VERSION ""

NS_ :

BS_:

BU_: CHUD_LS VKM_LS RCRM_LS MSM_RR_LS MSM_LR_LS CGM_LS BSM_LS VPM_LS ISRVM_LS DCAC_LS TouchPad_LS RSC_LS LVMPC_LS EOCM2B_K1_LS EOCM2A_K1_LS LCM_LS TIM_B_LS V2V_LS TCP_LS CSM_LS EOCM2B_K2_LS EOCM2A_K2_LS TIM_A_LS LVMNav_LS HFP_LS EDI_LS ARB_LS RSE_LS Dummy_LS VIS2_LS ICS_LS FCM_LS EOCM_F_LS VICM_LS AGC_LS MSM_P_LS OTIM_LS HVSM_R_LS HVSM_F_LS DVB_T_LS SBZA_R_LS PSD_R_LS PSD_L_LS UHP_Low UPA_LS STC_LS SBZA_L_LS PTM_LS ONSTAR_LS APA_LS TestTool_LS PHS_LS PDIM_LS CHM_LS RSA_LS AMP_LS HUD_LS MSM_LS HBSM_LS SCL_LS ECC_LS RadioHead_LS PEPS_LS IPC_LS AOS_LS SDM_LS TIM_LS BCM_LS

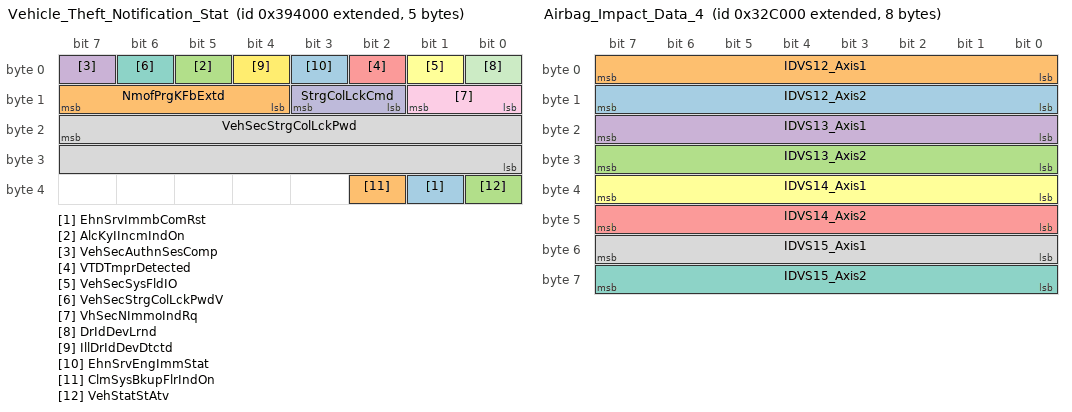
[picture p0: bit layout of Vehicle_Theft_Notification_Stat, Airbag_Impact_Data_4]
BO_ 2151235584 Vehicle_Theft_Notification_Stat: 5 BCM_LS
 SG_ EhnSrvImmbComRst : 33|1@0+ (1,0) [0|1] ""  TCP_LS,CGM_LS,ONSTAR_LS
 SG_ NmofPrgKFbExtd : 15|4@0+ (1,0) [0|15] ""  CGM_LS,PEPS_LS,IPC_LS
 SG_ AlcKyIIncmIndOn : 5|1@0+ (1,0) [0|1] ""  CGM_LS,IPC_LS
 SG_ VehSecAuthnSesComp : 7|1@0+ (1,0) [0|1] ""  TCP_LS,CGM_LS,ONSTAR_LS
 SG_ VTDTmprDetected : 2|1@0+ (1,0) [0|1] ""  TCP_LS,CGM_LS,ONSTAR_LS
 SG_ VehSecSysFldIO : 1|1@0+ (1,0) [0|1] ""  CGM_LS,IPC_LS
 SG_ VehSecStrgColLckPwdV : 6|1@0+ (1,0) [0|1] ""  CGM_LS,SCL_LS
 SG_ VehSecStrgColLckPwd : 23|16@0+ (1,0) [0|65535] ""  CGM_LS,SCL_LS
 SG_ VhSecNImmoIndRq : 9|2@0+ (1,0) [0|3] ""  CGM_LS,IPC_LS
 SG_ StrgColLckCmd : 11|2@0+ (1,0) [0|3] ""  CGM_LS,SCL_LS
 SG_ DrIdDevLrnd : 0|1@0+ (1,0) [0|1] ""  TCP_LS,CGM_LS,ONSTAR_LS
 SG_ IllDrIdDevDtctd : 4|1@0+ (1,0) [0|1] ""  TCP_LS,CGM_LS,ONSTAR_LS
 SG_ EhnSrvEngImmStat : 3|1@0+ (1,0) [0|1] ""  TCP_LS,CGM_LS,ONSTAR_LS
 SG_ ClmSysBkupFlrIndOn : 34|1@0+ (1,0) [0|1] ""  CGM_LS,IPC_LS
 SG_ VehStatStAtv : 32|1@0+ (1,0) [0|1] ""  CGM_LS,PEPS_LS

BO_ 2150809600 Airbag_Impact_Data_4: 8 SDM_LS
 SG_ IDVS12_Axis2 : 15|8@0- (1,0) [-128|127] "counts"  TCP_LS,CGM_LS,ONSTAR_LS
 SG_ IDVS12_Axis1 : 7|8@0- (1,0) [-128|127] "counts"  TCP_LS,CGM_LS,ONSTAR_LS
 SG_ IDVS13_Axis2 : 31|8@0- (1,0) [-128|127] "counts"  TCP_LS,CGM_LS,ONSTAR_LS
 SG_ IDVS13_Axis1 : 23|8@0- (1,0) [-128|127] "counts"  TCP_LS,CGM_LS,ONSTAR_LS
 SG_ IDVS14_Axis2 : 47|8@0- (1,0) [-128|127] "counts"  TCP_LS,CGM_LS,ONSTAR_LS
 SG_ IDVS14_Axis1 : 39|8@0- (1,0) [-128|127] "counts"  TCP_LS,CGM_LS,ONSTAR_LS
 SG_ IDVS15_Axis2 : 63|8@0- (1,0) [-128|127] "counts"  TCP_LS,CGM_LS,ONSTAR_LS
 SG_ IDVS15_Axis1 : 55|8@0- (1,0) [-128|127] "counts"  TCP_LS,CGM_LS,ONSTAR_LS

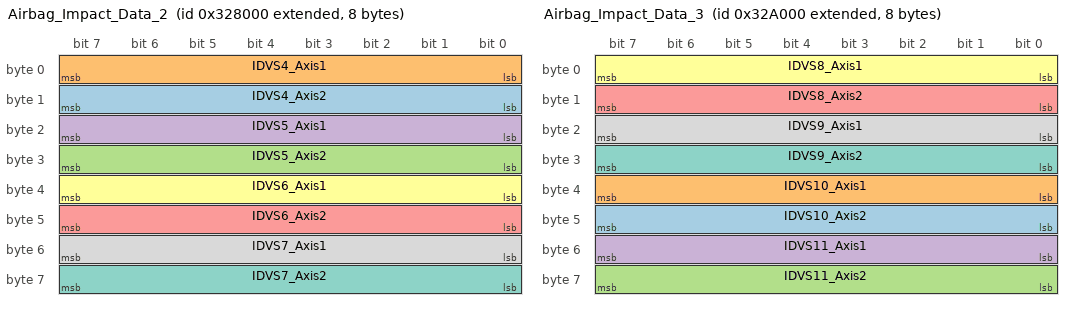
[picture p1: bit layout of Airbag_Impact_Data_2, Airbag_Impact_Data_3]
BO_ 2150793216 Airbag_Impact_Data_2: 8 SDM_LS
 SG_ IDVS4_Axis2 : 15|8@0- (1,0) [-128|127] "counts"  TCP_LS,CGM_LS,ONSTAR_LS
 SG_ IDVS4_Axis1 : 7|8@0- (1,0) [-128|127] "counts"  TCP_LS,CGM_LS,ONSTAR_LS
 SG_ IDVS5_Axis2 : 31|8@0- (1,0) [-128|127] "counts"  TCP_LS,CGM_LS,ONSTAR_LS
 SG_ IDVS5_Axis1 : 23|8@0- (1,0) [-128|127] "counts"  TCP_LS,CGM_LS,ONSTAR_LS
 SG_ IDVS6_Axis2 : 47|8@0- (1,0) [-128|127] "counts"  TCP_LS,CGM_LS,ONSTAR_LS
 SG_ IDVS6_Axis1 : 39|8@0- (1,0) [-128|127] "counts"  TCP_LS,CGM_LS,ONSTAR_LS
 SG_ IDVS7_Axis2 : 63|8@0- (1,0) [-128|127] "counts"  TCP_LS,CGM_LS,ONSTAR_LS
 SG_ IDVS7_Axis1 : 55|8@0- (1,0) [-128|127] "counts"  TCP_LS,CGM_LS,ONSTAR_LS

BO_ 2150801408 Airbag_Impact_Data_3: 8 SDM_LS
 SG_ IDVS10_Axis2 : 47|8@0- (1,0) [-128|127] "counts"  TCP_LS,CGM_LS,ONSTAR_LS
 SG_ IDVS10_Axis1 : 39|8@0- (1,0) [-128|127] "counts"  TCP_LS,CGM_LS,ONSTAR_LS
 SG_ IDVS11_Axis2 : 63|8@0- (1,0) [-128|127] "counts"  TCP_LS,CGM_LS,ONSTAR_LS
 SG_ IDVS11_Axis1 : 55|8@0- (1,0) [-128|127] "counts"  TCP_LS,CGM_LS,ONSTAR_LS
 SG_ IDVS8_Axis2 : 15|8@0- (1,0) [-128|127] "counts"  TCP_LS,CGM_LS,ONSTAR_LS
 SG_ IDVS8_Axis1 : 7|8@0- (1,0) [-128|127] "counts"  TCP_LS,CGM_LS,ONSTAR_LS
 SG_ IDVS9_Axis2 : 31|8@0- (1,0) [-128|127] "counts"  TCP_LS,CGM_LS,ONSTAR_LS
 SG_ IDVS9_Axis1 : 23|8@0- (1,0) [-128|127] "counts"  TCP_LS,CGM_LS,ONSTAR_LS

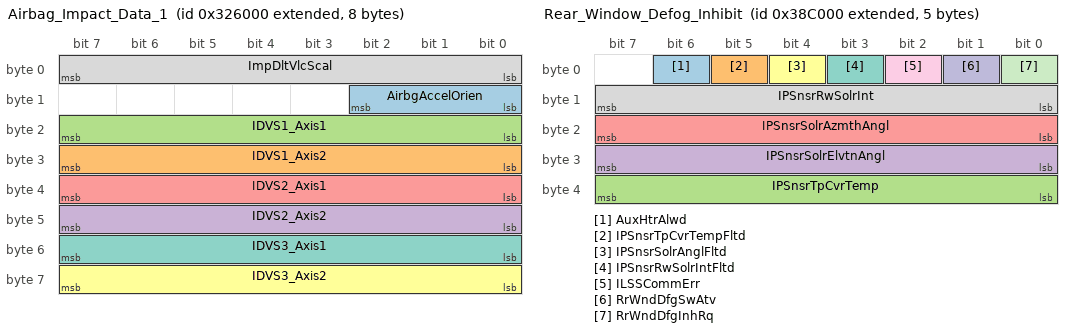
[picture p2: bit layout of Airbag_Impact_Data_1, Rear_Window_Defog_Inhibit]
BO_ 2150785024 Airbag_Impact_Data_1: 8 SDM_LS
 SG_ AirbgAccelOrien : 10|3@0+ (45,0) [0|315] "deg"  TCP_LS,CGM_LS,ONSTAR_LS
 SG_ IDVS1_Axis2 : 31|8@0- (1,0) [-128|127] "counts"  TCP_LS,CGM_LS,ONSTAR_LS
 SG_ IDVS1_Axis1 : 23|8@0- (1,0) [-128|127] "counts"  TCP_LS,CGM_LS,ONSTAR_LS
 SG_ IDVS2_Axis2 : 47|8@0- (1,0) [-128|127] "counts"  TCP_LS,CGM_LS,ONSTAR_LS
 SG_ IDVS2_Axis1 : 39|8@0- (1,0) [-128|127] "counts"  TCP_LS,CGM_LS,ONSTAR_LS
 SG_ IDVS3_Axis2 : 63|8@0- (1,0) [-128|127] "counts"  TCP_LS,CGM_LS,ONSTAR_LS
 SG_ IDVS3_Axis1 : 55|8@0- (1,0) [-128|127] "counts"  TCP_LS,CGM_LS,ONSTAR_LS
 SG_ ImpDltVlcScal : 7|8@0+ (0.00245,0.706) [0.706|1.33075] "kph/cnt"  TCP_LS,CGM_LS,ONSTAR_LS

BO_ 2151202816 Rear_Window_Defog_Inhibit: 5 BCM_LS
 SG_ AuxHtrAlwd : 6|1@0+ (1,0) [0|1] ""  CGM_LS,ECC_LS
 SG_ IPSnsrTpCvrTempFltd : 5|1@0+ (1,0) [0|1] ""  CGM_LS,ECC_LS
 SG_ IPSnsrTpCvrTemp : 39|8@0+ (0.5,-40) [-40|87.5] "deg C"  CGM_LS,ECC_LS
 SG_ IPSnsrSolrElvtnAngl : 31|8@0+ (1,0) [0|255] "deg"  CGM_LS,ECC_LS
 SG_ IPSnsrSolrAzmthAngl : 23|8@0+ (2,-180) [-180|330] "deg"  CGM_LS,ECC_LS
 SG_ IPSnsrSolrAnglFltd : 4|1@0+ (1,0) [0|1] ""  CGM_LS,ECC_LS
 SG_ IPSnsrRwSolrIntFltd : 3|1@0+ (1,0) [0|1] ""  CGM_LS,ECC_LS
 SG_ IPSnsrRwSolrInt : 15|8@0+ (3,0) [0|765] "W/m2"  CGM_LS,ECC_LS
 SG_ ILSSCommErr : 2|1@0+ (1,0) [0|1] ""  CGM_LS,ECC_LS
 SG_ RrWndDfgSwAtv : 1|1@0+ (1,0) [0|1] ""  CGM_LS,IPC_LS,ECC_LS
 SG_ RrWndDfgInhRq : 0|1@0+ (1,0) [0|1] ""  CGM_LS,ECC_LS

BO_ 2150825984 Airbag_Indications: 6 SDM_LS
 SG_ PdstIntdProtSysDplyd : 46|1@0+ (1,0) [0|1] ""  CGM_LS,IPC_LS
 SG_ PdstIntdProtSysDsbld : 45|1@0+ (1,0) [0|1] ""  CGM_LS,IPC_LS
 SG_ SrvIntdPdstProtSysIO : 44|1@0+ (1,0) [0|1] ""  CGM_LS,IPC_LS
 SG_ FstnThrdRwRtPsStbtInR : 41|2@0+ (1,0) [0|3] ""  CSM_LS,ONSTAR_LS,CGM_LS,IPC_LS
 SG_ FstnThrdRwLtPsStbtInR : 43|2@0+ (1,0) [0|3] ""  CSM_LS,ONSTAR_LS,CGM_LS,IPC_LS
 SG_ FstnThrdRwCtPsStbtInR : 39|2@0+ (1,0) [0|3] ""  CSM_LS,ONSTAR_LS,V2V_LS,CGM_LS,IPC_LS
 SG_ FPSIC_IndPer : 11|4@0+ (1,0) [0|15] ""  CSM_LS,TCP_LS,V2V_LS,CGM_LS,ONSTAR_LS,IPC_LS
 SG_ FPSIC_IO : 15|1@0+ (1,0) [0|1] ""  CSM_LS,TCP_LS,V2V_LS,CGM_LS,ONSTAR_LS,IPC_LS
 SG_ FPSIC_IndDtCyc : 14|3@0+ (12.5,12.5) [12.5|100] "%"  CSM_LS,TCP_LS,V2V_LS,CGM_LS,ONSTAR_LS,IPC_LS
 SG_ FDSIC_IndPer : 3|4@0+ (1,0) [0|15] ""  CSM_LS,TCP_LS,V2V_LS,CGM_LS,ONSTAR_LS,IPC_LS
 SG_ FDSIC_IO : 7|1@0+ (1,0) [0|1] ""  CSM_LS,TCP_LS,V2V_LS,CGM_LS,ONSTAR_LS,IPC_LS
 SG_ FDSIC_IndDC : 6|3@0+ (12.5,12.5) [12.5|100] "%"  CSM_LS,TCP_LS,V2V_LS,CGM_LS,ONSTAR_LS,IPC_LS
 SG_ AirbgFldIO : 35|1@0+ (1,0) [0|1] ""  TCP_LS,V2V_LS,CGM_LS,ONSTAR_LS,IPC_LS
 SG_ SndRwStbltRdIndMd : 37|2@0+ (1,0) [0|3] ""  CSM_LS,ONSTAR_LS,V2V_LS,CGM_LS,IPC_LS
 SG_ AirbgICIndPer : 19|4@0+ (1,0) [0|15] ""  CSM_LS,TCP_LS,CGM_LS,ONSTAR_LS,IPC_LS
 SG_ AirbgICDutCyc : 22|3@0+ (12.5,12.5) [12.5|100] "%"  CSM_LS,TCP_LS,CGM_LS,ONSTAR_LS,IPC_LS
 SG_ AirbgICIO : 23|1@0+ (1,0) [0|1] ""  CSM_LS,TCP_LS,CGM_LS,ONSTAR_LS,IPC_LS
 SG_ FstnSndRwRtPsStbtInR : 29|2@0+ (1,0) [0|3] ""  CSM_LS,ONSTAR_LS,V2V_LS,CGM_LS,IPC_LS
 SG_ FstnSndRwLtPsStbtInR : 25|2@0+ (1,0) [0|3] ""  CSM_LS,ONSTAR_LS,V2V_LS,CGM_LS,IPC_LS
 SG_ FstnSndRwCtPsStbtInR : 27|2@0+ (1,0) [0|3] ""  CSM_LS,ONSTAR_LS,CGM_LS,IPC_LS
 SG_ FsnDrStbAuxIR : 31|2@0+ (1,0) [0|3] ""  CGM_LS,IPC_LS
 SG_ FsnPsStbAuxIR : 34|3@0+ (1,0) [0|7] ""  CGM_LS,IPC_LS

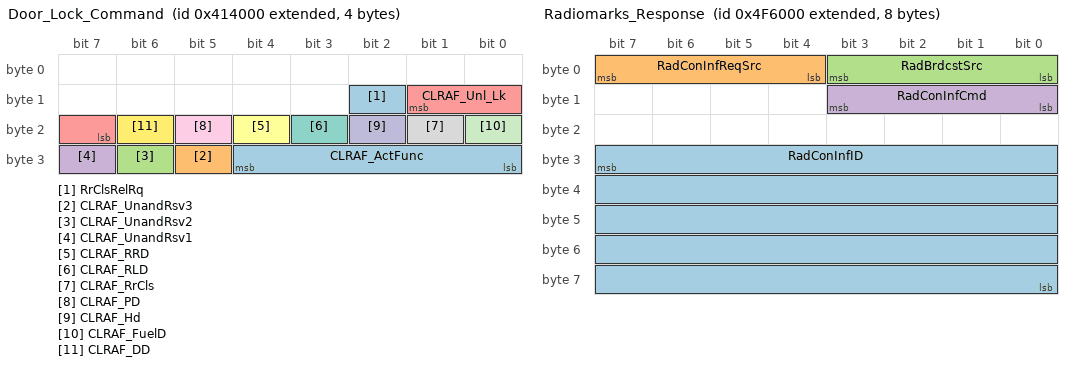
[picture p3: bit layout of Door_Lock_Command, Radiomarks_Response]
BO_ 2151759872 Door_Lock_Command: 4 BCM_LS
 SG_ RrClsRelRq : 10|1@0+ (1,0) [0|1] ""  CGM_LS,PEPS_LS,LCM_LS,PTM_LS
 SG_ CLRAF_UnandRsv3 : 29|1@0+ (1,0) [0|1] ""  VICM_LS,CGM_LS,ARB_LS,PSD_R_LS,PSD_L_LS,LCM_LS,PTM_LS,MSM_P_LS,MSM_LS
 SG_ CLRAF_UnandRsv2 : 30|1@0+ (1,0) [0|1] ""  VICM_LS,CGM_LS,ARB_LS,PSD_R_LS,PSD_L_LS,LCM_LS,PTM_LS,MSM_P_LS,MSM_LS
 SG_ CLRAF_UnandRsv1 : 31|1@0+ (1,0) [0|1] ""  VICM_LS,CGM_LS,ARB_LS,PSD_R_LS,PSD_L_LS,LCM_LS,PTM_LS,MSM_P_LS,MSM_LS
 SG_ CLRAF_Unl_Lk : 9|3@0+ (1,0) [0|7] ""  VICM_LS,CGM_LS,ARB_LS,PSD_R_LS,PSD_L_LS,LCM_LS,PTM_LS,MSM_P_LS,MSM_LS
 SG_ CLRAF_RRD : 20|1@0+ (1,0) [0|1] ""  VICM_LS,CGM_LS,ARB_LS,PSD_R_LS,PSD_L_LS,LCM_LS,PTM_LS,MSM_P_LS,MSM_LS
 SG_ CLRAF_RLD : 19|1@0+ (1,0) [0|1] ""  VICM_LS,CGM_LS,ARB_LS,PSD_R_LS,PSD_L_LS,LCM_LS,PTM_LS,MSM_P_LS,MSM_LS
 SG_ CLRAF_RrCls : 17|1@0+ (1,0) [0|1] ""  VICM_LS,CGM_LS,ARB_LS,PSD_R_LS,PSD_L_LS,LCM_LS,PTM_LS,MSM_P_LS,MSM_LS
 SG_ CLRAF_PD : 21|1@0+ (1,0) [0|1] ""  VICM_LS,CGM_LS,ARB_LS,PSD_R_LS,PSD_L_LS,LCM_LS,PTM_LS,MSM_P_LS,MSM_LS
 SG_ CLRAF_Hd : 18|1@0+ (1,0) [0|1] ""  VICM_LS,CGM_LS,ARB_LS,PSD_R_LS,PSD_L_LS,LCM_LS,PTM_LS,MSM_P_LS,MSM_LS
 SG_ CLRAF_FuelD : 16|1@0+ (1,0) [0|1] ""  VICM_LS,CGM_LS,ARB_LS,PSD_R_LS,PSD_L_LS,LCM_LS,PTM_LS,MSM_P_LS,MSM_LS
 SG_ CLRAF_DD : 22|1@0+ (1,0) [0|1] ""  VICM_LS,CGM_LS,ARB_LS,PSD_R_LS,PSD_L_LS,LCM_LS,PTM_LS,MSM_P_LS,MSM_LS
 SG_ CLRAF_ActFunc : 28|5@0+ (1,0) [0|31] ""  VICM_LS,CGM_LS,ARB_LS,PSD_R_LS,PSD_L_LS,LCM_LS,PTM_LS,MSM_P_LS,MSM_LS

BO_ 2149974016 Content_Theft_Sensor_Status: 3 BCM_LS
 SG_ IntrSnsDisbld : 1|1@0+ (1,0) [0|1] ""  CGM_LS,IPC_LS
 SG_ AlrmStat : 18|3@0+ (1,0) [0|7] ""  VPM_LS,TCP_LS,CGM_LS,PSD_R_LS,PSD_L_LS,BSM_LS,VICM_LS,ONSTAR_LS,LCM_LS,PTM_LS
 SG_ AlrmTrggrdBattRcnctd : 11|1@0+ (1,0) [0|1] ""  TCP_LS,CGM_LS,ONSTAR_LS
 SG_ AlrmTrgDrvDr : 3|1@0+ (1,0) [0|1] ""  TCP_LS,CGM_LS,ONSTAR_LS
 SG_ AlrmTrgGlsBrkSns : 12|1@0+ (1,0) [0|1] ""  TCP_LS,CGM_LS,ONSTAR_LS
 SG_ AlrmTrgHd : 21|1@0+ (1,0) [0|1] ""  TCP_LS,CGM_LS,ONSTAR_LS
 SG_ AlrmTrgdIO : 15|1@0+ (1,0) [0|1] ""  CGM_LS,IPC_LS
 SG_ AlrmTrgIntMvmntSns : 10|1@0+ (1,0) [0|1] ""  TCP_LS,CGM_LS,ONSTAR_LS
 SG_ AlrmTrgNonOffPM : 13|1@0+ (1,0) [0|1] ""  CGM_LS
 SG_ AlrmTrgPsngDr : 4|1@0+ (1,0) [0|1] ""  TCP_LS,CGM_LS,ONSTAR_LS
 SG_ AlrmTrgRrLftDr : 6|1@0+ (1,0) [0|1] ""  TCP_LS,CGM_LS,ONSTAR_LS
 SG_ AlrmTrgRrRtDr : 5|1@0+ (1,0) [0|1] ""  TCP_LS,CGM_LS,ONSTAR_LS
 SG_ AlrmTrgTltSns : 9|1@0+ (1,0) [0|1] ""  TCP_LS,CGM_LS,ONSTAR_LS
 SG_ AlrmTrgTrnk : 8|1@0+ (1,0) [0|1] ""  TCP_LS,CGM_LS,ONSTAR_LS
 SG_ SrvAlrmSysIO : 0|1@0+ (1,0) [0|1] ""  TCP_LS,CGM_LS,ONSTAR_LS,IPC_LS
 SG_ AlrmTrigMidClsr : 14|1@0+ (1,0) [0|1] ""  TCP_LS,CGM_LS,ONSTAR_LS
 SG_ AlrmTrigTonn : 7|1@0+ (1,0) [0|1] ""  CGM_LS

BO_ 2151907328 Steering_Wheel_Control_Switches: 1 BCM_LS
 SG_ StrgWhlUnit1SwStat : 3|4@0+ (1,0) [0|15] ""  CGM_LS,LVMPC_LS,EDI_LS,RadioHead_LS
 SG_ StrgWhlUnit2SwStat : 7|4@0+ (1,0) [0|15] ""  CGM_LS,LVMPC_LS,EDI_LS,RadioHead_LS

BO_ 1579 VNMF_LS_62B_FCM: 8 EOCM_F_LS
 SG_ VectraSpcNWMgtD : 7|64@0+ (1,0) [0|1.84467440737096E+019] ""  TCP_LS,LVMNav_LS,UHP_Low,ONSTAR_LS,TIM_B_LS,RSE_LS,RSA_LS,HVSM_F_LS,MSM_LS,BCM_LS,AOS_LS,AMP_LS,BSM_LS,VICM_LS,HFP_LS,PDIM_LS,SBZA_R_LS,ICS_LS,MSM_LR_LS,LCM_LS,HVSM_R_LS,DCAC_LS,AGC_LS,VKM_LS,RSC_LS,PSD_R_LS,CHUD_LS,MSM_RR_LS,LVMPC_LS,PSD_L_LS,TouchPad_LS,DVB_T_LS,MSM_P_LS,OTIM_LS,EOCM2B_K2_LS,PHS_LS,V2V_LS,ARB_LS,SDM_LS,SCL_LS,SBZA_L_LS,CSM_LS,CHM_LS,RadioHead_LS,STC_LS,PTM_LS,PEPS_LS,CGM_LS,TIM_LS,TIM_A_LS,VIS2_LS,TestTool_LS,IPC_LS,VPM_LS,HUD_LS,RCRM_LS,ISRVM_LS,HBSM_LS,ECC_LS,UPA_LS,APA_LS

BO_ 1599 VNMF_LS_63F_HBSM: 8 CGM_LS
 SG_ VectraSpcNWMgtD : 7|64@0+ (1,0) [0|1.84467440737096E+019] ""  TCP_LS,LVMNav_LS,UHP_Low,ONSTAR_LS,TIM_B_LS,RSE_LS,RSA_LS,HVSM_F_LS,MSM_LS,BCM_LS,AOS_LS,AMP_LS,BSM_LS,VICM_LS,HFP_LS,PDIM_LS,SBZA_R_LS,MSM_LR_LS,LCM_LS,HVSM_R_LS,EOCM2A_K2_LS,FCM_LS,EOCM_F_LS,EOCM2B_K2_LS,PHS_LS,ICS_LS,VKM_LS,RSC_LS,PSD_R_LS,CHUD_LS,MSM_RR_LS,LVMPC_LS,PSD_L_LS,DCAC_LS,AGC_LS,TouchPad_LS,DVB_T_LS,SDM_LS,SCL_LS,SBZA_L_LS,CSM_LS,CHM_LS,RadioHead_LS,STC_LS,PTM_LS,PEPS_LS,CGM_LS,TIM_LS,TIM_A_LS,VIS2_LS,TestTool_LS,IPC_LS,VPM_LS,HUD_LS,ECC_LS,V2V_LS,ARB_LS,UPA_LS,APA_LS,MSM_P_LS,OTIM_LS

BO_ 1583 VNMF_LS_62F_PTM_STC: 8 PTM_LS
 SG_ VectraSpcNWMgtD : 7|64@0+ (1,0) [0|1.84467440737096E+019] ""  TCP_LS,LVMNav_LS,UHP_Low,ONSTAR_LS,TIM_B_LS,RSE_LS,RSA_LS,HVSM_F_LS,MSM_LS,BCM_LS,AOS_LS,AMP_LS,BSM_LS,VICM_LS,HFP_LS,PDIM_LS,SBZA_R_LS,MSM_LR_LS,LCM_LS,HVSM_R_LS,EOCM2A_K2_LS,FCM_LS,EOCM_F_LS,ICS_LS,VKM_LS,RSC_LS,PSD_R_LS,DCAC_LS,AGC_LS,CHUD_LS,MSM_RR_LS,LVMPC_LS,PSD_L_LS,TouchPad_LS,DVB_T_LS,EOCM2B_K2_LS,PHS_LS,V2V_LS,ARB_LS,SDM_LS,SCL_LS,SBZA_L_LS,CSM_LS,CHM_LS,RadioHead_LS,PEPS_LS,MSM_P_LS,OTIM_LS,CGM_LS,TIM_LS,TIM_A_LS,VIS2_LS,TestTool_LS,IPC_LS,VPM_LS,HUD_LS,RCRM_LS,ISRVM_LS,HBSM_LS,ECC_LS,UPA_LS,APA_LS

BO_ 1585 VNMF_LS_631_ECC_HVAC: 8 ECC_LS
 SG_ VectraSpcNWMgtD : 7|64@0+ (1,0) [0|1.84467440737096E+019] ""  TCP_LS,LVMNav_LS,UHP_Low,ONSTAR_LS,TIM_B_LS,RSE_LS,RSA_LS,HVSM_F_LS,MSM_LS,BCM_LS,AOS_LS,AMP_LS,BSM_LS,VICM_LS,HFP_LS,PDIM_LS,SBZA_R_LS,MSM_LR_LS,LCM_LS,HVSM_R_LS,EOCM2A_K2_LS,FCM_LS,EOCM_F_LS,ICS_LS,VKM_LS,RSC_LS,PSD_R_LS,DCAC_LS,AGC_LS,CHUD_LS,MSM_RR_LS,LVMPC_LS,PSD_L_LS,TouchPad_LS,DVB_T_LS,EOCM2B_K2_LS,PHS_LS,V2V_LS,ARB_LS,SDM_LS,SCL_LS,SBZA_L_LS,CSM_LS,CHM_LS,RadioHead_LS,STC_LS,PTM_LS,PEPS_LS,MSM_P_LS,OTIM_LS,CGM_LS,TIM_LS,TIM_A_LS,VIS2_LS,TestTool_LS,IPC_LS,VPM_LS,HUD_LS,RCRM_LS,ISRVM_LS,HBSM_LS,UPA_LS,APA_LS

BO_ 1586 VNMF_LS_632_DVB_T: 8 DVB_T_LS
 SG_ VectraSpcNWMgtD : 7|64@0+ (1,0) [0|1.84467440737096E+019] ""  TCP_LS,LVMNav_LS,UHP_Low,ONSTAR_LS,TIM_B_LS,RSE_LS,RSA_LS,HVSM_F_LS,MSM_LS,BCM_LS,AOS_LS,AMP_LS,BSM_LS,VICM_LS,HFP_LS,PDIM_LS,SBZA_R_LS,MSM_LR_LS,LCM_LS,HVSM_R_LS,EOCM2A_K2_LS,FCM_LS,EOCM_F_LS,ICS_LS,VKM_LS,RSC_LS,PSD_R_LS,DCAC_LS,AGC_LS,CHUD_LS,MSM_RR_LS,LVMPC_LS,PSD_L_LS,EOCM2B_K2_LS,PHS_LS,V2V_LS,ARB_LS,SDM_LS,SCL_LS,SBZA_L_LS,CSM_LS,CHM_LS,RadioHead_LS,STC_LS,PTM_LS,PEPS_LS,MSM_P_LS,OTIM_LS,CGM_LS,TIM_LS,TIM_A_LS,VIS2_LS,TestTool_LS,IPC_LS,VPM_LS,HUD_LS,RCRM_LS,ISRVM_LS,HBSM_LS,ECC_LS,UPA_LS,APA_LS

BO_ 1591 VNMF_LS_637_SBZA_R: 8 SBZA_R_LS
 SG_ VectraSpcNWMgtD : 7|64@0+ (1,0) [0|1.84467440737096E+019] ""  TCP_LS,LVMNav_LS,UHP_Low,ONSTAR_LS,TIM_B_LS,RSE_LS,RSA_LS,HVSM_F_LS,MSM_LS,BCM_LS,AOS_LS,AMP_LS,BSM_LS,VICM_LS,HFP_LS,PDIM_LS,TestTool_LS,MSM_LR_LS,LCM_LS,HVSM_R_LS,EOCM2A_K2_LS,FCM_LS,EOCM_F_LS,ICS_LS,CGM_LS,TIM_LS,SBZA_L_LS,CSM_LS,CHM_LS,RadioHead_LS,STC_LS,PTM_LS,VKM_LS,RSC_LS,PSD_R_LS,DCAC_LS,AGC_LS,TIM_A_LS,VIS2_LS,SDM_LS,SCL_LS,CHUD_LS,MSM_RR_LS,LVMPC_LS,PSD_L_LS,PEPS_LS,IPC_LS,VPM_LS,HUD_LS,RCRM_LS,ISRVM_LS,HBSM_LS,ECC_LS,TouchPad_LS,DVB_T_LS,UPA_LS,APA_LS,EOCM2B_K2_LS,PHS_LS,V2V_LS,ARB_LS,MSM_P_LS,OTIM_LS

BO_ 1572 VNMF_LS_624_RadioHead_CHM: 8 RadioHead_LS
 SG_ VectraSpcNWMgtD : 7|64@0+ (1,0) [0|1.84467440737096E+019] ""  TCP_LS,LVMNav_LS,UHP_Low,ONSTAR_LS,TIM_B_LS,RSE_LS,RSA_LS,HVSM_F_LS,MSM_LS,BCM_LS,AOS_LS,AMP_LS,V2V_LS,ARB_LS,BSM_LS,VICM_LS,HFP_LS,PDIM_LS,SBZA_R_LS,ICS_LS,EOCM2A_K2_LS,FCM_LS,EOCM_F_LS,MSM_LR_LS,LCM_LS,HVSM_R_LS,VKM_LS,RSC_LS,PSD_R_LS,DCAC_LS,AGC_LS,CHUD_LS,MSM_RR_LS,LVMPC_LS,PSD_L_LS,TouchPad_LS,DVB_T_LS,EOCM2B_K2_LS,PHS_LS,SDM_LS,SCL_LS,SBZA_L_LS,STC_LS,PTM_LS,PEPS_LS,MSM_P_LS,OTIM_LS,CGM_LS,TIM_LS,TIM_A_LS,VIS2_LS,TestTool_LS,IPC_LS,VPM_LS,HUD_LS,RCRM_LS,ISRVM_LS,HBSM_LS,ECC_LS,UPA_LS,APA_LS

BO_ 1578 VNMF_LS_62A_PSD_L: 8 PSD_L_LS
 SG_ VectraSpcNWMgtD : 7|64@0+ (1,0) [0|1.84467440737096E+019] ""  TCP_LS,LVMNav_LS,UHP_Low,ONSTAR_LS,TIM_B_LS,RSE_LS,RSA_LS,HVSM_F_LS,MSM_LS,BCM_LS,AOS_LS,AMP_LS,BSM_LS,VICM_LS,HFP_LS,PDIM_LS,SBZA_R_LS,ICS_LS,EOCM2A_K2_LS,FCM_LS,EOCM_F_LS,MSM_LR_LS,LCM_LS,HVSM_R_LS,VKM_LS,RSC_LS,PSD_R_LS,DCAC_LS,AGC_LS,TouchPad_LS,DVB_T_LS,EOCM2B_K2_LS,PHS_LS,V2V_LS,ARB_LS,SDM_LS,SCL_LS,SBZA_L_LS,CSM_LS,CHM_LS,RadioHead_LS,STC_LS,PTM_LS,PEPS_LS,MSM_P_LS,OTIM_LS,CGM_LS,TIM_LS,TIM_A_LS,VIS2_LS,TestTool_LS,IPC_LS,VPM_LS,HUD_LS,RCRM_LS,ISRVM_LS,HBSM_LS,ECC_LS,UPA_LS,APA_LS

BO_ 1597 VNMF_LS_63D_DSM_HVSM_F: 8 MSM_LS
 SG_ VectraSpcNWMgtD : 7|64@0+ (1,0) [0|1.84467440737096E+019] ""  TCP_LS,LVMNav_LS,UHP_Low,ONSTAR_LS,TIM_B_LS,RSE_LS,RSA_LS,BCM_LS,AOS_LS,AMP_LS,BSM_LS,VICM_LS,HFP_LS,PDIM_LS,SBZA_R_LS,MSM_LR_LS,LCM_LS,HVSM_R_LS,EOCM2A_K2_LS,FCM_LS,EOCM_F_LS,EOCM2B_K2_LS,PHS_LS,ICS_LS,VKM_LS,RSC_LS,PSD_R_LS,CHUD_LS,MSM_RR_LS,LVMPC_LS,PSD_L_LS,DCAC_LS,AGC_LS,TouchPad_LS,DVB_T_LS,V2V_LS,ARB_LS,SDM_LS,SCL_LS,SBZA_L_LS,CSM_LS,CHM_LS,RadioHead_LS,STC_LS,PTM_LS,PEPS_LS,CGM_LS,TIM_LS,TIM_A_LS,VIS2_LS,MSM_P_LS,OTIM_LS,TestTool_LS,IPC_LS,VPM_LS,HUD_LS,RCRM_LS,ISRVM_LS,HBSM_LS,ECC_LS,UPA_LS,APA_LS

BO_ 1598 VNMF_LS_63E_AHS: 8 PHS_LS
 SG_ VectraSpcNWMgtD : 7|64@0+ (1,0) [0|1.84467440737096E+019] ""  TCP_LS,LVMNav_LS,UHP_Low,ONSTAR_LS,TIM_B_LS,RSE_LS,RSA_LS,HVSM_F_LS,MSM_LS,BCM_LS,AOS_LS,AMP_LS,BSM_LS,VICM_LS,HFP_LS,PDIM_LS,SBZA_R_LS,ICS_LS,EOCM2A_K2_LS,FCM_LS,EOCM_F_LS,MSM_LR_LS,LCM_LS,HVSM_R_LS,VKM_LS,RSC_LS,PSD_R_LS,CHUD_LS,MSM_RR_LS,LVMPC_LS,PSD_L_LS,DCAC_LS,AGC_LS,TouchPad_LS,DVB_T_LS,SDM_LS,SCL_LS,SBZA_L_LS,CSM_LS,CHM_LS,RadioHead_LS,STC_LS,PTM_LS,PEPS_LS,MSM_P_LS,OTIM_LS,CGM_LS,TIM_LS,TIM_A_LS,VIS2_LS,TestTool_LS,IPC_LS,VPM_LS,HUD_LS,RCRM_LS,ISRVM_LS,HBSM_LS,ECC_LS,V2V_LS,ARB_LS,UPA_LS,APA_LS

BO_ 1576 VNMF_LS_628_PDIM: 8 PDIM_LS
 SG_ VectraSpcNWMgtD : 7|64@0+ (1,0) [0|1.84467440737096E+019] ""  TCP_LS,LVMNav_LS,UHP_Low,ONSTAR_LS,TIM_B_LS,RSE_LS,RSA_LS,HVSM_F_LS,MSM_LS,BCM_LS,AOS_LS,AMP_LS,BSM_LS,VICM_LS,SBZA_R_LS,ICS_LS,EOCM2A_K2_LS,FCM_LS,EOCM_F_LS,MSM_LR_LS,LCM_LS,HVSM_R_LS,V2V_LS,ARB_LS,VKM_LS,RSC_LS,PSD_R_LS,CHUD_LS,MSM_RR_LS,LVMPC_LS,PSD_L_LS,DCAC_LS,AGC_LS,TouchPad_LS,DVB_T_LS,EOCM2B_K2_LS,PHS_LS,SDM_LS,SCL_LS,SBZA_L_LS,CSM_LS,CHM_LS,RadioHead_LS,STC_LS,PTM_LS,PEPS_LS,MSM_P_LS,OTIM_LS,CGM_LS,TIM_LS,TIM_A_LS,VIS2_LS,TestTool_LS,IPC_LS,VPM_LS,HUD_LS,RCRM_LS,ISRVM_LS,HBSM_LS,ECC_LS,UPA_LS,APA_LS

BO_ 1582 VNMF_LS_62E_PSD_R: 8 PSD_R_LS
 SG_ VectraSpcNWMgtD : 7|64@0+ (1,0) [0|1.84467440737096E+019] ""  TCP_LS,LVMNav_LS,UHP_Low,ONSTAR_LS,TIM_B_LS,RSE_LS,RSA_LS,HVSM_F_LS,MSM_LS,BCM_LS,AOS_LS,AMP_LS,BSM_LS,VICM_LS,HFP_LS,PDIM_LS,SBZA_R_LS,MSM_LR_LS,LCM_LS,HVSM_R_LS,ICS_LS,EOCM2A_K2_LS,FCM_LS,EOCM_F_LS,DCAC_LS,AGC_LS,CHUD_LS,MSM_RR_LS,LVMPC_LS,PSD_L_LS,TouchPad_LS,DVB_T_LS,EOCM2B_K2_LS,PHS_LS,V2V_LS,ARB_LS,SDM_LS,SCL_LS,SBZA_L_LS,CSM_LS,CHM_LS,RadioHead_LS,STC_LS,PTM_LS,PEPS_LS,MSM_P_LS,OTIM_LS,CGM_LS,TIM_LS,TIM_A_LS,VIS2_LS,TestTool_LS,IPC_LS,VPM_LS,HUD_LS,RCRM_LS,ISRVM_LS,HBSM_LS,ECC_LS,UPA_LS,APA_LS

BO_ 1590 VNMF_LS_636_RSA_RSE: 8 RSA_LS
 SG_ VectraSpcNWMgtD : 7|64@0+ (1,0) [0|1.84467440737096E+019] ""  TCP_LS,LVMNav_LS,UHP_Low,ONSTAR_LS,HVSM_F_LS,MSM_LS,BCM_LS,AOS_LS,AMP_LS,BSM_LS,VICM_LS,HFP_LS,PDIM_LS,SBZA_R_LS,MSM_LR_LS,LCM_LS,HVSM_R_LS,EOCM2A_K2_LS,FCM_LS,EOCM_F_LS,ICS_LS,VKM_LS,RSC_LS,PSD_R_LS,DCAC_LS,AGC_LS,CHUD_LS,MSM_RR_LS,LVMPC_LS,PSD_L_LS,TouchPad_LS,DVB_T_LS,EOCM2B_K2_LS,PHS_LS,V2V_LS,ARB_LS,SDM_LS,SCL_LS,SBZA_L_LS,CSM_LS,CHM_LS,RadioHead_LS,STC_LS,PTM_LS,PEPS_LS,MSM_P_LS,OTIM_LS,CGM_LS,TIM_LS,TIM_A_LS,VIS2_LS,TestTool_LS,IPC_LS,VPM_LS,HUD_LS,RCRM_LS,ISRVM_LS,HBSM_LS,ECC_LS,UPA_LS,APA_LS

BO_ 1592 VNMF_LS_638_HVSM_R: 8 HVSM_R_LS
 SG_ VectraSpcNWMgtD : 7|64@0+ (1,0) [0|1.84467440737096E+019] ""  TCP_LS,LVMNav_LS,UHP_Low,ONSTAR_LS,TIM_B_LS,RSE_LS,RSA_LS,HVSM_F_LS,MSM_LS,BCM_LS,AOS_LS,AMP_LS,BSM_LS,VICM_LS,HFP_LS,PDIM_LS,SBZA_R_LS,EOCM2A_K2_LS,FCM_LS,EOCM_F_LS,EOCM2B_K2_LS,PHS_LS,ICS_LS,VKM_LS,RSC_LS,PSD_R_LS,CHUD_LS,MSM_RR_LS,LVMPC_LS,PSD_L_LS,DCAC_LS,AGC_LS,TouchPad_LS,DVB_T_LS,V2V_LS,ARB_LS,SDM_LS,SCL_LS,SBZA_L_LS,CSM_LS,CHM_LS,RadioHead_LS,STC_LS,PTM_LS,PEPS_LS,CGM_LS,TIM_LS,TIM_A_LS,VIS2_LS,TestTool_LS,IPC_LS,VPM_LS,HUD_LS,RCRM_LS,ISRVM_LS,HBSM_LS,ECC_LS,MSM_P_LS,OTIM_LS,UPA_LS,APA_LS

BO_ 1594 VNMF_LS_63A_SBZA_L: 8 SBZA_L_LS
 SG_ VectraSpcNWMgtD : 7|64@0+ (1,0) [0|1.84467440737096E+019] ""  TCP_LS,LVMNav_LS,UHP_Low,ONSTAR_LS,TIM_B_LS,RSE_LS,RSA_LS,HVSM_F_LS,MSM_LS,BCM_LS,AOS_LS,AMP_LS,BSM_LS,VICM_LS,HFP_LS,PDIM_LS,SBZA_R_LS,MSM_LR_LS,LCM_LS,HVSM_R_LS,EOCM2A_K2_LS,FCM_LS,EOCM_F_LS,ICS_LS,EOCM2B_K2_LS,PHS_LS,VKM_LS,RSC_LS,PSD_R_LS,DCAC_LS,AGC_LS,CHUD_LS,MSM_RR_LS,LVMPC_LS,PSD_L_LS,TouchPad_LS,DVB_T_LS,V2V_LS,ARB_LS,SDM_LS,SCL_LS,CSM_LS,CHM_LS,RadioHead_LS,STC_LS,PTM_LS,PEPS_LS,MSM_P_LS,OTIM_LS,CGM_LS,TIM_LS,TIM_A_LS,VIS2_LS,TestTool_LS,IPC_LS,VPM_LS,HUD_LS,RCRM_LS,ISRVM_LS,HBSM_LS,ECC_LS,UPA_LS,APA_LS

BO_ 1595 VNMF_LS_ARB: 8 ARB_LS
 SG_ VectraSpcNWMgtD : 7|64@0+ (1,0) [0|1.84467440737096E+019] ""  ICS_LS,TCP_LS,LVMNav_LS,UHP_Low,ONSTAR_LS,TestTool_LS,CGM_LS,TIM_LS,SDM_LS,SCL_LS,SBZA_R_LS,SBZA_L_LS,BSM_LS,VICM_LS,CSM_LS,CHM_LS,RadioHead_LS,TIM_B_LS,RSE_LS,RSA_LS,STC_LS,PTM_LS,VKM_LS,RSC_LS,PSD_R_LS,CHUD_LS,MSM_RR_LS,LVMPC_LS,PSD_L_LS,PEPS_LS,HFP_LS,PDIM_LS,MSM_P_LS,OTIM_LS,HVSM_F_LS,MSM_LS,EOCM2A_K2_LS,FCM_LS,EOCM_F_LS,IPC_LS,MSM_LR_LS,LCM_LS,HVSM_R_LS,VPM_LS,HUD_LS,RCRM_LS,ISRVM_LS,HBSM_LS,ECC_LS,TouchPad_LS,DVB_T_LS,BCM_LS,UPA_LS,APA_LS,AOS_LS,AMP_LS,EOCM2B_K2_LS,PHS_LS,DCAC_LS,AGC_LS,TIM_A_LS,VIS2_LS

BO_ 1593 VNMF_LS_639_APA_UPA: 8 APA_LS
 SG_ VectraSpcNWMgtD : 7|64@0+ (1,0) [0|1.84467440737096E+019] ""  TCP_LS,LVMNav_LS,UHP_Low,ONSTAR_LS,TIM_B_LS,RSE_LS,RSA_LS,HVSM_F_LS,MSM_LS,BCM_LS,AOS_LS,AMP_LS,BSM_LS,VICM_LS,HFP_LS,PDIM_LS,SBZA_R_LS,MSM_LR_LS,LCM_LS,HVSM_R_LS,EOCM2A_K2_LS,FCM_LS,EOCM_F_LS,ICS_LS,VKM_LS,RSC_LS,PSD_R_LS,DCAC_LS,AGC_LS,CHUD_LS,MSM_RR_LS,LVMPC_LS,PSD_L_LS,TouchPad_LS,DVB_T_LS,EOCM2B_K2_LS,PHS_LS,V2V_LS,ARB_LS,SDM_LS,SCL_LS,SBZA_L_LS,CSM_LS,CHM_LS,RadioHead_LS,STC_LS,PTM_LS,PEPS_LS,MSM_P_LS,OTIM_LS,CGM_LS,TIM_LS,TIM_A_LS,VIS2_LS,TestTool_LS,IPC_LS,VPM_LS,HUD_LS,RCRM_LS,ISRVM_LS,HBSM_LS,ECC_LS

BO_ 1589 VNMF_LS_635_VIS2: 8 VIS2_LS
 SG_ VectraSpcNWMgtD : 7|64@0+ (1,0) [0|1.84467440737096E+019] ""  TCP_LS,LVMNav_LS,UHP_Low,ONSTAR_LS,TIM_B_LS,RSE_LS,RSA_LS,HVSM_F_LS,MSM_LS,BCM_LS,AOS_LS,AMP_LS,BSM_LS,VICM_LS,HFP_LS,PDIM_LS,SBZA_R_LS,ICS_LS,EOCM2A_K2_LS,FCM_LS,EOCM_F_LS,MSM_LR_LS,LCM_LS,HVSM_R_LS,VKM_LS,RSC_LS,PSD_R_LS,CHUD_LS,MSM_RR_LS,LVMPC_LS,PSD_L_LS,DCAC_LS,AGC_LS,TouchPad_LS,DVB_T_LS,EOCM2B_K2_LS,PHS_LS,V2V_LS,ARB_LS,SDM_LS,SCL_LS,SBZA_L_LS,CSM_LS,CHM_LS,RadioHead_LS,STC_LS,PTM_LS,PEPS_LS,MSM_P_LS,OTIM_LS,CGM_LS,TIM_LS,TestTool_LS,IPC_LS,VPM_LS,HUD_LS,RCRM_LS,ISRVM_LS,HBSM_LS,ECC_LS,UPA_LS,APA_LS

BO_ 2150219776 Voice_Recognition_Status: 1 RadioHead_LS
 SG_ PhnSpRcgnRq : 1|2@0+ (1,0) [0|3] ""  CGM_LS,UHP_Low,ONSTAR_LS
 SG_ VcRecVcFdbckSt : 3|2@0+ (1,0) [0|3] ""  CGM_LS,UHP_Low

BO_ 589 USDT_Req_to_UHP_ONS_LS: 8 TestTool_LS
 SG_ DgnInf : 7|64@0+ (1,0) [0|1.84467440737096E+019] ""  CGM_LS,TCP_LS,LVMNav_LS,UHP_Low,ONSTAR_LS

BO_ 2152685568 Radiomarks_Response: 8 RadioHead_LS
 SG_ RadConInfID : 31|40@0+ (1,0) [0|1099511627775] ""  CGM_LS,ONSTAR_LS
 SG_ RadConInfReqSrc : 7|4@0+ (1,0) [0|15] ""  CGM_LS,ONSTAR_LS
 SG_ RadBrdcstSrc : 3|4@0+ (1,0) [0|15] ""  CGM_LS,ONSTAR_LS
 SG_ RadConInfCmd : 11|4@0+ (1,0) [0|15] ""  CGM_LS,ONSTAR_LS

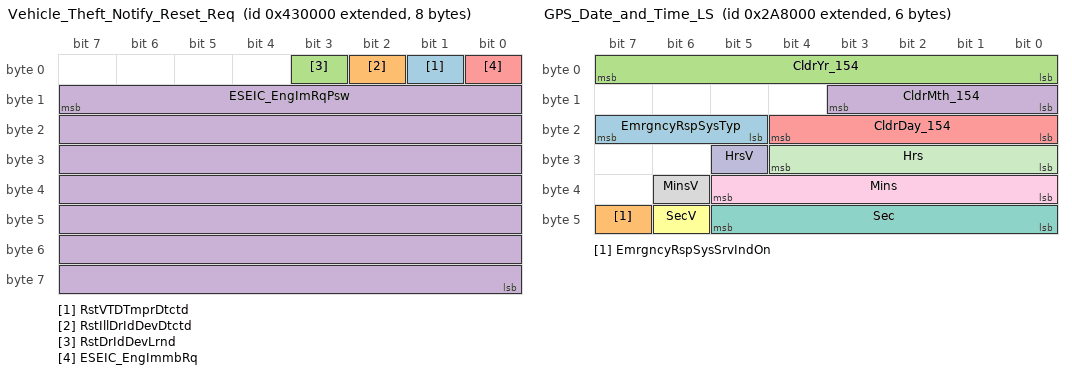
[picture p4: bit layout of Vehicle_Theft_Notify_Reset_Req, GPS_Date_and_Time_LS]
BO_ 2151874560 Vehicle_Theft_Notify_Reset_Req: 8 CGM_LS
 SG_ RstVTDTmprDtctd : 1|1@0+ (1,0) [0|1] ""  BCM_LS
 SG_ RstIllDrIdDevDtctd : 2|1@0+ (1,0) [0|1] ""  BCM_LS
 SG_ RstDrIdDevLrnd : 3|1@0+ (1,0) [0|1] ""  BCM_LS
 SG_ ESEIC_EngImRqPsw : 15|56@0+ (1,0) [0|1] ""  BCM_LS
 SG_ ESEIC_EngImmbRq : 0|1@0+ (1,0) [0|1] ""  BCM_LS

BO_ 1357 UUDT_Resp_From_UHP_ONS_LS: 8 CGM_LS
 SG_ DgnInf_LS54D : 7|64@0+ (1,0) [0|1.84467440737096E+019] ""  CGM_LS,CSM_LS,TestTool_LS

BO_ 1613 USDT_Resp_From_UHP_ONS_LS: 8 CGM_LS
 SG_ DgnInf : 7|64@0+ (1,0) [0|1.84467440737096E+019] ""  CGM_LS,CSM_LS,TestTool_LS

BO_ 2150268928 GPS_Date_and_Time_LS: 6 ONSTAR_LS
 SG_ EmrgncyRspSysTyp : 23|3@0+ (1,0) [0|7] ""  CGM_LS,IPC_LS
 SG_ EmrgncyRspSysSrvIndOn : 47|1@0+ (1,0) [0|1] ""  CGM_LS,IPC_LS
 SG_ CldrYr_154 : 7|8@0+ (1,2000) [2000|2255] "year"  CGM_LS,V2V_LS,VPM_LS,VIS2_LS,FCM_LS,BCM_LS,EOCM_F_LS,IPC_LS,CHUD_LS,HUD_LS,CSM_LS,RadioHead_LS
 SG_ CldrMth_154 : 11|4@0+ (1,0) [0|15] ""  CGM_LS,V2V_LS,VPM_LS,VIS2_LS,FCM_LS,ECC_LS,BCM_LS,EOCM_F_LS,IPC_LS,CSM_LS,RadioHead_LS,CHUD_LS,HUD_LS
 SG_ CldrDay_154 : 20|5@0+ (1,0) [0|31] "days"  CGM_LS,V2V_LS,VPM_LS,VIS2_LS,FCM_LS,ECC_LS,BCM_LS,EOCM_F_LS,IPC_LS,CSM_LS,RadioHead_LS,CHUD_LS,HUD_LS
 SG_ SecV : 46|1@0+ (1,0) [0|1] ""  CGM_LS,V2V_LS,VPM_LS,VIS2_LS,FCM_LS,BCM_LS,EOCM_F_LS,CSM_LS,RadioHead_LS
 SG_ Sec : 45|6@0+ (1,0) [0|63] "s"  CGM_LS,V2V_LS,VPM_LS,VIS2_LS,FCM_LS,BCM_LS,EOCM_F_LS,CSM_LS,RadioHead_LS
 SG_ MinsV : 38|1@0+ (1,0) [0|1] ""  CGM_LS,V2V_LS,VPM_LS,VIS2_LS,FCM_LS,ECC_LS,BCM_LS,EOCM_F_LS,CSM_LS,RadioHead_LS
 SG_ Mins : 37|6@0+ (1,0) [0|63] "min"  CGM_LS,V2V_LS,VPM_LS,VIS2_LS,FCM_LS,ECC_LS,BCM_LS,EOCM_F_LS,CSM_LS,RadioHead_LS
 SG_ HrsV : 29|1@0+ (1,0) [0|1] ""  CGM_LS,V2V_LS,VPM_LS,VIS2_LS,FCM_LS,ECC_LS,BCM_LS,EOCM_F_LS,CSM_LS,RadioHead_LS
 SG_ Hrs : 28|5@0+ (1,0) [0|31] "h"  CGM_LS,V2V_LS,VPM_LS,VIS2_LS,FCM_LS,ECC_LS,BCM_LS,EOCM_F_LS,CSM_LS,RadioHead_LS

BO_ 606 USDT_Req_to_AHS_LS: 8 CGM_LS
 SG_ DgnInf : 7|64@0+ (1,0) [0|1.84467440737096E+019] ""  CGM_LS,TCP_LS,ONSTAR_LS,EOCM2B_K2_LS,PHS_LS

BO_ 257 USDT_Req_to_All_LS_ECUs: 8 TestTool_LS
 SG_ DgnInf : 7|64@0+ (1,0) [0|1.84467440737096E+019] ""  TouchPad_LS,DVB_T_LS,BSM_LS,VICM_LS,HFP_LS,PDIM_LS,SBZA_R_LS,ICS_LS,MSM_LR_LS,LCM_LS,HVSM_R_LS,EOCM2A_K2_LS,FCM_LS,EOCM_F_LS,DCAC_LS,AGC_LS,MSM_P_LS,OTIM_LS,EOCM2B_K2_LS,PHS_LS,SDM_LS,SCL_LS,V2V_LS,ARB_LS,SBZA_L_LS,CSM_LS,CHM_LS,RadioHead_LS,STC_LS,PTM_LS,PEPS_LS,CGM_LS,TIM_LS,TIM_A_LS,VIS2_LS,IPC_LS,VPM_LS,HUD_LS,RCRM_LS,ISRVM_LS,HBSM_LS,ECC_LS,TIM_B_LS,RSE_LS,RSA_LS,UPA_LS,APA_LS,HVSM_F_LS,MSM_LS,AMP_LS,VKM_LS,RSC_LS,PSD_R_LS,CHUD_LS,MSM_RR_LS,LVMPC_LS,PSD_L_LS,BCM_LS,AOS_LS,TCP_LS,LVMNav_LS,UHP_Low,ONSTAR_LS

BO_ 1587 VNMF_LS_633_TIM: 8 TIM_LS
 SG_ VectraSpcNWMgtD : 7|64@0+ (1,0) [0|1.84467440737096E+019] ""  CGM_LS,TCP_LS,LVMNav_LS,UHP_Low,ONSTAR_LS,TIM_B_LS,RSE_LS,RSA_LS,HVSM_F_LS,MSM_LS,BCM_LS,AOS_LS,AMP_LS,BSM_LS,VICM_LS,HFP_LS,PDIM_LS,SBZA_R_LS,MSM_LR_LS,LCM_LS,HVSM_R_LS,EOCM2A_K2_LS,FCM_LS,EOCM_F_LS,ICS_LS,VKM_LS,RSC_LS,PSD_R_LS,DCAC_LS,AGC_LS,CHUD_LS,MSM_RR_LS,LVMPC_LS,PSD_L_LS,TouchPad_LS,DVB_T_LS,EOCM2B_K2_LS,PHS_LS,V2V_LS,ARB_LS,SDM_LS,SCL_LS,SBZA_L_LS,CSM_LS,CHM_LS,RadioHead_LS,STC_LS,PTM_LS,PEPS_LS,MSM_P_LS,OTIM_LS,TIM_A_LS,VIS2_LS,TestTool_LS,IPC_LS,VPM_LS,HUD_LS,RCRM_LS,ISRVM_LS,HBSM_LS,ECC_LS,UPA_LS,APA_LS

BO_ 2041 PCU_Resp_From_SDM_LS: 8 SDM_LS
 SG_ PCUInfo_7F9 : 7|64@0+ (1,0) [0|1.84467440737096E+019] ""  CGM_LS,BCM_LS

BO_ 1608 USDT_Resp_From_PDIM_LS: 8 PDIM_LS
 SG_ DgnInf : 7|64@0+ (1,0) [0|1.84467440737096E+019] ""  CSM_LS,CGM_LS,TCP_LS,ONSTAR_LS,TestTool_LS

BO_ 584 USDT_Req_to_PDIM_LS: 8 TestTool_LS
 SG_ DgnInf : 7|64@0+ (1,0) [0|1.84467440737096E+019] ""  TCP_LS,ONSTAR_LS,CGM_LS,HFP_LS,PDIM_LS

BO_ 1352 UUDT_Resp_From_PDIM_LS: 8 PDIM_LS
 SG_ DgnInf_LS548 : 7|64@0+ (1,0) [0|1.84467440737096E+019] ""  CSM_LS,CGM_LS,TCP_LS,ONSTAR_LS,TestTool_LS

BO_ 1620 USDT_Resp_From_AMP_LS: 8 CGM_LS
 SG_ DgnInf : 7|64@0+ (1,0) [0|1.84467440737096E+019] ""  CGM_LS,CSM_LS,TCP_LS,ONSTAR_LS,TestTool_LS

BO_ 1364 UUDT_Resp_From_AMP_LS: 8 CGM_LS
 SG_ DgnInf_LS554 : 7|64@0+ (1,0) [0|1.84467440737096E+019] ""  CGM_LS,CSM_LS,TCP_LS,ONSTAR_LS,TestTool_LS

BO_ 1351 UUDT_Resp_From_SDM_LS: 8 SDM_LS
 SG_ DgnInf_LS547 : 7|64@0+ (1,0) [0|1.84467440737096E+019] ""  CSM_LS,CGM_LS,TCP_LS,ONSTAR_LS,TestTool_LS

BO_ 1607 USDT_Resp_From_SDM_LS: 8 SDM_LS
 SG_ DgnInf : 7|64@0+ (1,0) [0|1.84467440737096E+019] ""  CSM_LS,CGM_LS,TCP_LS,ONSTAR_LS,TestTool_LS

BO_ 583 USDT_Req_to_SDM_LS: 8 CGM_LS
 SG_ DgnInf : 7|64@0+ (1,0) [0|1.84467440737096E+019] ""  CGM_LS,TCP_LS,ONSTAR_LS,SDM_LS

BO_ 1371 UUDT_Resp_From_ARB_LS: 8 ARB_LS
 SG_ DgnInf_LS55B : 7|64@0+ (1,0) [0|1.84467440737096E+019] ""  CSM_LS,CGM_LS,TCP_LS,ONSTAR_LS,TestTool_LS

BO_ 1627 USDT_Resp_From_ARB_LS: 8 ARB_LS
 SG_ DgnInf : 7|64@0+ (1,0) [0|1.84467440737096E+019] ""  CSM_LS,CGM_LS,TCP_LS,ONSTAR_LS,TestTool_LS

BO_ 603 USDT_Req_to_ARB_LS: 8 TestTool_LS
 SG_ DgnInf : 7|64@0+ (1,0) [0|1.84467440737096E+019] ""  TCP_LS,ONSTAR_LS,CGM_LS,V2V_LS,ARB_LS

BO_ 1370 UUDT_Resp_From_SBZA_L_LS: 8 SBZA_L_LS
 SG_ DgnInf_LS55A : 7|64@0+ (1,0) [0|1.84467440737096E+019] ""  CSM_LS,CGM_LS,TCP_LS,ONSTAR_LS,TestTool_LS

BO_ 1626 USDT_Resp_From_SBZA_L_LS: 8 SBZA_L_LS
 SG_ DgnInf : 7|64@0+ (1,0) [0|1.84467440737096E+019] ""  CSM_LS,CGM_LS,TCP_LS,ONSTAR_LS,TestTool_LS

BO_ 602 USDT_Req_to_SBZA_L_LS: 8 CGM_LS
 SG_ DgnInf : 7|64@0+ (1,0) [0|1.84467440737096E+019] ""  CGM_LS,TCP_LS,ONSTAR_LS,SBZA_L_LS

BO_ 598 USDT_Req_to_RSA_RSE_LS: 8 TestTool_LS
 SG_ DgnInf : 7|64@0+ (1,0) [0|1.84467440737096E+019] ""  TCP_LS,ONSTAR_LS,CGM_LS,TIM_B_LS,RSE_LS,RSA_LS

BO_ 1366 UUDT_Resp_From_RSA_RSE_LS: 8 RSA_LS
 SG_ DgnInf_LS556 : 7|64@0+ (1,0) [0|1.84467440737096E+019] ""  CGM_LS,CSM_LS,TCP_LS,ONSTAR_LS,TestTool_LS

BO_ 1622 USDT_Resp_From_RSA_RSE_LS: 8 CGM_LS
 SG_ DgnInf : 7|64@0+ (1,0) [0|1.84467440737096E+019] ""  CGM_LS,CSM_LS,TCP_LS,ONSTAR_LS,TestTool_LS

BO_ 580 USDT_Req_to_RadioHead_LS: 8 TestTool_LS
 SG_ DgnInf : 7|64@0+ (1,0) [0|1.84467440737096E+019] ""  TCP_LS,ONSTAR_LS,CGM_LS,CSM_LS,CHM_LS,RadioHead_LS

BO_ 1604 USDT_Resp_From_RadioHead_LS: 8 CGM_LS
 SG_ DgnInf : 7|64@0+ (1,0) [0|1.84467440737096E+019] ""  CGM_LS,TCP_LS,ONSTAR_LS,TestTool_LS

BO_ 1348 UUDT_Resp_From_RadioHead_LS: 8 CGM_LS
 SG_ DgnInf_LS544 : 7|64@0+ (1,0) [0|1.84467440737096E+019] ""  CGM_LS,TCP_LS,ONSTAR_LS,TestTool_LS

BO_ 1615 USDT_Resp_From_PTM_STC_LS: 8 PTM_LS
 SG_ DgnInf : 7|64@0+ (1,0) [0|1.84467440737096E+019] ""  CSM_LS,CGM_LS,TCP_LS,ONSTAR_LS,TestTool_LS

BO_ 1359 UUDT_Resp_From_PTM_STC_LS: 8 PTM_LS
 SG_ DgnInf_LS54F : 7|64@0+ (1,0) [0|1.84467440737096E+019] ""  CSM_LS,CGM_LS,TCP_LS,ONSTAR_LS,TestTool_LS

BO_ 591 USDT_Req_to_PTM_STC_LS: 8 CGM_LS
 SG_ DgnInf : 7|64@0+ (1,0) [0|1.84467440737096E+019] ""  CGM_LS,TCP_LS,ONSTAR_LS,STC_LS,PTM_LS

BO_ 1602 USDT_Resp_From_PEPS_PBSM_LS: 8 PEPS_LS
 SG_ DgnInf : 7|64@0+ (1,0) [0|1.84467440737096E+019] ""  CSM_LS,CGM_LS,TCP_LS,ONSTAR_LS,TestTool_LS

BO_ 1346 UUDT_Resp_From_PEPS_PBSM_LS: 8 PEPS_LS
 SG_ DgnInf_LS542 : 7|64@0+ (1,0) [0|1.84467440737096E+019] ""  CSM_LS,CGM_LS,TCP_LS,ONSTAR_LS,TestTool_LS

BO_ 578 USDT_Req_to_PEPS_PBSM_LS: 8 CGM_LS
 SG_ DgnInf : 7|64@0+ (1,0) [0|1.84467440737096E+019] ""  CGM_LS,TCP_LS,ONSTAR_LS,PEPS_LS

BO_ 1614 USDT_Resp_From_PSD_R_LS: 8 PSD_R_LS
 SG_ DgnInf : 7|64@0+ (1,0) [0|1.84467440737096E+019] ""  CSM_LS,CGM_LS,TCP_LS,ONSTAR_LS,TestTool_LS

BO_ 1358 UUDT_Resp_From_PSD_R_LS: 8 PSD_R_LS
 SG_ DgnInf_LS54E : 7|64@0+ (1,0) [0|1.84467440737096E+019] ""  CSM_LS,CGM_LS,TCP_LS,ONSTAR_LS,TestTool_LS

BO_ 1356 UUDT_Resp_From_IPC_LS: 8 IPC_LS
 SG_ DgnInf_LS54C : 7|64@0+ (1,0) [0|1.84467440737096E+019] ""  CGM_LS,CSM_LS,TCP_LS,ONSTAR_LS,TestTool_LS

BO_ 1612 USDT_Resp_From_IPC_LS: 8 IPC_LS
 SG_ DgnInf : 7|64@0+ (1,0) [0|1.84467440737096E+019] ""  CGM_LS,CSM_LS,TCP_LS,ONSTAR_LS,TestTool_LS

BO_ 588 USDT_Req_to_IPC_LS: 8 TestTool_LS
 SG_ DgnInf : 7|64@0+ (1,0) [0|1.84467440737096E+019] ""  TCP_LS,ONSTAR_LS,CGM_LS,IPC_LS

BO_ 1360 UUDT_Resp_From_HUD_LS: 8 CGM_LS
 SG_ DgnInf_LS550 : 7|64@0+ (1,0) [0|1.84467440737096E+019] ""  CGM_LS,CSM_LS,TCP_LS,ONSTAR_LS,TestTool_LS

BO_ 1616 USDT_Resp_From_HUD_LS: 8 CGM_LS
 SG_ DgnInf : 7|64@0+ (1,0) [0|1.84467440737096E+019] ""  CGM_LS,CSM_LS,TCP_LS,ONSTAR_LS,TestTool_LS

BO_ 592 USDT_Req_to_HUD_LS: 8 TestTool_LS
 SG_ DgnInf : 7|64@0+ (1,0) [0|1.84467440737096E+019] ""  TCP_LS,ONSTAR_LS,CGM_LS,VPM_LS,HUD_LS

BO_ 1375 UUDT_Resp_From_HBSM_LS: 8 CGM_LS
 SG_ DgnInf_LS55F : 7|64@0+ (1,0) [0|1.84467440737096E+019] ""  CSM_LS,CGM_LS,TCP_LS,ONSTAR_LS,TestTool_LS

BO_ 1631 USDT_Resp_From_HBSM_LS: 8 CGM_LS
 SG_ DgnInf : 7|64@0+ (1,0) [0|1.84467440737096E+019] ""  CSM_LS,CGM_LS,TCP_LS,ONSTAR_LS,TestTool_LS

BO_ 607 USDT_Req_to_HBSM_LS: 8 CGM_LS
 SG_ DgnInf : 7|64@0+ (1,0) [0|1.84467440737096E+019] ""  TCP_LS,ONSTAR_LS,CGM_LS,RCRM_LS,ISRVM_LS,HBSM_LS

BO_ 1361 UUDT_Resp_From_ECC_HVAC_LS: 8 ECC_LS
 SG_ DgnInf_LS551 : 7|64@0+ (1,0) [0|1.84467440737096E+019] ""  CSM_LS,CGM_LS,TCP_LS,ONSTAR_LS,TestTool_LS

BO_ 1617 USDT_Resp_From_ECC_HVAC_LS: 8 ECC_LS
 SG_ DgnInf : 7|64@0+ (1,0) [0|1.84467440737096E+019] ""  CSM_LS,CGM_LS,TCP_LS,ONSTAR_LS,TestTool_LS

BO_ 593 USDT_Req_to_ECC_HVAC_LS: 8 CGM_LS
 SG_ DgnInf : 7|64@0+ (1,0) [0|1.84467440737096E+019] ""  CGM_LS,TCP_LS,ONSTAR_LS,ECC_LS

BO_ 1362 UUDT_Resp_From_DVBT_LS: 8 CGM_LS
 SG_ DgnInf_LS552 : 7|64@0+ (1,0) [0|1.84467440737096E+019] ""  CGM_LS,CSM_LS,TCP_LS,ONSTAR_LS,TestTool_LS

BO_ 1618 USDT_Resp_From_DVBT_LS: 8 CGM_LS
 SG_ DgnInf : 7|64@0+ (1,0) [0|1.84467440737096E+019] ""  CGM_LS,CSM_LS,TCP_LS,ONSTAR_LS,TestTool_LS

BO_ 594 USDT_Req_to_DVBT_LS: 8 TestTool_LS
 SG_ DgnInf : 7|64@0+ (1,0) [0|1.84467440737096E+019] ""  TCP_LS,ONSTAR_LS,CGM_LS,TouchPad_LS,DVB_T_LS

BO_ 1373 UUDT_Resp_From_DSM_LS: 8 MSM_LS
 SG_ DgnInf_LS55D : 7|64@0+ (1,0) [0|1.84467440737096E+019] ""  CSM_LS,CGM_LS,TCP_LS,ONSTAR_LS,TestTool_LS

BO_ 1629 USDT_Resp_From_DSM_LS: 8 MSM_LS
 SG_ DgnInf : 7|64@0+ (1,0) [0|1.84467440737096E+019] ""  CSM_LS,CGM_LS,TCP_LS,ONSTAR_LS,TestTool_LS

BO_ 605 USDT_Req_to_DSM_LS: 8 TestTool_LS
 SG_ DgnInf : 7|64@0+ (1,0) [0|1.84467440737096E+019] ""  CGM_LS,TCP_LS,ONSTAR_LS,HVSM_F_LS,MSM_LS

BO_ 1345 UUDT_Resp_From_BCM_LS: 8 BCM_LS
 SG_ DgnInf_LS541 : 7|64@0+ (1,0) [0|1.84467440737096E+019] ""  CSM_LS,CGM_LS,TCP_LS,ONSTAR_LS,TestTool_LS

BO_ 1601 USDT_Resp_From_BCM_LS: 8 BCM_LS
 SG_ DgnInf : 7|64@0+ (1,0) [0|1.84467440737096E+019] ""  CSM_LS,CGM_LS,TCP_LS,ONSTAR_LS,TestTool_LS

BO_ 577 USDT_Req_to_BCM_LS: 8 CGM_LS
 SG_ DgnInf : 7|64@0+ (1,0) [0|1.84467440737096E+019] ""  CGM_LS,TCP_LS,ONSTAR_LS,BCM_LS

BO_ 601 USDT_Req_to_UPA_APA_LS: 8 CGM_LS
 SG_ DgnInf : 7|64@0+ (1,0) [0|1.84467440737096E+019] ""  CGM_LS,TCP_LS,ONSTAR_LS,UPA_LS,APA_LS

BO_ 1369 UUDT_Resp_From_UPA_APA_LS: 8 APA_LS
 SG_ DgnInf_LS559 : 7|64@0+ (1,0) [0|1.84467440737096E+019] ""  CSM_LS,CGM_LS,TCP_LS,ONSTAR_LS,TestTool_LS

BO_ 595 USDT_Req_to_TIM_CGM_LS: 8 TestTool_LS
 SG_ DgnInf : 7|64@0+ (1,0) [0|1.84467440737096E+019] ""  TCP_LS,ONSTAR_LS,CGM_LS,TIM_LS

BO_ 1575 VNMF_LS_627_SDM: 8 SDM_LS
 SG_ VectraSpcNWMgtD : 7|64@0+ (1,0) [0|1.84467440737096E+019] ""  TCP_LS,LVMNav_LS,UHP_Low,ONSTAR_LS,TIM_B_LS,RSE_LS,RSA_LS,HVSM_F_LS,MSM_LS,BCM_LS,AOS_LS,AMP_LS,BSM_LS,VICM_LS,HFP_LS,PDIM_LS,SBZA_R_LS,ICS_LS,EOCM2A_K2_LS,FCM_LS,EOCM_F_LS,MSM_LR_LS,LCM_LS,HVSM_R_LS,V2V_LS,ARB_LS,VKM_LS,RSC_LS,PSD_R_LS,CHUD_LS,MSM_RR_LS,LVMPC_LS,PSD_L_LS,DCAC_LS,AGC_LS,TouchPad_LS,DVB_T_LS,EOCM2B_K2_LS,PHS_LS,SCL_LS,SBZA_L_LS,CSM_LS,CHM_LS,RadioHead_LS,STC_LS,PTM_LS,PEPS_LS,MSM_P_LS,OTIM_LS,CGM_LS,TIM_LS,TIM_A_LS,VIS2_LS,TestTool_LS,IPC_LS,VPM_LS,HUD_LS,RCRM_LS,ISRVM_LS,HBSM_LS,ECC_LS,UPA_LS,APA_LS

BO_ 1581 VNMF_LS_62D_UHP_ONS: 8 ONSTAR_LS
 SG_ VectraSpcNWMgtD : 7|64@0+ (1,0) [0|1.84467440737096E+019] ""  TIM_B_LS,RSE_LS,RSA_LS,HVSM_F_LS,MSM_LS,BCM_LS,AOS_LS,AMP_LS,BSM_LS,VICM_LS,HFP_LS,PDIM_LS,SBZA_R_LS,MSM_LR_LS,LCM_LS,HVSM_R_LS,ICS_LS,EOCM2A_K2_LS,FCM_LS,EOCM_F_LS,VKM_LS,RSC_LS,PSD_R_LS,DCAC_LS,AGC_LS,CHUD_LS,MSM_RR_LS,LVMPC_LS,PSD_L_LS,TouchPad_LS,DVB_T_LS,EOCM2B_K2_LS,PHS_LS,V2V_LS,ARB_LS,SDM_LS,SCL_LS,SBZA_L_LS,CSM_LS,CHM_LS,RadioHead_LS,STC_LS,PTM_LS,PEPS_LS,MSM_P_LS,OTIM_LS,CGM_LS,TIM_LS,TIM_A_LS,VIS2_LS,TestTool_LS,IPC_LS,VPM_LS,HUD_LS,RCRM_LS,ISRVM_LS,HBSM_LS,ECC_LS,UPA_LS,APA_LS

BO_ 1580 VNMF_LS_62C_IPC: 8 IPC_LS
 SG_ VectraSpcNWMgtD : 7|64@0+ (1,0) [0|1.84467440737096E+019] ""  TCP_LS,LVMNav_LS,UHP_Low,ONSTAR_LS,TIM_B_LS,RSE_LS,RSA_LS,HVSM_F_LS,MSM_LS,BCM_LS,AOS_LS,AMP_LS,BSM_LS,VICM_LS,HFP_LS,PDIM_LS,SBZA_R_LS,ICS_LS,MSM_LR_LS,LCM_LS,HVSM_R_LS,EOCM2A_K2_LS,FCM_LS,EOCM_F_LS,VKM_LS,RSC_LS,PSD_R_LS,CHUD_LS,MSM_RR_LS,LVMPC_LS,PSD_L_LS,DCAC_LS,AGC_LS,TouchPad_LS,DVB_T_LS,EOCM2B_K2_LS,PHS_LS,V2V_LS,ARB_LS,SDM_LS,SCL_LS,SBZA_L_LS,CSM_LS,CHM_LS,RadioHead_LS,STC_LS,PTM_LS,PEPS_LS,MSM_P_LS,OTIM_LS,CGM_LS,TIM_LS,TIM_A_LS,VIS2_LS,TestTool_LS,VPM_LS,HUD_LS,RCRM_LS,ISRVM_LS,HBSM_LS,ECC_LS,UPA_LS,APA_LS

BO_ 1584 VNMF_LS_630_HUD: 8 HUD_LS
 SG_ VectraSpcNWMgtD : 7|64@0+ (1,0) [0|1.84467440737096E+019] ""  TCP_LS,LVMNav_LS,UHP_Low,ONSTAR_LS,TIM_B_LS,RSE_LS,RSA_LS,HVSM_F_LS,MSM_LS,BCM_LS,AOS_LS,AMP_LS,BSM_LS,VICM_LS,HFP_LS,PDIM_LS,SBZA_R_LS,MSM_LR_LS,LCM_LS,HVSM_R_LS,EOCM2A_K2_LS,FCM_LS,EOCM_F_LS,ICS_LS,VKM_LS,RSC_LS,PSD_R_LS,DCAC_LS,AGC_LS,CHUD_LS,MSM_RR_LS,LVMPC_LS,PSD_L_LS,TouchPad_LS,DVB_T_LS,EOCM2B_K2_LS,PHS_LS,V2V_LS,ARB_LS,SDM_LS,SCL_LS,SBZA_L_LS,CSM_LS,CHM_LS,RadioHead_LS,STC_LS,PTM_LS,PEPS_LS,MSM_P_LS,OTIM_LS,CGM_LS,TIM_LS,TIM_A_LS,VIS2_LS,TestTool_LS,IPC_LS,RCRM_LS,ISRVM_LS,HBSM_LS,ECC_LS,UPA_LS,APA_LS

BO_ 1569 VNMF_LS_621_BCM: 8 BCM_LS
 SG_ VectraSpcNWMgtD : 7|64@0+ (1,0) [0|1.84467440737096E+019] ""  TCP_LS,LVMNav_LS,UHP_Low,ONSTAR_LS,TIM_B_LS,RSE_LS,RSA_LS,HVSM_F_LS,MSM_LS,AOS_LS,AMP_LS,V2V_LS,ARB_LS,BSM_LS,VICM_LS,HFP_LS,PDIM_LS,SBZA_R_LS,ICS_LS,EOCM2A_K2_LS,FCM_LS,EOCM_F_LS,VKM_LS,RSC_LS,PSD_R_LS,CHUD_LS,MSM_RR_LS,LVMPC_LS,PSD_L_LS,DCAC_LS,AGC_LS,TouchPad_LS,DVB_T_LS,EOCM2B_K2_LS,PHS_LS,MSM_LR_LS,LCM_LS,HVSM_R_LS,SDM_LS,SCL_LS,SBZA_L_LS,CSM_LS,CHM_LS,RadioHead_LS,STC_LS,PTM_LS,PEPS_LS,MSM_P_LS,OTIM_LS,CGM_LS,TIM_LS,TIM_A_LS,VIS2_LS,TestTool_LS,IPC_LS,VPM_LS,HUD_LS,RCRM_LS,ISRVM_LS,HBSM_LS,ECC_LS,UPA_LS,APA_LS

BO_ 1573 VNMF_LS_625_AOS: 8 AOS_LS
 SG_ VectraSpcNWMgtD : 7|64@0+ (1,0) [0|1.84467440737096E+019] ""  TCP_LS,LVMNav_LS,UHP_Low,ONSTAR_LS,TIM_B_LS,RSE_LS,RSA_LS,HVSM_F_LS,MSM_LS,BCM_LS,AMP_LS,BSM_LS,VICM_LS,HFP_LS,PDIM_LS,SBZA_R_LS,V2V_LS,ARB_LS,ICS_LS,EOCM2A_K2_LS,FCM_LS,EOCM_F_LS,MSM_LR_LS,LCM_LS,HVSM_R_LS,VKM_LS,RSC_LS,PSD_R_LS,CHUD_LS,MSM_RR_LS,LVMPC_LS,PSD_L_LS,DCAC_LS,AGC_LS,TouchPad_LS,DVB_T_LS,EOCM2B_K2_LS,PHS_LS,SDM_LS,SCL_LS,SBZA_L_LS,CSM_LS,CHM_LS,RadioHead_LS,STC_LS,PTM_LS,PEPS_LS,MSM_P_LS,OTIM_LS,CGM_LS,TIM_LS,TIM_A_LS,VIS2_LS,TestTool_LS,IPC_LS,VPM_LS,HUD_LS,RCRM_LS,ISRVM_LS,HBSM_LS,ECC_LS,UPA_LS,APA_LS

BO_ 1588 VNMF_LS_634_AMP: 8 AMP_LS
 SG_ VectraSpcNWMgtD : 7|64@0+ (1,0) [0|1.84467440737096E+019] ""  TCP_LS,LVMNav_LS,UHP_Low,ONSTAR_LS,TIM_B_LS,RSE_LS,RSA_LS,HVSM_F_LS,MSM_LS,BCM_LS,AOS_LS,BSM_LS,VICM_LS,HFP_LS,PDIM_LS,SBZA_R_LS,MSM_LR_LS,LCM_LS,HVSM_R_LS,EOCM2A_K2_LS,FCM_LS,EOCM_F_LS,ICS_LS,VKM_LS,RSC_LS,PSD_R_LS,DCAC_LS,AGC_LS,CHUD_LS,MSM_RR_LS,LVMPC_LS,PSD_L_LS,TouchPad_LS,DVB_T_LS,EOCM2B_K2_LS,PHS_LS,V2V_LS,ARB_LS,SDM_LS,SCL_LS,SBZA_L_LS,CSM_LS,CHM_LS,RadioHead_LS,STC_LS,PTM_LS,PEPS_LS,MSM_P_LS,OTIM_LS,CGM_LS,TIM_LS,TIM_A_LS,VIS2_LS,TestTool_LS,IPC_LS,VPM_LS,HUD_LS,RCRM_LS,ISRVM_LS,HBSM_LS,ECC_LS,UPA_LS,APA_LS

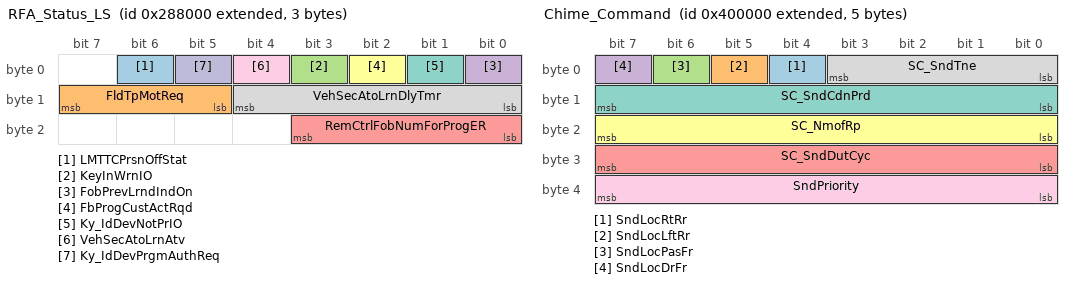
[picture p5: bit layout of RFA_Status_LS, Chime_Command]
BO_ 2150137856 RFA_Status_LS: 3 BCM_LS
 SG_ LMTTCPrsnOffStat : 6|1@0+ (1,0) [0|1] ""  CGM_LS,PEPS_LS
 SG_ FldTpMotReq : 15|3@0+ (1,0) [0|7] ""  CGM_LS,PEPS_LS
 SG_ KeyInWrnIO : 3|1@0+ (1,0) [0|1] ""  CGM_LS,IPC_LS
 SG_ FobPrevLrndIndOn : 0|1@0+ (1,0) [0|1] ""  CGM_LS,IPC_LS
 SG_ RemCtrlFobNumForProgER : 19|4@0+ (1,0) [0|15] ""  CGM_LS,PEPS_LS,IPC_LS
 SG_ FbProgCustActRqd : 2|1@0+ (1,0) [0|1] ""  CGM_LS,IPC_LS
 SG_ Ky_IdDevNotPrIO : 1|1@0+ (1,0) [0|1] ""  CGM_LS,IPC_LS
 SG_ VehSecAtoLrnDlyTmr : 12|5@0+ (1,0) [0|31] "min"  CGM_LS,IPC_LS
 SG_ VehSecAtoLrnAtv : 4|1@0+ (1,0) [0|1] ""  CGM_LS,IPC_LS
 SG_ Ky_IdDevPrgmAuthReq : 5|1@0+ (1,0) [0|1] ""  CGM_LS,PEPS_LS

BO_ 2151677952 Chime_Command: 5 MSM_LS
 SG_ SndLocRtRr : 4|1@0+ (1,0) [0|1] ""  CGM_LS,CHM_LS,AMP_LS,RadioHead_LS
 SG_ SndLocLftRr : 5|1@0+ (1,0) [0|1] ""  CGM_LS,CHM_LS,AMP_LS,RadioHead_LS
 SG_ SndLocPasFr : 6|1@0+ (1,0) [0|1] ""  CGM_LS,CHM_LS,AMP_LS,RadioHead_LS
 SG_ SndLocDrFr : 7|1@0+ (1,0) [0|1] ""  CGM_LS,CHM_LS,AMP_LS,RadioHead_LS
 SG_ SC_SndDutCyc : 31|8@0+ (0.392157,0) [0|100.000035] "%"  CGM_LS,CHM_LS,AMP_LS,RadioHead_LS
 SG_ SC_NmofRp : 23|8@0+ (1,0) [0|255] "reps"  CGM_LS,CHM_LS,AMP_LS,RadioHead_LS
 SG_ SC_SndCdnPrd : 15|8@0+ (10,0) [0|2550] "ms"  CGM_LS,CHM_LS,AMP_LS,RadioHead_LS
 SG_ SC_SndTne : 3|4@0+ (1,0) [0|15] ""  CGM_LS,CHM_LS,AMP_LS,RadioHead_LS
 SG_ SndPriority : 39|8@0+ (1,0) [0|255] ""  CGM_LS,CHM_LS,AMP_LS,RadioHead_LS

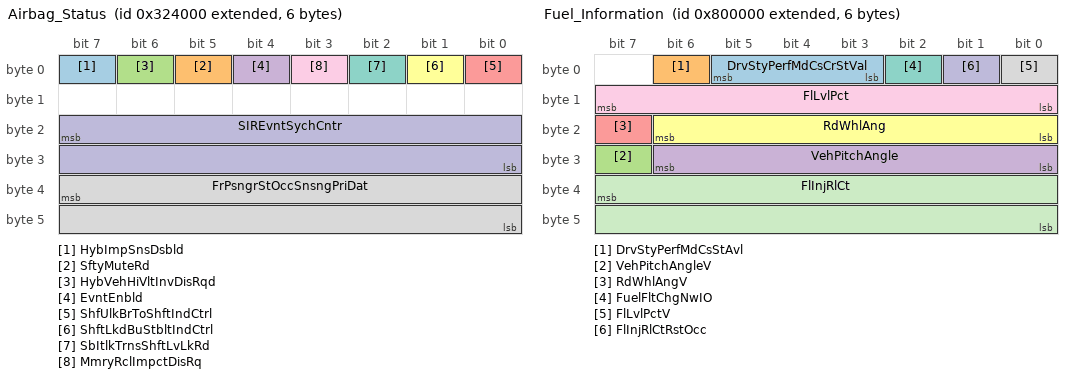
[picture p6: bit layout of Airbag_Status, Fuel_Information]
BO_ 2150776832 Airbag_Status: 6 SDM_LS
 SG_ HybImpSnsDsbld : 7|1@0+ (1,0) [0|1] ""  EOCM2A_K2_LS,EOCM2B_K2_LS,BCM_LS,CGM_LS,BSM_LS,VICM_LS
 SG_ SftyMuteRd : 5|1@0+ (1,0) [0|1] ""  EOCM2A_K2_LS,CSM_LS,EOCM2B_K2_LS,CGM_LS,RadioHead_LS
 SG_ HybVehHiVltInvDisRqd : 6|1@0+ (1,0) [0|1] ""  EOCM2A_K2_LS,EOCM2B_K2_LS,CGM_LS,BSM_LS,VICM_LS,BCM_LS
 SG_ EvntEnbld : 4|1@0+ (1,0) [0|1] ""  EOCM2A_K2_LS,EOCM2B_K2_LS,CGM_LS,AOS_LS
 SG_ ShfUlkBrToShftIndCtrl : 0|1@0+ (1,0) [0|1] ""  EOCM2A_K2_LS,CGM_LS,EOCM2B_K2_LS,IPC_LS
 SG_ ShftLkdBuStbltIndCtrl : 1|1@0+ (1,0) [0|1] ""  EOCM2A_K2_LS,EOCM2B_K2_LS,CGM_LS,IPC_LS
 SG_ SbItlkTrnsShftLvLkRd : 2|1@0+ (1,0) [0|1] ""  EOCM2A_K2_LS,EOCM2B_K2_LS,CGM_LS,BCM_LS
 SG_ FrPsngrStOccSnsngPriDat : 39|16@0+ (1,0) [0|39321] ""  EOCM2A_K2_LS,EOCM2B_K2_LS,CGM_LS,AOS_LS
 SG_ MmryRclImpctDisRq : 3|1@0+ (1,0) [0|1] ""  EOCM2A_K2_LS,TCP_LS,EOCM2B_K2_LS,MSM_RR_LS,MSM_LR_LS,CGM_LS,PSD_R_LS,PSD_L_LS,BSM_LS,VICM_LS,BCM_LS,ONSTAR_LS,MSM_P_LS,MSM_LS,LCM_LS,PTM_LS
 SG_ SIREvntSychCntr : 23|16@0+ (1,0) [0|65535] ""  EOCM2A_K2_LS,TCP_LS,CGM_LS,EOCM2B_K2_LS,ONSTAR_LS,EOCM_F_LS,AOS_LS

BO_ 2150760448 Airbag_Impact_Data: 8 SDM_LS
 SG_ NotSndRwRtSeatStat : 13|2@0+ (1,0) [0|3] ""  TCP_LS,EOCM2B_K2_LS,EOCM2A_K2_LS,CGM_LS,ONSTAR_LS
 SG_ NotSndRwMdlSeatStat : 11|2@0+ (1,0) [0|3] ""  TCP_LS,EOCM2B_K2_LS,EOCM2A_K2_LS,CGM_LS,ONSTAR_LS
 SG_ NotSndRwLtSeatStat : 15|2@0+ (1,0) [0|3] ""  TCP_LS,EOCM2B_K2_LS,EOCM2A_K2_LS,CGM_LS,ONSTAR_LS
 SG_ NotPsSeatStat : 5|2@0+ (1,0) [0|3] ""  TCP_LS,EOCM2B_K2_LS,EOCM2A_K2_LS,CGM_LS,ONSTAR_LS
 SG_ NotDrvSeatStat : 7|2@0+ (1,0) [0|3] ""  TCP_LS,EOCM2B_K2_LS,EOCM2A_K2_LS,CGM_LS,ONSTAR_LS
 SG_ NotSecRowRtSeaOccStat : 9|2@0+ (1,0) [0|3] ""  TCP_LS,EOCM2B_K2_LS,EOCM2A_K2_LS,CGM_LS,ONSTAR_LS
 SG_ NotSecRowLeSeaOccStat : 25|2@0+ (1,0) [0|3] ""  TCP_LS,EOCM2B_K2_LS,EOCM2A_K2_LS,CGM_LS,ONSTAR_LS
 SG_ NotSecRowCtSeaOccStat : 27|2@0+ (1,0) [0|3] ""  TCP_LS,EOCM2B_K2_LS,EOCM2A_K2_LS,CGM_LS,ONSTAR_LS
 SG_ NotiFrntPasSeatOccSta : 34|3@0+ (1,0) [0|7] ""  TCP_LS,EOCM2B_K2_LS,EOCM2A_K2_LS,CGM_LS,ONSTAR_LS
 SG_ NotEventStat : 17|2@0+ (1,0) [0|3] ""  VPM_LS,TCP_LS,EOCM2B_K2_LS,EOCM2A_K2_LS,CGM_LS,FCM_LS,ECC_LS,BCM_LS,EOCM_F_LS,ONSTAR_LS
 SG_ NotiEventCount : 63|8@0+ (1,0) [0|255] ""  TCP_LS,EOCM2B_K2_LS,EOCM2A_K2_LS,CGM_LS,FCM_LS,EOCM_F_LS,ONSTAR_LS,AOS_LS
 SG_ NESSRoSevSt : 48|1@0+ (1,0) [0|1] ""  TCP_LS,EOCM2B_K2_LS,EOCM2A_K2_LS,CGM_LS,ECC_LS,EOCM_F_LS,BSM_LS,VICM_LS,BCM_LS,ONSTAR_LS,AOS_LS
 SG_ NESSRiSiSevSt : 49|1@0+ (1,0) [0|1] ""  TCP_LS,EOCM2B_K2_LS,EOCM2A_K2_LS,CGM_LS,ECC_LS,EOCM_F_LS,BSM_LS,VICM_LS,BCM_LS,ONSTAR_LS,AOS_LS
 SG_ NESSReImpSevSt : 50|1@0+ (1,0) [0|1] ""  TCP_LS,EOCM2B_K2_LS,EOCM2A_K2_LS,CGM_LS,ECC_LS,EOCM_F_LS,BSM_LS,VICM_LS,BCM_LS,ONSTAR_LS,AOS_LS
 SG_ NESSLeSiSevSt : 51|1@0+ (1,0) [0|1] ""  TCP_LS,EOCM2B_K2_LS,EOCM2A_K2_LS,CGM_LS,ECC_LS,EOCM_F_LS,BSM_LS,VICM_LS,BCM_LS,ONSTAR_LS,AOS_LS
 SG_ NESSFrImpSt2SevSt : 52|1@0+ (1,0) [0|1] ""  TCP_LS,EOCM2B_K2_LS,EOCM2A_K2_LS,CGM_LS,ECC_LS,EOCM_F_LS,BSM_LS,VICM_LS,BCM_LS,ONSTAR_LS,AOS_LS
 SG_ NESSFrImpSt1SevSt : 53|1@0+ (1,0) [0|1] ""  TCP_LS,EOCM2B_K2_LS,EOCM2A_K2_LS,CGM_LS,ECC_LS,EOCM_F_LS,BSM_LS,VICM_LS,BCM_LS,ONSTAR_LS,AOS_LS
 SG_ NESSFrImpPreSevSt : 54|1@0+ (1,0) [0|1] ""  TCP_LS,EOCM2B_K2_LS,EOCM2A_K2_LS,CGM_LS,ECC_LS,EOCM_F_LS,BSM_LS,VICM_LS,BCM_LS,ONSTAR_LS,AOS_LS
 SG_ NEDLSRtSdArbgDld : 41|1@0+ (1,0) [0|1] ""  CSM_LS,RadioHead_LS,TCP_LS,EOCM2B_K2_LS,EOCM2A_K2_LS,CGM_LS,ONSTAR_LS
 SG_ NEDLSLtSdArbgDld : 42|1@0+ (1,0) [0|1] ""  CSM_LS,RadioHead_LS,TCP_LS,EOCM2B_K2_LS,EOCM2A_K2_LS,CGM_LS,ONSTAR_LS
 SG_ NEDLSSdCrtnArbgDpld : 40|1@0+ (1,0) [0|1] ""  CSM_LS,RadioHead_LS,TCP_LS,EOCM2B_K2_LS,EOCM2A_K2_LS,CGM_LS,ONSTAR_LS
 SG_ NEDLSPaFrSt2De : 43|1@0+ (1,0) [0|1] ""  CSM_LS,RadioHead_LS,TCP_LS,EOCM2B_K2_LS,EOCM2A_K2_LS,CGM_LS,ONSTAR_LS
 SG_ NEDLSPaFrSt1De : 44|1@0+ (1,0) [0|1] ""  CSM_LS,RadioHead_LS,TCP_LS,EOCM2B_K2_LS,EOCM2A_K2_LS,CGM_LS,ONSTAR_LS
 SG_ NEDLSDrFrSt2De : 45|1@0+ (1,0) [0|1] ""  CSM_LS,RadioHead_LS,TCP_LS,EOCM2B_K2_LS,EOCM2A_K2_LS,CGM_LS,ONSTAR_LS
 SG_ NEDLSDrFrSt1De : 46|1@0+ (1,0) [0|1] ""  CSM_LS,RadioHead_LS,TCP_LS,EOCM2B_K2_LS,EOCM2A_K2_LS,CGM_LS,ONSTAR_LS
 SG_ SIRDpl : 1|1@0+ (1,0) [0|1] ""  TCP_LS,CSM_LS,EOCM2B_K2_LS,EOCM2A_K2_LS,V2V_LS,CGM_LS,VIS2_LS,FCM_LS,ICS_LS,PSD_R_LS,PSD_L_LS,BSM_LS,VICM_LS,EOCM_F_LS,OTIM_LS,ONSTAR_LS,RadioHead_LS,LCM_LS,PTM_LS,PEPS_LS,BCM_LS,ECC_LS

BO_ 2155872256 Fuel_Information: 6 BCM_LS
 SG_ DrvStyPerfMdCsCrStVal : 5|3@0+ (1,0) [0|7] ""  CGM_LS,RadioHead_LS
 SG_ DrvStyPerfMdCsStAvl : 6|1@0+ (1,0) [0|1] ""  CGM_LS,RadioHead_LS
 SG_ VehPitchAngleV : 31|1@0+ (1,0) [0|1] ""  RadioHead_LS,CGM_LS,IPC_LS
 SG_ VehPitchAngle : 30|7@0+ (0.703125,-45) [-45|44.296875] "deg"  RadioHead_LS,CGM_LS,IPC_LS
 SG_ RdWhlAngV : 23|1@0+ (1,0) [0|1] ""  VPM_LS,CGM_LS,IPC_LS
 SG_ RdWhlAng : 22|7@0+ (0.703125,-45) [-45|44.296875] "deg"  VPM_LS,CGM_LS,IPC_LS
 SG_ FuelFltChgNwIO : 2|1@0+ (1,0) [0|1] ""  CGM_LS,RadioHead_LS,IPC_LS
 SG_ FlLvlPctV : 0|1@0+ (1,0) [0|1] ""  TCP_LS,CGM_LS,LVMNav_LS,RadioHead_LS,PHS_LS,ONSTAR_LS,IPC_LS
 SG_ FlLvlPct : 15|8@0+ (0.392157,0) [0|100.000035] "%"  TCP_LS,CGM_LS,LVMNav_LS,RadioHead_LS,PHS_LS,ONSTAR_LS,IPC_LS
 SG_ FlInjRlCtRstOcc : 1|1@0+ (1,0) [0|1] ""  CGM_LS,RadioHead_LS,IPC_LS
 SG_ FlInjRlCt : 39|16@0+ (3.05176E-005,0) [0|1.999970916] "liters"  CGM_LS,RadioHead_LS,IPC_LS

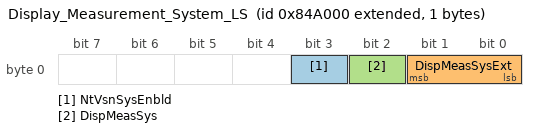
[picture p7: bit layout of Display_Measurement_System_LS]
BO_ 2156175360 Display_Measurement_System_LS: 1 IPC_LS
 SG_ NtVsnSysEnbld : 3|1@0+ (1,0) [0|1] ""  EOCM2B_K1_LS,EOCM2A_K1_LS,EOCM_F_LS
 SG_ DispMeasSysExt : 1|2@0+ (1,0) [0|3] ""  EOCM2B_K1_LS,EOCM2A_K1_LS,TCP_LS,V2V_LS,LVMPC_LS,LVMNav_LS,EDI_LS,BSM_LS,VICM_LS,RadioHead_LS,ONSTAR_LS,RSC_LS,RSA_LS,AGC_LS,CHUD_LS,HUD_LS,ECC_LS
 SG_ DispMeasSys : 2|1@0+ (1,0) [0|1] ""  EOCM2B_K1_LS,EOCM2A_K1_LS,FCM_LS,V2V_LS,LVMPC_LS,LVMNav_LS,EDI_LS,EOCM_F_LS,BCM_LS

BO_TX_BU_ 2151907328 : CGM_LS,IPC_LS,BCM_LS;
BO_TX_BU_ 1579 : EOCM2A_K2_LS,FCM_LS,EOCM_F_LS;
BO_TX_BU_ 1599 : CGM_LS,RCRM_LS,ISRVM_LS,HBSM_LS;
BO_TX_BU_ 1583 : STC_LS,PTM_LS;
BO_TX_BU_ 1586 : CGM_LS,TouchPad_LS,DVB_T_LS;
BO_TX_BU_ 1572 : CGM_LS,CHM_LS,RadioHead_LS;
BO_TX_BU_ 1578 : CGM_LS,CHUD_LS,MSM_RR_LS,LVMPC_LS,PSD_L_LS;
BO_TX_BU_ 1597 : HVSM_F_LS,MSM_LS;
BO_TX_BU_ 1598 : EOCM2B_K2_LS,PHS_LS;
BO_TX_BU_ 1576 : CGM_LS,HFP_LS,PDIM_LS;
BO_TX_BU_ 1582 : CGM_LS,VKM_LS,RSC_LS,PSD_R_LS;
BO_TX_BU_ 1590 : CGM_LS,TIM_B_LS,RSE_LS,RSA_LS;
BO_TX_BU_ 1592 : MSM_LR_LS,LCM_LS,HVSM_R_LS;
BO_TX_BU_ 1595 : CGM_LS,V2V_LS,ARB_LS;
BO_TX_BU_ 1593 : UPA_LS,APA_LS;
BO_TX_BU_ 1589 : TIM_A_LS,VIS2_LS;
BO_TX_BU_ 589 : CGM_LS,CSM_LS,TestTool_LS;
BO_TX_BU_ 2151874560 : TCP_LS,CGM_LS,ONSTAR_LS;
BO_TX_BU_ 1357 : CGM_LS,TCP_LS,LVMNav_LS,UHP_Low,ONSTAR_LS;
BO_TX_BU_ 1613 : CGM_LS,TCP_LS,LVMNav_LS,UHP_Low,ONSTAR_LS;
BO_TX_BU_ 2150268928 : TCP_LS,CGM_LS,ONSTAR_LS;
BO_TX_BU_ 606 : CSM_LS,CGM_LS,TCP_LS,ONSTAR_LS,TestTool_LS;
BO_TX_BU_ 257 : CSM_LS,CGM_LS,TCP_LS,ONSTAR_LS,TestTool_LS;
BO_TX_BU_ 1587 : CGM_LS,TIM_LS;
BO_TX_BU_ 1608 : CGM_LS,HFP_LS,PDIM_LS;
BO_TX_BU_ 584 : CSM_LS,CGM_LS,TCP_LS,ONSTAR_LS,TestTool_LS;
BO_TX_BU_ 1352 : CGM_LS,HFP_LS,PDIM_LS;
BO_TX_BU_ 1620 : CGM_LS,AMP_LS;
BO_TX_BU_ 1364 : CGM_LS,AMP_LS;
BO_TX_BU_ 583 : CSM_LS,CGM_LS,TCP_LS,ONSTAR_LS,TestTool_LS;
BO_TX_BU_ 1371 : CGM_LS,V2V_LS,ARB_LS;
BO_TX_BU_ 1627 : CGM_LS,V2V_LS,ARB_LS;
BO_TX_BU_ 603 : CSM_LS,CGM_LS,TCP_LS,ONSTAR_LS,TestTool_LS;
BO_TX_BU_ 602 : CSM_LS,CGM_LS,TCP_LS,ONSTAR_LS,TestTool_LS;
BO_TX_BU_ 598 : CGM_LS,CSM_LS,TCP_LS,ONSTAR_LS,TestTool_LS;
BO_TX_BU_ 1366 : CGM_LS,TIM_B_LS,RSE_LS,RSA_LS;
BO_TX_BU_ 1622 : CGM_LS,TIM_B_LS,RSE_LS,RSA_LS;
BO_TX_BU_ 580 : CGM_LS,TCP_LS,ONSTAR_LS,TestTool_LS;
BO_TX_BU_ 1604 : CGM_LS,CSM_LS,CHM_LS,RadioHead_LS;
BO_TX_BU_ 1348 : CGM_LS,CSM_LS,CHM_LS,RadioHead_LS;
BO_TX_BU_ 1615 : STC_LS,PTM_LS;
BO_TX_BU_ 1359 : STC_LS,PTM_LS;
BO_TX_BU_ 591 : CSM_LS,CGM_LS,TCP_LS,ONSTAR_LS,TestTool_LS;
BO_TX_BU_ 578 : CSM_LS,CGM_LS,TCP_LS,ONSTAR_LS,TestTool_LS;
BO_TX_BU_ 1614 : CGM_LS,VKM_LS,RSC_LS,PSD_R_LS;
BO_TX_BU_ 1358 : CGM_LS,VKM_LS,RSC_LS,PSD_R_LS;
BO_TX_BU_ 1356 : CGM_LS,IPC_LS;
BO_TX_BU_ 1612 : CGM_LS,IPC_LS;
BO_TX_BU_ 588 : CGM_LS,CSM_LS,TCP_LS,ONSTAR_LS,TestTool_LS;
BO_TX_BU_ 1360 : CGM_LS,VPM_LS,HUD_LS;
BO_TX_BU_ 1616 : CGM_LS,VPM_LS,HUD_LS;
BO_TX_BU_ 592 : CGM_LS,CSM_LS,TCP_LS,ONSTAR_LS,TestTool_LS;
BO_TX_BU_ 1375 : CGM_LS,RCRM_LS,ISRVM_LS,HBSM_LS;
BO_TX_BU_ 1631 : CGM_LS,RCRM_LS,ISRVM_LS,HBSM_LS;
BO_TX_BU_ 607 : CSM_LS,CGM_LS,TCP_LS,ONSTAR_LS,TestTool_LS;
BO_TX_BU_ 593 : CSM_LS,CGM_LS,TCP_LS,ONSTAR_LS,TestTool_LS;
BO_TX_BU_ 1362 : CGM_LS,TouchPad_LS,DVB_T_LS;
BO_TX_BU_ 1618 : CGM_LS,TouchPad_LS,DVB_T_LS;
BO_TX_BU_ 594 : CGM_LS,CSM_LS,TCP_LS,ONSTAR_LS,TestTool_LS;
BO_TX_BU_ 1373 : HVSM_F_LS,MSM_LS;
BO_TX_BU_ 1629 : HVSM_F_LS,MSM_LS;
BO_TX_BU_ 605 : CSM_LS,CGM_LS,TCP_LS,ONSTAR_LS,TestTool_LS;
BO_TX_BU_ 577 : CSM_LS,CGM_LS,TCP_LS,ONSTAR_LS,TestTool_LS;
BO_TX_BU_ 601 : CSM_LS,CGM_LS,TCP_LS,ONSTAR_LS,TestTool_LS;
BO_TX_BU_ 1369 : UPA_LS,APA_LS;
BO_TX_BU_ 595 : CGM_LS,CSM_LS,TCP_LS,ONSTAR_LS,TestTool_LS;
BO_TX_BU_ 1581 : CGM_LS,TCP_LS,LVMNav_LS,UHP_Low,ONSTAR_LS;
BO_TX_BU_ 1580 : CGM_LS,IPC_LS;
BO_TX_BU_ 1584 : CGM_LS,VPM_LS,HUD_LS;
BO_TX_BU_ 1588 : CGM_LS,AMP_LS;
BO_TX_BU_ 2151677952 : CSM_LS,V2V_LS,TCP_LS,MSM_RR_LS,MSM_LR_LS,VPM_LS,EOCM2A_K2_LS,VIS2_LS,SBZA_R_LS,SBZA_L_LS,PSD_R_LS,PSD_L_LS,BSM_LS,VICM_LS,EOCM_F_LS,STC_LS,FCM_LS,TIM_B_LS,TIM_A_LS,TIM_LS,CHUD_LS,HUD_LS,ONSTAR_LS,RadioHead_LS,LCM_LS,PTM_LS,BCM_LS,SDM_LS,UPA_LS,APA_LS,IPC_LS,MSM_P_LS,MSM_LS;
BO_TX_BU_ 2156175360 : CGM_LS,IPC_LS;
CM_ SG_ 2150785024 AirbgAccelOrien "Orientation of first accelerometer axis.  0 degrees is right side of vehicle, 90 degrees is front of vehicle.  Second axis given by adding 90 degrees to first axis.";
CM_ SG_ 2151874560 ESEIC_EngImRqPsw "Desc: 7 ASCII characters";
BA_DEF_ SG_  "VNSigPrimaryTriggering" ENUM  "No","Yes","DLCLS","DLCHS","DLCCE","DLCFO";
BA_DEF_ SG_  "VNSigRemoteDiagnostics" ENUM  "No","Yes","DLCLS","DLCHS","DLCCE","DLCFO";
BA_DEF_ SG_  "VNSigInfotainment" ENUM  "No","Yes","DLCLS","DLCHS","DLCCE","DLCFO";
BA_DEF_ SG_  "VNSigParkedVehicle" ENUM  "No","Yes","DLCLS","DLCHS","DLCCE","DLCFO";
BA_DEF_ SG_  "VNSigIntermediate" ENUM  "No","Yes","DLCLS","DLCHS","DLCCE","DLCFO";
BA_DEF_ SG_  "VNSigUnused_4" ENUM  "No","Yes","DLCLS","DLCHS","DLCCE","DLCFO";
BA_DEF_ SG_  "SignalType" STRING ;
BA_DEF_ SG_  "PacketOrder" INT 0 65535;
BA_DEF_ SG_  "SignalLongName" STRING ;
BA_DEF_ SG_  "GenSigStartValue" INT 0 65535;
BA_DEF_ SG_  "VNSigDiagnostic" ENUM  "No","Yes","DLCLS","DLCHS","DLCCE","DLCFO";
BA_DEF_ SG_  "VNSigAllNodes" ENUM  "No","Yes","DLCLS","DLCHS","DLCCE","DLCFO";
BA_DEF_ SG_  "GenSigDeltaValue" INT 0 0;
BA_DEF_ SG_  "GenSigInactiveValue" INT 0 0;
BA_DEF_ SG_  "GenSigSendType" ENUM  "not used","not used","not used","not used","not used","not used","not used","NoSigSendType","not used","not used","OnAnyChange","OnChangeIfActive","OnDelta","DLCLS","DLCHS","DLCCE","DLCFO";
BA_DEF_ SG_  "GenSigSendOnInit" ENUM  "Not Initialized","Application","Handler","DLCLS","DLCHS","DLCCE","DLCFO";
BA_DEF_ BO_  "AppGenMsgCycleTime" INT 0 0;
BA_DEF_ BO_  "TpTxIndex" INT 0 99;
BA_DEF_ BO_  "GenMsgILSupport" ENUM  "No","Yes","DLCLS","DLCHS","DLCCE","DLCFO";
BA_DEF_ BO_  "TpApplType" STRING ;
BA_DEF_ BO_  "Prio" INT 0 7;
BA_DEF_ BO_  "MessageSubnet" ENUM  "LS","MS","HS","CE","PE","HV","FO","S1","HE","LE","HE2","DLCLS","DLCHS","DLCCE","DLCFO";
BA_DEF_ BO_  "GenMsgMandatoryToSupervision" ENUM  "No","Yes","DLCLS","DLCHS","DLCCE","DLCFO";
BA_DEF_ BO_  "DiagState" ENUM  "No","Yes","DLCLS","DLCHS","DLCCE","DLCFO";
BA_DEF_ BO_  "GenMsgStartDelayTime" INT 0 100000;
BA_DEF_ BO_  "GenMsgDelayTime" INT 0 100000;
BA_DEF_ BO_  "GenMsgCycleTime" INT 0 100000;
BA_DEF_ BO_  "GenMsgSendType" ENUM  "cyclicX","spontanX","cyclicIfActiveX","spontanWithDelay","cyclicAndSpontanX","cyclicAndSpontanWithDelay","spontanWithRepitition","cyclicIfActiveAndSpontanWD","DLCLS","DLCHS","DLCCE","DLCFO";
BA_DEF_ BO_  "DiagResponse" ENUM  "No","Yes","DLCLS","DLCHS","DLCCE","DLCFO";
BA_DEF_ BO_  "DiagRequest" ENUM  "No","Yes","DLCLS","DLCHS","DLCCE","DLCFO";
BA_DEF_ BO_  "NmMessage" ENUM  "No","Yes","DLCLS","DLCHS","DLCCE","DLCFO";
BA_DEF_REL_ BU_SG_REL_  "GenSigSuprvRespComment" STRING ;
BA_DEF_REL_ BU_SG_REL_  "GenSigVBitResp" ENUM  "No","Yes","DLCLS","DLCHS","DLCCE","DLCFO";
BA_DEF_REL_ BU_SG_REL_  "GenSigVBitRespComment" STRING ;
BA_DEF_REL_ BU_SG_REL_  "GenSigVDAFailComment" STRING ;
BA_DEF_REL_ BU_SG_REL_  "GenSigVDAFailResp" ENUM  "No","Yes","DLCLS","DLCHS","DLCCE","DLCFO";
BA_DEF_REL_ BU_SG_REL_  "GenSigRxStartValue" STRING ;
BA_DEF_REL_ BU_SG_REL_  "GenSigSuprvRespSubValue" INT 0 65535;
BA_DEF_REL_ BU_SG_REL_  "GenSigSuprvResp" ENUM  "None","Notify App","Substitute Default","DLCLS","DLCHS","DLCCE","DLCFO";
BA_DEF_REL_ BU_SG_REL_  "GenSigTimeoutMsg" HEX -2147483648 268435455;
BA_DEF_REL_ BU_SG_REL_  "GenSigTimeoutTime" INT 0 15000;
BA_DEF_DEF_  "VNSigPrimaryTriggering" "No";
BA_DEF_DEF_  "VNSigRemoteDiagnostics" "No";
BA_DEF_DEF_  "VNSigInfotainment" "No";
BA_DEF_DEF_  "VNSigParkedVehicle" "No";
BA_DEF_DEF_  "VNSigIntermediate" "No";
BA_DEF_DEF_  "VNSigUnused_4" "No";
BA_DEF_DEF_  "SignalType" "";
BA_DEF_DEF_  "PacketOrder" 0;
BA_DEF_DEF_  "SignalLongName" "";
BA_DEF_DEF_  "GenSigStartValue" 0;
BA_DEF_DEF_  "VNSigDiagnostic" "No";
BA_DEF_DEF_  "VNSigAllNodes" "No";
BA_DEF_DEF_  "GenSigDeltaValue" 0;
BA_DEF_DEF_  "GenSigInactiveValue" 0;
BA_DEF_DEF_  "GenSigSendType" "NoSigSendType";
BA_DEF_DEF_  "GenSigSendOnInit" "Not Initialized";
BA_DEF_DEF_  "AppGenMsgCycleTime" 0;
BA_DEF_DEF_  "TpTxIndex" 0;
BA_DEF_DEF_  "GenMsgILSupport" "Yes";
BA_DEF_DEF_  "TpApplType" "";
BA_DEF_DEF_  "Prio" 4;
BA_DEF_DEF_  "MessageSubnet" "FO";
BA_DEF_DEF_  "GenMsgMandatoryToSupervision" "No";
BA_DEF_DEF_  "DiagState" "No";
BA_DEF_DEF_  "GenMsgStartDelayTime" 0;
BA_DEF_DEF_  "GenMsgDelayTime" 0;
BA_DEF_DEF_  "GenMsgCycleTime" 0;
BA_DEF_DEF_  "GenMsgSendType" "spontanX";
BA_DEF_DEF_  "DiagResponse" "No";
BA_DEF_DEF_  "DiagRequest" "No";
BA_DEF_DEF_  "NmMessage" "No";
BA_DEF_DEF_REL_ "GenSigSuprvRespComment" "";
BA_DEF_DEF_REL_ "GenSigVBitResp" "No";
BA_DEF_DEF_REL_ "GenSigVBitRespComment" "";
BA_DEF_DEF_REL_ "GenSigVDAFailComment" "";
BA_DEF_DEF_REL_ "GenSigVDAFailResp" "No";
BA_DEF_DEF_REL_ "GenSigRxStartValue" "";
BA_DEF_DEF_REL_ "GenSigSuprvRespSubValue" 0;
BA_DEF_DEF_REL_ "GenSigSuprvResp" "None";
BA_DEF_DEF_REL_ "GenSigTimeoutMsg" 0;
BA_DEF_DEF_REL_ "GenSigTimeoutTime" 0;
BA_ "Prio" BO_ 2151235584 3;
BA_ "MessageSubnet" BO_ 2151235584 0;
BA_ "GenMsgDelayTime" BO_ 2151235584 100;
BA_ "MessageSubnet" BO_ 2150809600 0;
BA_ "GenMsgDelayTime" BO_ 2150809600 10;
BA_ "MessageSubnet" BO_ 2150793216 0;
BA_ "GenMsgDelayTime" BO_ 2150793216 10;
BA_ "MessageSubnet" BO_ 2150801408 0;
BA_ "GenMsgDelayTime" BO_ 2150801408 10;
BA_ "MessageSubnet" BO_ 2150785024 0;
BA_ "GenMsgDelayTime" BO_ 2150785024 10;
BA_ "MessageSubnet" BO_ 2151202816 0;
BA_ "GenMsgDelayTime" BO_ 2151202816 100;
BA_ "MessageSubnet" BO_ 2150825984 0;
BA_ "GenMsgDelayTime" BO_ 2150825984 10;
BA_ "Prio" BO_ 2151759872 3;
BA_ "MessageSubnet" BO_ 2151759872 0;
BA_ "GenMsgDelayTime" BO_ 2151759872 100;
BA_ "MessageSubnet" BO_ 2149974016 0;
BA_ "GenMsgDelayTime" BO_ 2149974016 100;
BA_ "MessageSubnet" BO_ 2151907328 0;
BA_ "GenMsgDelayTime" BO_ 2151907328 100;
BA_ "Prio" BO_ 1579 0;
BA_ "MessageSubnet" BO_ 1579 0;
BA_ "GenMsgCycleTime" BO_ 1579 3000;
BA_ "GenMsgSendType" BO_ 1579 0;
BA_ "NmMessage" BO_ 1579 1;
BA_ "Prio" BO_ 1599 0;
BA_ "MessageSubnet" BO_ 1599 0;
BA_ "GenMsgCycleTime" BO_ 1599 3000;
BA_ "GenMsgSendType" BO_ 1599 0;
BA_ "NmMessage" BO_ 1599 1;
BA_ "Prio" BO_ 1583 0;
BA_ "MessageSubnet" BO_ 1583 0;
BA_ "GenMsgCycleTime" BO_ 1583 3000;
BA_ "GenMsgSendType" BO_ 1583 0;
BA_ "NmMessage" BO_ 1583 1;
BA_ "Prio" BO_ 1585 0;
BA_ "MessageSubnet" BO_ 1585 0;
BA_ "GenMsgCycleTime" BO_ 1585 3000;
BA_ "GenMsgSendType" BO_ 1585 0;
BA_ "NmMessage" BO_ 1585 1;
BA_ "Prio" BO_ 1586 0;
BA_ "MessageSubnet" BO_ 1586 0;
BA_ "GenMsgCycleTime" BO_ 1586 3000;
BA_ "GenMsgSendType" BO_ 1586 0;
BA_ "NmMessage" BO_ 1586 1;
BA_ "Prio" BO_ 1591 0;
BA_ "MessageSubnet" BO_ 1591 0;
BA_ "GenMsgCycleTime" BO_ 1591 3000;
BA_ "GenMsgSendType" BO_ 1591 0;
BA_ "NmMessage" BO_ 1591 1;
BA_ "Prio" BO_ 1572 0;
BA_ "MessageSubnet" BO_ 1572 0;
BA_ "GenMsgCycleTime" BO_ 1572 3000;
BA_ "GenMsgSendType" BO_ 1572 0;
BA_ "NmMessage" BO_ 1572 1;
BA_ "Prio" BO_ 1578 0;
BA_ "MessageSubnet" BO_ 1578 0;
BA_ "GenMsgCycleTime" BO_ 1578 3000;
BA_ "GenMsgSendType" BO_ 1578 0;
BA_ "NmMessage" BO_ 1578 1;
BA_ "Prio" BO_ 1597 0;
BA_ "MessageSubnet" BO_ 1597 0;
BA_ "GenMsgCycleTime" BO_ 1597 3000;
BA_ "GenMsgSendType" BO_ 1597 0;
BA_ "NmMessage" BO_ 1597 1;
BA_ "Prio" BO_ 1598 0;
BA_ "MessageSubnet" BO_ 1598 0;
BA_ "GenMsgCycleTime" BO_ 1598 3000;
BA_ "GenMsgSendType" BO_ 1598 0;
BA_ "NmMessage" BO_ 1598 1;
BA_ "Prio" BO_ 1576 0;
BA_ "MessageSubnet" BO_ 1576 0;
BA_ "GenMsgCycleTime" BO_ 1576 3000;
BA_ "GenMsgSendType" BO_ 1576 0;
BA_ "NmMessage" BO_ 1576 1;
BA_ "Prio" BO_ 1582 0;
BA_ "MessageSubnet" BO_ 1582 0;
BA_ "GenMsgCycleTime" BO_ 1582 3000;
BA_ "GenMsgSendType" BO_ 1582 0;
BA_ "NmMessage" BO_ 1582 1;
BA_ "Prio" BO_ 1590 0;
BA_ "MessageSubnet" BO_ 1590 0;
BA_ "GenMsgCycleTime" BO_ 1590 3000;
BA_ "GenMsgSendType" BO_ 1590 0;
BA_ "NmMessage" BO_ 1590 1;
BA_ "Prio" BO_ 1592 0;
BA_ "MessageSubnet" BO_ 1592 0;
BA_ "GenMsgCycleTime" BO_ 1592 3000;
BA_ "GenMsgSendType" BO_ 1592 0;
BA_ "NmMessage" BO_ 1592 1;
BA_ "Prio" BO_ 1594 0;
BA_ "MessageSubnet" BO_ 1594 0;
BA_ "GenMsgCycleTime" BO_ 1594 3000;
BA_ "GenMsgSendType" BO_ 1594 0;
BA_ "NmMessage" BO_ 1594 1;
BA_ "Prio" BO_ 1595 0;
BA_ "MessageSubnet" BO_ 1595 0;
BA_ "GenMsgCycleTime" BO_ 1595 3000;
BA_ "GenMsgSendType" BO_ 1595 0;
BA_ "NmMessage" BO_ 1595 1;
BA_ "Prio" BO_ 1593 0;
BA_ "MessageSubnet" BO_ 1593 0;
BA_ "GenMsgCycleTime" BO_ 1593 3000;
BA_ "GenMsgSendType" BO_ 1593 0;
BA_ "NmMessage" BO_ 1593 1;
BA_ "Prio" BO_ 1589 0;
BA_ "MessageSubnet" BO_ 1589 0;
BA_ "GenMsgCycleTime" BO_ 1589 3000;
BA_ "GenMsgSendType" BO_ 1589 0;
BA_ "NmMessage" BO_ 1589 1;
BA_ "MessageSubnet" BO_ 2150219776 0;
BA_ "GenMsgDelayTime" BO_ 2150219776 10;
BA_ "Prio" BO_ 589 0;
BA_ "MessageSubnet" BO_ 589 0;
BA_ "DiagRequest" BO_ 589 1;
BA_ "MessageSubnet" BO_ 2152685568 0;
BA_ "GenMsgDelayTime" BO_ 2152685568 10;
BA_ "MessageSubnet" BO_ 2151874560 0;
BA_ "GenMsgDelayTime" BO_ 2151874560 100;
BA_ "GenMsgILSupport" BO_ 1357 0;
BA_ "TpApplType" BO_ 1357 "DiagUUDTResponse";
BA_ "Prio" BO_ 1357 0;
BA_ "MessageSubnet" BO_ 1357 0;
BA_ "Prio" BO_ 1613 0;
BA_ "MessageSubnet" BO_ 1613 0;
BA_ "DiagResponse" BO_ 1613 1;
BA_ "MessageSubnet" BO_ 2150268928 0;
BA_ "GenMsgDelayTime" BO_ 2150268928 100;
BA_ "Prio" BO_ 606 0;
BA_ "MessageSubnet" BO_ 606 0;
BA_ "DiagRequest" BO_ 606 1;
BA_ "GenMsgILSupport" BO_ 257 0;
BA_ "Prio" BO_ 257 0;
BA_ "MessageSubnet" BO_ 257 0;
BA_ "DiagState" BO_ 257 1;
BA_ "Prio" BO_ 1587 0;
BA_ "MessageSubnet" BO_ 1587 0;
BA_ "GenMsgCycleTime" BO_ 1587 3000;
BA_ "GenMsgSendType" BO_ 1587 0;
BA_ "NmMessage" BO_ 1587 1;
BA_ "Prio" BO_ 2041 0;
BA_ "MessageSubnet" BO_ 2041 0;
BA_ "Prio" BO_ 1608 0;
BA_ "MessageSubnet" BO_ 1608 0;
BA_ "DiagResponse" BO_ 1608 1;
BA_ "Prio" BO_ 584 0;
BA_ "MessageSubnet" BO_ 584 0;
BA_ "DiagRequest" BO_ 584 1;
BA_ "GenMsgILSupport" BO_ 1352 0;
BA_ "TpApplType" BO_ 1352 "DiagUUDTResponse";
BA_ "Prio" BO_ 1352 0;
BA_ "MessageSubnet" BO_ 1352 0;
BA_ "Prio" BO_ 1620 0;
BA_ "MessageSubnet" BO_ 1620 0;
BA_ "DiagResponse" BO_ 1620 1;
BA_ "GenMsgILSupport" BO_ 1364 0;
BA_ "TpApplType" BO_ 1364 "DiagUUDTResponse";
BA_ "Prio" BO_ 1364 0;
BA_ "MessageSubnet" BO_ 1364 0;
BA_ "GenMsgILSupport" BO_ 1351 0;
BA_ "TpApplType" BO_ 1351 "DiagUUDTResponse";
BA_ "Prio" BO_ 1351 0;
BA_ "MessageSubnet" BO_ 1351 0;
BA_ "Prio" BO_ 1607 0;
BA_ "MessageSubnet" BO_ 1607 0;
BA_ "DiagResponse" BO_ 1607 1;
BA_ "Prio" BO_ 583 0;
BA_ "MessageSubnet" BO_ 583 0;
BA_ "DiagRequest" BO_ 583 1;
BA_ "GenMsgILSupport" BO_ 1371 0;
BA_ "TpApplType" BO_ 1371 "DiagUUDTResponse";
BA_ "Prio" BO_ 1371 0;
BA_ "MessageSubnet" BO_ 1371 0;
BA_ "Prio" BO_ 1627 0;
BA_ "MessageSubnet" BO_ 1627 0;
BA_ "DiagResponse" BO_ 1627 1;
BA_ "Prio" BO_ 603 0;
BA_ "MessageSubnet" BO_ 603 0;
BA_ "DiagRequest" BO_ 603 1;
BA_ "GenMsgILSupport" BO_ 1370 0;
BA_ "TpApplType" BO_ 1370 "DiagUUDTResponse";
BA_ "Prio" BO_ 1370 0;
BA_ "MessageSubnet" BO_ 1370 0;
BA_ "Prio" BO_ 1626 0;
BA_ "MessageSubnet" BO_ 1626 0;
BA_ "DiagResponse" BO_ 1626 1;
BA_ "Prio" BO_ 602 0;
BA_ "MessageSubnet" BO_ 602 0;
BA_ "DiagRequest" BO_ 602 1;
BA_ "Prio" BO_ 598 0;
BA_ "MessageSubnet" BO_ 598 0;
BA_ "DiagRequest" BO_ 598 1;
BA_ "GenMsgILSupport" BO_ 1366 0;
BA_ "TpApplType" BO_ 1366 "DiagUUDTResponse";
BA_ "Prio" BO_ 1366 0;
BA_ "MessageSubnet" BO_ 1366 0;
BA_ "Prio" BO_ 1622 0;
BA_ "MessageSubnet" BO_ 1622 0;
BA_ "DiagResponse" BO_ 1622 1;
BA_ "Prio" BO_ 580 0;
BA_ "MessageSubnet" BO_ 580 0;
BA_ "DiagRequest" BO_ 580 1;
BA_ "Prio" BO_ 1604 0;
BA_ "MessageSubnet" BO_ 1604 0;
BA_ "DiagResponse" BO_ 1604 1;
BA_ "TpApplType" BO_ 1348 "DiagUUDTResponse";
BA_ "Prio" BO_ 1348 0;
BA_ "MessageSubnet" BO_ 1348 0;
BA_ "Prio" BO_ 1615 0;
BA_ "MessageSubnet" BO_ 1615 0;
BA_ "DiagResponse" BO_ 1615 1;
BA_ "GenMsgILSupport" BO_ 1359 0;
BA_ "TpApplType" BO_ 1359 "DiagUUDTResponse";
BA_ "Prio" BO_ 1359 0;
BA_ "MessageSubnet" BO_ 1359 0;
BA_ "Prio" BO_ 591 0;
BA_ "MessageSubnet" BO_ 591 0;
BA_ "DiagRequest" BO_ 591 1;
BA_ "Prio" BO_ 1602 0;
BA_ "MessageSubnet" BO_ 1602 0;
BA_ "DiagResponse" BO_ 1602 1;
BA_ "GenMsgILSupport" BO_ 1346 0;
BA_ "TpApplType" BO_ 1346 "DiagUUDTResponse";
BA_ "Prio" BO_ 1346 0;
BA_ "MessageSubnet" BO_ 1346 0;
BA_ "Prio" BO_ 578 0;
BA_ "MessageSubnet" BO_ 578 0;
BA_ "DiagRequest" BO_ 578 1;
BA_ "Prio" BO_ 1614 0;
BA_ "MessageSubnet" BO_ 1614 0;
BA_ "DiagResponse" BO_ 1614 1;
BA_ "GenMsgILSupport" BO_ 1358 0;
BA_ "TpApplType" BO_ 1358 "DiagUUDTResponse";
BA_ "Prio" BO_ 1358 0;
BA_ "MessageSubnet" BO_ 1358 0;
BA_ "GenMsgILSupport" BO_ 1356 0;
BA_ "TpApplType" BO_ 1356 "DiagUUDTResponse";
BA_ "Prio" BO_ 1356 0;
BA_ "MessageSubnet" BO_ 1356 0;
BA_ "Prio" BO_ 1612 0;
BA_ "MessageSubnet" BO_ 1612 0;
BA_ "DiagResponse" BO_ 1612 1;
BA_ "Prio" BO_ 588 0;
BA_ "MessageSubnet" BO_ 588 0;
BA_ "DiagRequest" BO_ 588 1;
BA_ "GenMsgILSupport" BO_ 1360 0;
BA_ "TpApplType" BO_ 1360 "DiagUUDTResponse";
BA_ "Prio" BO_ 1360 0;
BA_ "MessageSubnet" BO_ 1360 0;
BA_ "Prio" BO_ 1616 0;
BA_ "MessageSubnet" BO_ 1616 0;
BA_ "DiagResponse" BO_ 1616 1;
BA_ "Prio" BO_ 592 0;
BA_ "MessageSubnet" BO_ 592 0;
BA_ "DiagRequest" BO_ 592 1;
BA_ "GenMsgILSupport" BO_ 1375 0;
BA_ "TpApplType" BO_ 1375 "DiagUUDTResponse";
BA_ "Prio" BO_ 1375 0;
BA_ "MessageSubnet" BO_ 1375 0;
BA_ "Prio" BO_ 1631 0;
BA_ "MessageSubnet" BO_ 1631 0;
BA_ "DiagResponse" BO_ 1631 1;
BA_ "Prio" BO_ 607 0;
BA_ "MessageSubnet" BO_ 607 0;
BA_ "DiagRequest" BO_ 607 1;
BA_ "GenMsgILSupport" BO_ 1361 0;
BA_ "TpApplType" BO_ 1361 "DiagUUDTResponse";
BA_ "Prio" BO_ 1361 0;
BA_ "MessageSubnet" BO_ 1361 0;
BA_ "Prio" BO_ 1617 0;
BA_ "MessageSubnet" BO_ 1617 0;
BA_ "DiagResponse" BO_ 1617 1;
BA_ "Prio" BO_ 593 0;
BA_ "MessageSubnet" BO_ 593 0;
BA_ "DiagRequest" BO_ 593 1;
BA_ "GenMsgILSupport" BO_ 1362 0;
BA_ "TpApplType" BO_ 1362 "DiagUUDTResponse";
BA_ "Prio" BO_ 1362 0;
BA_ "MessageSubnet" BO_ 1362 0;
BA_ "Prio" BO_ 1618 0;
BA_ "MessageSubnet" BO_ 1618 0;
BA_ "DiagResponse" BO_ 1618 1;
BA_ "Prio" BO_ 594 0;
BA_ "MessageSubnet" BO_ 594 0;
BA_ "DiagRequest" BO_ 594 1;
BA_ "GenMsgILSupport" BO_ 1373 0;
BA_ "TpApplType" BO_ 1373 "DiagUUDTResponse";
BA_ "Prio" BO_ 1373 0;
BA_ "MessageSubnet" BO_ 1373 0;
BA_ "Prio" BO_ 1629 0;
BA_ "MessageSubnet" BO_ 1629 0;
BA_ "DiagResponse" BO_ 1629 1;
BA_ "Prio" BO_ 605 0;
BA_ "MessageSubnet" BO_ 605 0;
BA_ "DiagRequest" BO_ 605 1;
BA_ "GenMsgILSupport" BO_ 1345 0;
BA_ "TpApplType" BO_ 1345 "DiagUUDTResponse";
BA_ "Prio" BO_ 1345 0;
BA_ "MessageSubnet" BO_ 1345 0;
BA_ "Prio" BO_ 1601 0;
BA_ "MessageSubnet" BO_ 1601 0;
BA_ "DiagResponse" BO_ 1601 1;
BA_ "Prio" BO_ 577 0;
BA_ "MessageSubnet" BO_ 577 0;
BA_ "DiagRequest" BO_ 577 1;
BA_ "Prio" BO_ 601 0;
BA_ "MessageSubnet" BO_ 601 0;
BA_ "DiagRequest" BO_ 601 1;
BA_ "GenMsgILSupport" BO_ 1369 0;
BA_ "TpApplType" BO_ 1369 "DiagUUDTResponse";
BA_ "Prio" BO_ 1369 0;
BA_ "MessageSubnet" BO_ 1369 0;
BA_ "Prio" BO_ 595 0;
BA_ "MessageSubnet" BO_ 595 0;
BA_ "DiagRequest" BO_ 595 1;
BA_ "Prio" BO_ 1575 0;
BA_ "MessageSubnet" BO_ 1575 0;
BA_ "GenMsgCycleTime" BO_ 1575 3000;
BA_ "GenMsgSendType" BO_ 1575 0;
BA_ "NmMessage" BO_ 1575 1;
BA_ "Prio" BO_ 1581 0;
BA_ "MessageSubnet" BO_ 1581 0;
BA_ "GenMsgCycleTime" BO_ 1581 3000;
BA_ "GenMsgSendType" BO_ 1581 0;
BA_ "NmMessage" BO_ 1581 1;
BA_ "Prio" BO_ 1580 0;
BA_ "MessageSubnet" BO_ 1580 0;
BA_ "GenMsgCycleTime" BO_ 1580 3000;
BA_ "GenMsgSendType" BO_ 1580 0;
BA_ "NmMessage" BO_ 1580 1;
BA_ "Prio" BO_ 1584 0;
BA_ "MessageSubnet" BO_ 1584 0;
BA_ "GenMsgCycleTime" BO_ 1584 3000;
BA_ "GenMsgSendType" BO_ 1584 0;
BA_ "NmMessage" BO_ 1584 1;
BA_ "Prio" BO_ 1569 0;
BA_ "MessageSubnet" BO_ 1569 0;
BA_ "GenMsgCycleTime" BO_ 1569 1000;
BA_ "GenMsgSendType" BO_ 1569 0;
BA_ "NmMessage" BO_ 1569 1;
BA_ "Prio" BO_ 1573 0;
BA_ "MessageSubnet" BO_ 1573 0;
BA_ "GenMsgCycleTime" BO_ 1573 3000;
BA_ "GenMsgSendType" BO_ 1573 0;
BA_ "NmMessage" BO_ 1573 1;
BA_ "Prio" BO_ 1588 0;
BA_ "MessageSubnet" BO_ 1588 0;
BA_ "GenMsgCycleTime" BO_ 1588 3000;
BA_ "GenMsgSendType" BO_ 1588 0;
BA_ "NmMessage" BO_ 1588 1;
BA_ "MessageSubnet" BO_ 2150137856 0;
BA_ "GenMsgDelayTime" BO_ 2150137856 100;
BA_ "MessageSubnet" BO_ 2151677952 0;
BA_ "GenMsgDelayTime" BO_ 2151677952 100;
BA_ "MessageSubnet" BO_ 2150776832 0;
BA_ "GenMsgDelayTime" BO_ 2150776832 10;
BA_ "GenMsgCycleTime" BO_ 2150776832 2000;
BA_ "GenMsgSendType" BO_ 2150776832 0;
BA_ "MessageSubnet" BO_ 2150760448 0;
BA_ "GenMsgDelayTime" BO_ 2150760448 10;
BA_ "Prio" BO_ 2155872256 3;
BA_ "MessageSubnet" BO_ 2155872256 0;
BA_ "GenMsgStartDelayTime" BO_ 2155872256 190;
BA_ "GenMsgCycleTime" BO_ 2155872256 250;
BA_ "GenMsgSendType" BO_ 2155872256 0;
BA_ "MessageSubnet" BO_ 2156175360 0;
BA_ "GenMsgDelayTime" BO_ 2156175360 50;
BA_ "GenSigSendType" SG_ 2151235584 EhnSrvImmbComRst 10;
BA_ "SignalType" SG_ 2151235584 EhnSrvImmbComRst "BLN";
BA_ "SignalLongName" SG_ 2151235584 EhnSrvImmbComRst "Enhanced Services Immobilization Command Reset";
BA_ "VNSigAllNodes" SG_ 2151235584 EhnSrvImmbComRst 1;
BA_ "GenSigDeltaValue" SG_ 2151235584 NmofPrgKFbExtd 1;
BA_ "GenSigSendType" SG_ 2151235584 NmofPrgKFbExtd 12;
BA_ "SignalType" SG_ 2151235584 NmofPrgKFbExtd "UNM";
BA_ "SignalLongName" SG_ 2151235584 NmofPrgKFbExtd "Number of Programmed Keyfobs Extended";
BA_ "VNSigAllNodes" SG_ 2151235584 NmofPrgKFbExtd 1;
BA_ "GenSigSendType" SG_ 2151235584 AlcKyIIncmIndOn 10;
BA_ "SignalType" SG_ 2151235584 AlcKyIIncmIndOn "BLN";
BA_ "SignalLongName" SG_ 2151235584 AlcKyIIncmIndOn "Alco Key Incomplete Indication On";
BA_ "VNSigAllNodes" SG_ 2151235584 AlcKyIIncmIndOn 1;
BA_ "GenSigSendType" SG_ 2151235584 VehSecAuthnSesComp 10;
BA_ "SignalType" SG_ 2151235584 VehSecAuthnSesComp "BLN";
BA_ "SignalLongName" SG_ 2151235584 VehSecAuthnSesComp "Vehicle Security Authentication Session Completed";
BA_ "VNSigAllNodes" SG_ 2151235584 VehSecAuthnSesComp 1;
BA_ "GenSigSendType" SG_ 2151235584 VTDTmprDetected 10;
BA_ "SignalType" SG_ 2151235584 VTDTmprDetected "BLN";
BA_ "SignalLongName" SG_ 2151235584 VTDTmprDetected "Vehicle Theft Deterrent Tamper Detected";
BA_ "VNSigAllNodes" SG_ 2151235584 VTDTmprDetected 1;
BA_ "GenSigSendType" SG_ 2151235584 VehSecSysFldIO 10;
BA_ "SignalType" SG_ 2151235584 VehSecSysFldIO "BLN";
BA_ "SignalLongName" SG_ 2151235584 VehSecSysFldIO "Vehicle Security System Failed Indication On";
BA_ "VNSigAllNodes" SG_ 2151235584 VehSecSysFldIO 1;
BA_ "GenSigSendType" SG_ 2151235584 VehSecStrgColLckPwdV 10;
BA_ "SignalType" SG_ 2151235584 VehSecStrgColLckPwdV "ENM";
BA_ "SignalLongName" SG_ 2151235584 VehSecStrgColLckPwdV "Vehicle Security Steering Column Lock Password Validity";
BA_ "VNSigAllNodes" SG_ 2151235584 VehSecStrgColLckPwdV 1;
BA_ "GenSigDeltaValue" SG_ 2151235584 VehSecStrgColLckPwd 1;
BA_ "GenSigSendType" SG_ 2151235584 VehSecStrgColLckPwd 12;
BA_ "SignalType" SG_ 2151235584 VehSecStrgColLckPwd "UNM";
BA_ "SignalLongName" SG_ 2151235584 VehSecStrgColLckPwd "Vehicle Security Steering Column Lock Password";
BA_ "VNSigAllNodes" SG_ 2151235584 VehSecStrgColLckPwd 1;
BA_ "GenSigSendType" SG_ 2151235584 VhSecNImmoIndRq 10;
BA_ "GenSigSendOnInit" SG_ 2151235584 VhSecNImmoIndRq 1;
BA_ "SignalType" SG_ 2151235584 VhSecNImmoIndRq "ENM";
BA_ "SignalLongName" SG_ 2151235584 VhSecNImmoIndRq "Vehicle Security Non Immobilizer Indication Request";
BA_ "VNSigAllNodes" SG_ 2151235584 VhSecNImmoIndRq 1;
BA_ "GenSigSendType" SG_ 2151235584 StrgColLckCmd 10;
BA_ "SignalType" SG_ 2151235584 StrgColLckCmd "ENM";
BA_ "SignalLongName" SG_ 2151235584 StrgColLckCmd "Steering Column Lock Command";
BA_ "VNSigAllNodes" SG_ 2151235584 StrgColLckCmd 1;
BA_ "GenSigSendType" SG_ 2151235584 DrIdDevLrnd 10;
BA_ "SignalType" SG_ 2151235584 DrIdDevLrnd "ENM";
BA_ "SignalLongName" SG_ 2151235584 DrIdDevLrnd "Driver Identification Device Learned";
BA_ "VNSigAllNodes" SG_ 2151235584 DrIdDevLrnd 1;
BA_ "GenSigSendType" SG_ 2151235584 IllDrIdDevDtctd 10;
BA_ "SignalType" SG_ 2151235584 IllDrIdDevDtctd "BLN";
BA_ "SignalLongName" SG_ 2151235584 IllDrIdDevDtctd "Illegitimate Driver Identification Device Detected";
BA_ "VNSigAllNodes" SG_ 2151235584 IllDrIdDevDtctd 1;
BA_ "GenSigSendType" SG_ 2151235584 EhnSrvEngImmStat 10;
BA_ "SignalType" SG_ 2151235584 EhnSrvEngImmStat "ENM";
BA_ "SignalLongName" SG_ 2151235584 EhnSrvEngImmStat "Enhanced Services Engine Immobilized Status";
BA_ "VNSigAllNodes" SG_ 2151235584 EhnSrvEngImmStat 1;
BA_ "GenSigSendType" SG_ 2151235584 ClmSysBkupFlrIndOn 10;
BA_ "SignalType" SG_ 2151235584 ClmSysBkupFlrIndOn "BLN";
BA_ "SignalLongName" SG_ 2151235584 ClmSysBkupFlrIndOn "Column System Backup Failure Indication On";
BA_ "VNSigAllNodes" SG_ 2151235584 ClmSysBkupFlrIndOn 1;
BA_ "GenSigSendType" SG_ 2151235584 VehStatStAtv 10;
BA_ "SignalType" SG_ 2151235584 VehStatStAtv "BLN";
BA_ "SignalLongName" SG_ 2151235584 VehStatStAtv "Vehicle Stationary Status Active";
BA_ "VNSigAllNodes" SG_ 2151235584 VehStatStAtv 1;
BA_ "GenSigDeltaValue" SG_ 2150809600 IDVS12_Axis2 1;
BA_ "GenSigSendType" SG_ 2150809600 IDVS12_Axis2 12;
BA_ "VNSigPrimaryTriggering" SG_ 2150809600 IDVS12_Axis2 1;
BA_ "SignalType" SG_ 2150809600 IDVS12_Axis2 "SNM";
BA_ "PacketOrder" SG_ 2150809600 IDVS12_Axis2 2;
BA_ "SignalLongName" SG_ 2150809600 IDVS12_Axis2 "Impact Delta Velocity Sample 12 : Axis 2";
BA_ "VNSigAllNodes" SG_ 2150809600 IDVS12_Axis2 1;
BA_ "GenSigDeltaValue" SG_ 2150809600 IDVS12_Axis1 1;
BA_ "GenSigSendType" SG_ 2150809600 IDVS12_Axis1 12;
BA_ "VNSigPrimaryTriggering" SG_ 2150809600 IDVS12_Axis1 1;
BA_ "SignalType" SG_ 2150809600 IDVS12_Axis1 "SNM";
BA_ "PacketOrder" SG_ 2150809600 IDVS12_Axis1 1;
BA_ "SignalLongName" SG_ 2150809600 IDVS12_Axis1 "Impact Delta Velocity Sample 12 : Axis 1";
BA_ "VNSigAllNodes" SG_ 2150809600 IDVS12_Axis1 1;
BA_ "GenSigDeltaValue" SG_ 2150809600 IDVS13_Axis2 1;
BA_ "GenSigSendType" SG_ 2150809600 IDVS13_Axis2 12;
BA_ "VNSigPrimaryTriggering" SG_ 2150809600 IDVS13_Axis2 1;
BA_ "SignalType" SG_ 2150809600 IDVS13_Axis2 "SNM";
BA_ "PacketOrder" SG_ 2150809600 IDVS13_Axis2 2;
BA_ "SignalLongName" SG_ 2150809600 IDVS13_Axis2 "Impact Delta Velocity Sample 13 : Axis 2";
BA_ "VNSigAllNodes" SG_ 2150809600 IDVS13_Axis2 1;
BA_ "GenSigDeltaValue" SG_ 2150809600 IDVS13_Axis1 1;
BA_ "GenSigSendType" SG_ 2150809600 IDVS13_Axis1 12;
BA_ "VNSigPrimaryTriggering" SG_ 2150809600 IDVS13_Axis1 1;
BA_ "SignalType" SG_ 2150809600 IDVS13_Axis1 "SNM";
BA_ "PacketOrder" SG_ 2150809600 IDVS13_Axis1 1;
BA_ "SignalLongName" SG_ 2150809600 IDVS13_Axis1 "Impact Delta Velocity Sample 13 : Axis 1";
BA_ "VNSigAllNodes" SG_ 2150809600 IDVS13_Axis1 1;
BA_ "GenSigDeltaValue" SG_ 2150809600 IDVS14_Axis2 1;
BA_ "GenSigSendType" SG_ 2150809600 IDVS14_Axis2 12;
BA_ "VNSigPrimaryTriggering" SG_ 2150809600 IDVS14_Axis2 1;
BA_ "SignalType" SG_ 2150809600 IDVS14_Axis2 "SNM";
BA_ "PacketOrder" SG_ 2150809600 IDVS14_Axis2 2;
BA_ "SignalLongName" SG_ 2150809600 IDVS14_Axis2 "Impact Delta Velocity Sample 14 : Axis 2";
BA_ "VNSigAllNodes" SG_ 2150809600 IDVS14_Axis2 1;
BA_ "GenSigDeltaValue" SG_ 2150809600 IDVS14_Axis1 1;
BA_ "GenSigSendType" SG_ 2150809600 IDVS14_Axis1 12;
BA_ "VNSigPrimaryTriggering" SG_ 2150809600 IDVS14_Axis1 1;
BA_ "SignalType" SG_ 2150809600 IDVS14_Axis1 "SNM";
BA_ "PacketOrder" SG_ 2150809600 IDVS14_Axis1 1;
BA_ "SignalLongName" SG_ 2150809600 IDVS14_Axis1 "Impact Delta Velocity Sample 14 : Axis 1";
BA_ "VNSigAllNodes" SG_ 2150809600 IDVS14_Axis1 1;
BA_ "GenSigDeltaValue" SG_ 2150809600 IDVS15_Axis2 1;
BA_ "GenSigSendType" SG_ 2150809600 IDVS15_Axis2 12;
BA_ "VNSigPrimaryTriggering" SG_ 2150809600 IDVS15_Axis2 1;
BA_ "SignalType" SG_ 2150809600 IDVS15_Axis2 "SNM";
BA_ "PacketOrder" SG_ 2150809600 IDVS15_Axis2 2;
BA_ "SignalLongName" SG_ 2150809600 IDVS15_Axis2 "Impact Delta Velocity Sample 15 : Axis 2";
BA_ "VNSigAllNodes" SG_ 2150809600 IDVS15_Axis2 1;
BA_ "GenSigDeltaValue" SG_ 2150809600 IDVS15_Axis1 1;
BA_ "GenSigSendType" SG_ 2150809600 IDVS15_Axis1 12;
BA_ "VNSigPrimaryTriggering" SG_ 2150809600 IDVS15_Axis1 1;
BA_ "SignalType" SG_ 2150809600 IDVS15_Axis1 "SNM";
BA_ "PacketOrder" SG_ 2150809600 IDVS15_Axis1 1;
BA_ "SignalLongName" SG_ 2150809600 IDVS15_Axis1 "Impact Delta Velocity Sample 15 : Axis 1";
BA_ "VNSigAllNodes" SG_ 2150809600 IDVS15_Axis1 1;
BA_ "GenSigDeltaValue" SG_ 2150793216 IDVS4_Axis2 1;
BA_ "GenSigSendType" SG_ 2150793216 IDVS4_Axis2 12;
BA_ "VNSigPrimaryTriggering" SG_ 2150793216 IDVS4_Axis2 1;
BA_ "SignalType" SG_ 2150793216 IDVS4_Axis2 "SNM";
BA_ "PacketOrder" SG_ 2150793216 IDVS4_Axis2 2;
BA_ "SignalLongName" SG_ 2150793216 IDVS4_Axis2 "Impact Delta Velocity Sample 4 : Axis 2";
BA_ "VNSigAllNodes" SG_ 2150793216 IDVS4_Axis2 1;
BA_ "GenSigDeltaValue" SG_ 2150793216 IDVS4_Axis1 1;
BA_ "GenSigSendType" SG_ 2150793216 IDVS4_Axis1 12;
BA_ "VNSigPrimaryTriggering" SG_ 2150793216 IDVS4_Axis1 1;
BA_ "SignalType" SG_ 2150793216 IDVS4_Axis1 "SNM";
BA_ "PacketOrder" SG_ 2150793216 IDVS4_Axis1 1;
BA_ "SignalLongName" SG_ 2150793216 IDVS4_Axis1 "Impact Delta Velocity Sample 4 : Axis 1";
BA_ "VNSigAllNodes" SG_ 2150793216 IDVS4_Axis1 1;
BA_ "GenSigDeltaValue" SG_ 2150793216 IDVS5_Axis2 1;
BA_ "GenSigSendType" SG_ 2150793216 IDVS5_Axis2 12;
BA_ "VNSigPrimaryTriggering" SG_ 2150793216 IDVS5_Axis2 1;
BA_ "SignalType" SG_ 2150793216 IDVS5_Axis2 "SNM";
BA_ "PacketOrder" SG_ 2150793216 IDVS5_Axis2 2;
BA_ "SignalLongName" SG_ 2150793216 IDVS5_Axis2 "Impact Delta Velocity Sample 5 : Axis 2";
BA_ "VNSigAllNodes" SG_ 2150793216 IDVS5_Axis2 1;
BA_ "GenSigDeltaValue" SG_ 2150793216 IDVS5_Axis1 1;
BA_ "GenSigSendType" SG_ 2150793216 IDVS5_Axis1 12;
BA_ "VNSigPrimaryTriggering" SG_ 2150793216 IDVS5_Axis1 1;
BA_ "SignalType" SG_ 2150793216 IDVS5_Axis1 "SNM";
BA_ "PacketOrder" SG_ 2150793216 IDVS5_Axis1 1;
BA_ "SignalLongName" SG_ 2150793216 IDVS5_Axis1 "Impact Delta Velocity Sample 5 : Axis 1";
BA_ "VNSigAllNodes" SG_ 2150793216 IDVS5_Axis1 1;
BA_ "GenSigDeltaValue" SG_ 2150793216 IDVS6_Axis2 1;
BA_ "GenSigSendType" SG_ 2150793216 IDVS6_Axis2 12;
BA_ "VNSigPrimaryTriggering" SG_ 2150793216 IDVS6_Axis2 1;
BA_ "SignalType" SG_ 2150793216 IDVS6_Axis2 "SNM";
BA_ "PacketOrder" SG_ 2150793216 IDVS6_Axis2 2;
BA_ "SignalLongName" SG_ 2150793216 IDVS6_Axis2 "Impact Delta Velocity Sample 6 : Axis 2";
BA_ "VNSigAllNodes" SG_ 2150793216 IDVS6_Axis2 1;
BA_ "GenSigDeltaValue" SG_ 2150793216 IDVS6_Axis1 1;
BA_ "GenSigSendType" SG_ 2150793216 IDVS6_Axis1 12;
BA_ "VNSigPrimaryTriggering" SG_ 2150793216 IDVS6_Axis1 1;
BA_ "SignalType" SG_ 2150793216 IDVS6_Axis1 "SNM";
BA_ "PacketOrder" SG_ 2150793216 IDVS6_Axis1 1;
BA_ "SignalLongName" SG_ 2150793216 IDVS6_Axis1 "Impact Delta Velocity Sample 6 : Axis 1";
BA_ "VNSigAllNodes" SG_ 2150793216 IDVS6_Axis1 1;
BA_ "GenSigDeltaValue" SG_ 2150793216 IDVS7_Axis2 1;
BA_ "GenSigSendType" SG_ 2150793216 IDVS7_Axis2 12;
BA_ "VNSigPrimaryTriggering" SG_ 2150793216 IDVS7_Axis2 1;
BA_ "SignalType" SG_ 2150793216 IDVS7_Axis2 "SNM";
BA_ "PacketOrder" SG_ 2150793216 IDVS7_Axis2 2;
BA_ "SignalLongName" SG_ 2150793216 IDVS7_Axis2 "Impact Delta Velocity Sample 7 : Axis 2";
BA_ "VNSigAllNodes" SG_ 2150793216 IDVS7_Axis2 1;
BA_ "GenSigDeltaValue" SG_ 2150793216 IDVS7_Axis1 1;
BA_ "GenSigSendType" SG_ 2150793216 IDVS7_Axis1 12;
BA_ "VNSigPrimaryTriggering" SG_ 2150793216 IDVS7_Axis1 1;
BA_ "SignalType" SG_ 2150793216 IDVS7_Axis1 "SNM";
BA_ "PacketOrder" SG_ 2150793216 IDVS7_Axis1 1;
BA_ "SignalLongName" SG_ 2150793216 IDVS7_Axis1 "Impact Delta Velocity Sample 7 : Axis 1";
BA_ "VNSigAllNodes" SG_ 2150793216 IDVS7_Axis1 1;
BA_ "GenSigDeltaValue" SG_ 2150801408 IDVS10_Axis2 1;
BA_ "GenSigSendType" SG_ 2150801408 IDVS10_Axis2 12;
BA_ "VNSigPrimaryTriggering" SG_ 2150801408 IDVS10_Axis2 1;
BA_ "SignalType" SG_ 2150801408 IDVS10_Axis2 "SNM";
BA_ "PacketOrder" SG_ 2150801408 IDVS10_Axis2 2;
BA_ "SignalLongName" SG_ 2150801408 IDVS10_Axis2 "Impact Delta Velocity Sample 10 : Axis 2";
BA_ "VNSigAllNodes" SG_ 2150801408 IDVS10_Axis2 1;
BA_ "GenSigDeltaValue" SG_ 2150801408 IDVS10_Axis1 1;
BA_ "GenSigSendType" SG_ 2150801408 IDVS10_Axis1 12;
BA_ "VNSigPrimaryTriggering" SG_ 2150801408 IDVS10_Axis1 1;
BA_ "SignalType" SG_ 2150801408 IDVS10_Axis1 "SNM";
BA_ "PacketOrder" SG_ 2150801408 IDVS10_Axis1 1;
BA_ "SignalLongName" SG_ 2150801408 IDVS10_Axis1 "Impact Delta Velocity Sample 10 : Axis 1";
BA_ "VNSigAllNodes" SG_ 2150801408 IDVS10_Axis1 1;
BA_ "GenSigDeltaValue" SG_ 2150801408 IDVS11_Axis2 1;
BA_ "GenSigSendType" SG_ 2150801408 IDVS11_Axis2 12;
BA_ "VNSigPrimaryTriggering" SG_ 2150801408 IDVS11_Axis2 1;
BA_ "SignalType" SG_ 2150801408 IDVS11_Axis2 "SNM";
BA_ "PacketOrder" SG_ 2150801408 IDVS11_Axis2 2;
BA_ "SignalLongName" SG_ 2150801408 IDVS11_Axis2 "Impact Delta Velocity Sample 11 : Axis 2";
BA_ "VNSigAllNodes" SG_ 2150801408 IDVS11_Axis2 1;
BA_ "GenSigDeltaValue" SG_ 2150801408 IDVS11_Axis1 1;
BA_ "GenSigSendType" SG_ 2150801408 IDVS11_Axis1 12;
BA_ "VNSigPrimaryTriggering" SG_ 2150801408 IDVS11_Axis1 1;
BA_ "SignalType" SG_ 2150801408 IDVS11_Axis1 "SNM";
BA_ "PacketOrder" SG_ 2150801408 IDVS11_Axis1 1;
BA_ "SignalLongName" SG_ 2150801408 IDVS11_Axis1 "Impact Delta Velocity Sample 11 : Axis 1";
BA_ "VNSigAllNodes" SG_ 2150801408 IDVS11_Axis1 1;
BA_ "GenSigDeltaValue" SG_ 2150801408 IDVS8_Axis2 1;
BA_ "GenSigSendType" SG_ 2150801408 IDVS8_Axis2 12;
BA_ "VNSigPrimaryTriggering" SG_ 2150801408 IDVS8_Axis2 1;
BA_ "SignalType" SG_ 2150801408 IDVS8_Axis2 "SNM";
BA_ "PacketOrder" SG_ 2150801408 IDVS8_Axis2 2;
BA_ "SignalLongName" SG_ 2150801408 IDVS8_Axis2 "Impact Delta Velocity Sample 8 : Axis 2";
BA_ "VNSigAllNodes" SG_ 2150801408 IDVS8_Axis2 1;
BA_ "GenSigDeltaValue" SG_ 2150801408 IDVS8_Axis1 1;
BA_ "GenSigSendType" SG_ 2150801408 IDVS8_Axis1 12;
BA_ "VNSigPrimaryTriggering" SG_ 2150801408 IDVS8_Axis1 1;
BA_ "SignalType" SG_ 2150801408 IDVS8_Axis1 "SNM";
BA_ "PacketOrder" SG_ 2150801408 IDVS8_Axis1 1;
BA_ "SignalLongName" SG_ 2150801408 IDVS8_Axis1 "Impact Delta Velocity Sample 8 : Axis 1";
BA_ "VNSigAllNodes" SG_ 2150801408 IDVS8_Axis1 1;
BA_ "GenSigDeltaValue" SG_ 2150801408 IDVS9_Axis2 1;
BA_ "GenSigSendType" SG_ 2150801408 IDVS9_Axis2 12;
BA_ "VNSigPrimaryTriggering" SG_ 2150801408 IDVS9_Axis2 1;
BA_ "SignalType" SG_ 2150801408 IDVS9_Axis2 "SNM";
BA_ "PacketOrder" SG_ 2150801408 IDVS9_Axis2 2;
BA_ "SignalLongName" SG_ 2150801408 IDVS9_Axis2 "Impact Delta Velocity Sample 9 : Axis 2";
BA_ "VNSigAllNodes" SG_ 2150801408 IDVS9_Axis2 1;
BA_ "GenSigDeltaValue" SG_ 2150801408 IDVS9_Axis1 1;
BA_ "GenSigSendType" SG_ 2150801408 IDVS9_Axis1 12;
BA_ "VNSigPrimaryTriggering" SG_ 2150801408 IDVS9_Axis1 1;
BA_ "SignalType" SG_ 2150801408 IDVS9_Axis1 "SNM";
BA_ "PacketOrder" SG_ 2150801408 IDVS9_Axis1 1;
BA_ "SignalLongName" SG_ 2150801408 IDVS9_Axis1 "Impact Delta Velocity Sample 9 : Axis 1";
BA_ "VNSigAllNodes" SG_ 2150801408 IDVS9_Axis1 1;
BA_ "GenSigDeltaValue" SG_ 2150785024 AirbgAccelOrien 1;
BA_ "GenSigSendType" SG_ 2150785024 AirbgAccelOrien 12;
BA_ "VNSigPrimaryTriggering" SG_ 2150785024 AirbgAccelOrien 1;
BA_ "SignalType" SG_ 2150785024 AirbgAccelOrien "UNM";
BA_ "SignalLongName" SG_ 2150785024 AirbgAccelOrien "Airbag Accelerometer Orientation";
BA_ "VNSigAllNodes" SG_ 2150785024 AirbgAccelOrien 1;
BA_ "GenSigDeltaValue" SG_ 2150785024 IDVS1_Axis2 1;
BA_ "GenSigSendType" SG_ 2150785024 IDVS1_Axis2 12;
BA_ "VNSigPrimaryTriggering" SG_ 2150785024 IDVS1_Axis2 1;
BA_ "SignalType" SG_ 2150785024 IDVS1_Axis2 "SNM";
BA_ "PacketOrder" SG_ 2150785024 IDVS1_Axis2 2;
BA_ "SignalLongName" SG_ 2150785024 IDVS1_Axis2 "Impact Delta Velocity Sample 1 : Axis 2";
BA_ "VNSigAllNodes" SG_ 2150785024 IDVS1_Axis2 1;
BA_ "GenSigDeltaValue" SG_ 2150785024 IDVS1_Axis1 1;
BA_ "GenSigSendType" SG_ 2150785024 IDVS1_Axis1 12;
BA_ "VNSigPrimaryTriggering" SG_ 2150785024 IDVS1_Axis1 1;
BA_ "SignalType" SG_ 2150785024 IDVS1_Axis1 "SNM";
BA_ "PacketOrder" SG_ 2150785024 IDVS1_Axis1 1;
BA_ "SignalLongName" SG_ 2150785024 IDVS1_Axis1 "Impact Delta Velocity Sample 1 : Axis 1";
BA_ "VNSigAllNodes" SG_ 2150785024 IDVS1_Axis1 1;
BA_ "GenSigDeltaValue" SG_ 2150785024 IDVS2_Axis2 1;
BA_ "GenSigSendType" SG_ 2150785024 IDVS2_Axis2 12;
BA_ "VNSigPrimaryTriggering" SG_ 2150785024 IDVS2_Axis2 1;
BA_ "SignalType" SG_ 2150785024 IDVS2_Axis2 "SNM";
BA_ "PacketOrder" SG_ 2150785024 IDVS2_Axis2 2;
BA_ "SignalLongName" SG_ 2150785024 IDVS2_Axis2 "Impact Delta Velocity Sample 2 : Axis 2";
BA_ "VNSigAllNodes" SG_ 2150785024 IDVS2_Axis2 1;
BA_ "GenSigDeltaValue" SG_ 2150785024 IDVS2_Axis1 1;
BA_ "GenSigSendType" SG_ 2150785024 IDVS2_Axis1 12;
BA_ "VNSigPrimaryTriggering" SG_ 2150785024 IDVS2_Axis1 1;
BA_ "SignalType" SG_ 2150785024 IDVS2_Axis1 "SNM";
BA_ "PacketOrder" SG_ 2150785024 IDVS2_Axis1 1;
BA_ "SignalLongName" SG_ 2150785024 IDVS2_Axis1 "Impact Delta Velocity Sample 2 : Axis 1";
BA_ "VNSigAllNodes" SG_ 2150785024 IDVS2_Axis1 1;
BA_ "GenSigDeltaValue" SG_ 2150785024 IDVS3_Axis2 1;
BA_ "GenSigSendType" SG_ 2150785024 IDVS3_Axis2 12;
BA_ "VNSigPrimaryTriggering" SG_ 2150785024 IDVS3_Axis2 1;
BA_ "SignalType" SG_ 2150785024 IDVS3_Axis2 "SNM";
BA_ "PacketOrder" SG_ 2150785024 IDVS3_Axis2 2;
BA_ "SignalLongName" SG_ 2150785024 IDVS3_Axis2 "Impact Delta Velocity Sample 3 : Axis 2";
BA_ "VNSigAllNodes" SG_ 2150785024 IDVS3_Axis2 1;
BA_ "GenSigDeltaValue" SG_ 2150785024 IDVS3_Axis1 1;
BA_ "GenSigSendType" SG_ 2150785024 IDVS3_Axis1 12;
BA_ "VNSigPrimaryTriggering" SG_ 2150785024 IDVS3_Axis1 1;
BA_ "SignalType" SG_ 2150785024 IDVS3_Axis1 "SNM";
BA_ "PacketOrder" SG_ 2150785024 IDVS3_Axis1 1;
BA_ "SignalLongName" SG_ 2150785024 IDVS3_Axis1 "Impact Delta Velocity Sample 3 : Axis 1";
BA_ "VNSigAllNodes" SG_ 2150785024 IDVS3_Axis1 1;
BA_ "GenSigDeltaValue" SG_ 2150785024 ImpDltVlcScal 1;
BA_ "GenSigSendType" SG_ 2150785024 ImpDltVlcScal 12;
BA_ "VNSigPrimaryTriggering" SG_ 2150785024 ImpDltVlcScal 1;
BA_ "SignalType" SG_ 2150785024 ImpDltVlcScal "UNM";
BA_ "SignalLongName" SG_ 2150785024 ImpDltVlcScal "Impact Delta Velocity Scaling";
BA_ "VNSigAllNodes" SG_ 2150785024 ImpDltVlcScal 1;
BA_ "GenSigSendType" SG_ 2151202816 AuxHtrAlwd 10;
BA_ "SignalType" SG_ 2151202816 AuxHtrAlwd "BLN";
BA_ "SignalLongName" SG_ 2151202816 AuxHtrAlwd "Auxiliary Heater Allowed";
BA_ "VNSigAllNodes" SG_ 2151202816 AuxHtrAlwd 1;
BA_ "GenSigSendType" SG_ 2151202816 IPSnsrTpCvrTempFltd 10;
BA_ "SignalType" SG_ 2151202816 IPSnsrTpCvrTempFltd "BLN";
BA_ "SignalLongName" SG_ 2151202816 IPSnsrTpCvrTempFltd "Instrument Panel Sensor Top Cover Temperature faulted";
BA_ "VNSigAllNodes" SG_ 2151202816 IPSnsrTpCvrTempFltd 1;
BA_ "GenSigDeltaValue" SG_ 2151202816 IPSnsrTpCvrTemp 1;
BA_ "GenSigSendType" SG_ 2151202816 IPSnsrTpCvrTemp 12;
BA_ "SignalType" SG_ 2151202816 IPSnsrTpCvrTemp "UNM";
BA_ "SignalLongName" SG_ 2151202816 IPSnsrTpCvrTemp "Instrument Panel Sensor Top Cover Temperature";
BA_ "VNSigAllNodes" SG_ 2151202816 IPSnsrTpCvrTemp 1;
BA_ "GenSigDeltaValue" SG_ 2151202816 IPSnsrSolrElvtnAngl 1;
BA_ "GenSigSendType" SG_ 2151202816 IPSnsrSolrElvtnAngl 12;
BA_ "SignalType" SG_ 2151202816 IPSnsrSolrElvtnAngl "UNM";
BA_ "SignalLongName" SG_ 2151202816 IPSnsrSolrElvtnAngl "Instrument Panel Sensor Solar Elevation Angle";
BA_ "VNSigAllNodes" SG_ 2151202816 IPSnsrSolrElvtnAngl 1;
BA_ "GenSigDeltaValue" SG_ 2151202816 IPSnsrSolrAzmthAngl 1;
BA_ "GenSigSendType" SG_ 2151202816 IPSnsrSolrAzmthAngl 12;
BA_ "SignalType" SG_ 2151202816 IPSnsrSolrAzmthAngl "UNM";
BA_ "SignalLongName" SG_ 2151202816 IPSnsrSolrAzmthAngl "Instrument Panel Sensor Solar Azimuth Angle";
BA_ "VNSigAllNodes" SG_ 2151202816 IPSnsrSolrAzmthAngl 1;
BA_ "GenSigSendType" SG_ 2151202816 IPSnsrSolrAnglFltd 10;
BA_ "SignalType" SG_ 2151202816 IPSnsrSolrAnglFltd "BLN";
BA_ "SignalLongName" SG_ 2151202816 IPSnsrSolrAnglFltd "Instrument Panel Sensor Solar Angle Faulted";
BA_ "VNSigAllNodes" SG_ 2151202816 IPSnsrSolrAnglFltd 1;
BA_ "GenSigSendType" SG_ 2151202816 IPSnsrRwSolrIntFltd 10;
BA_ "SignalType" SG_ 2151202816 IPSnsrRwSolrIntFltd "BLN";
BA_ "SignalLongName" SG_ 2151202816 IPSnsrRwSolrIntFltd "Instrument Panel Sensor Raw Solar Intensity Faulted";
BA_ "VNSigAllNodes" SG_ 2151202816 IPSnsrRwSolrIntFltd 1;
BA_ "GenSigDeltaValue" SG_ 2151202816 IPSnsrRwSolrInt 1;
BA_ "GenSigSendType" SG_ 2151202816 IPSnsrRwSolrInt 12;
BA_ "SignalType" SG_ 2151202816 IPSnsrRwSolrInt "UNM";
BA_ "SignalLongName" SG_ 2151202816 IPSnsrRwSolrInt "Instrument Panel Sensor Raw Solar Intensity";
BA_ "VNSigAllNodes" SG_ 2151202816 IPSnsrRwSolrInt 1;
BA_ "GenSigSendType" SG_ 2151202816 ILSSCommErr 10;
BA_ "SignalType" SG_ 2151202816 ILSSCommErr "ENM";
BA_ "SignalLongName" SG_ 2151202816 ILSSCommErr "ILSS Communication Error";
BA_ "VNSigAllNodes" SG_ 2151202816 ILSSCommErr 1;
BA_ "GenSigSendType" SG_ 2151202816 RrWndDfgSwAtv 10;
BA_ "SignalType" SG_ 2151202816 RrWndDfgSwAtv "BLN";
BA_ "SignalLongName" SG_ 2151202816 RrWndDfgSwAtv "Rear Window Defog Switch Active";
BA_ "VNSigAllNodes" SG_ 2151202816 RrWndDfgSwAtv 1;
BA_ "GenSigSendType" SG_ 2151202816 RrWndDfgInhRq 10;
BA_ "GenSigSendOnInit" SG_ 2151202816 RrWndDfgInhRq 2;
BA_ "SignalType" SG_ 2151202816 RrWndDfgInhRq "ENM";
BA_ "SignalLongName" SG_ 2151202816 RrWndDfgInhRq "Rear Window Defog Inhibit Request";
BA_ "VNSigAllNodes" SG_ 2151202816 RrWndDfgInhRq 1;
BA_ "GenSigSendType" SG_ 2150825984 PdstIntdProtSysDplyd 10;
BA_ "SignalType" SG_ 2150825984 PdstIntdProtSysDplyd "BLN";
BA_ "SignalLongName" SG_ 2150825984 PdstIntdProtSysDplyd "Pedestrian Integrated Protection System Deployed";
BA_ "VNSigAllNodes" SG_ 2150825984 PdstIntdProtSysDplyd 1;
BA_ "GenSigSendType" SG_ 2150825984 PdstIntdProtSysDsbld 10;
BA_ "SignalType" SG_ 2150825984 PdstIntdProtSysDsbld "BLN";
BA_ "SignalLongName" SG_ 2150825984 PdstIntdProtSysDsbld "Pedestrian Integrated Protection System Disabled";
BA_ "VNSigAllNodes" SG_ 2150825984 PdstIntdProtSysDsbld 1;
BA_ "GenSigSendType" SG_ 2150825984 SrvIntdPdstProtSysIO 10;
BA_ "SignalType" SG_ 2150825984 SrvIntdPdstProtSysIO "BLN";
BA_ "SignalLongName" SG_ 2150825984 SrvIntdPdstProtSysIO "Service Integrated Pedestrian Protection System Indication On";
BA_ "VNSigAllNodes" SG_ 2150825984 SrvIntdPdstProtSysIO 1;
BA_ "GenSigSendType" SG_ 2150825984 FstnThrdRwRtPsStbtInR 10;
BA_ "SignalType" SG_ 2150825984 FstnThrdRwRtPsStbtInR "ENM";
BA_ "SignalLongName" SG_ 2150825984 FstnThrdRwRtPsStbtInR "Fasten Third Row Right Passenger Seatbelt Indication Request";
BA_ "VNSigAllNodes" SG_ 2150825984 FstnThrdRwRtPsStbtInR 1;
BA_ "GenSigSendType" SG_ 2150825984 FstnThrdRwLtPsStbtInR 10;
BA_ "SignalType" SG_ 2150825984 FstnThrdRwLtPsStbtInR "ENM";
BA_ "SignalLongName" SG_ 2150825984 FstnThrdRwLtPsStbtInR "Fasten Third Row Left Passenger Seatbelt Indication Request";
BA_ "VNSigAllNodes" SG_ 2150825984 FstnThrdRwLtPsStbtInR 1;
BA_ "GenSigSendType" SG_ 2150825984 FstnThrdRwCtPsStbtInR 10;
BA_ "SignalType" SG_ 2150825984 FstnThrdRwCtPsStbtInR "ENM";
BA_ "SignalLongName" SG_ 2150825984 FstnThrdRwCtPsStbtInR "Fasten Third Row Center Passenger Seatbelt Indication Request";
BA_ "VNSigAllNodes" SG_ 2150825984 FstnThrdRwCtPsStbtInR 1;
BA_ "GenSigSendType" SG_ 2150825984 FPSIC_IndPer 10;
BA_ "GenSigSendOnInit" SG_ 2150825984 FPSIC_IndPer 1;
BA_ "GenSigStartValue" SG_ 2150825984 FPSIC_IndPer 3;
BA_ "SignalType" SG_ 2150825984 FPSIC_IndPer "ENM";
BA_ "PacketOrder" SG_ 2150825984 FPSIC_IndPer 3;
BA_ "SignalLongName" SG_ 2150825984 FPSIC_IndPer "Fasten Passenger Seatbelt Indication Control : Indication Period";
BA_ "VNSigAllNodes" SG_ 2150825984 FPSIC_IndPer 1;
BA_ "GenSigSendType" SG_ 2150825984 FPSIC_IO 10;
BA_ "GenSigSendOnInit" SG_ 2150825984 FPSIC_IO 1;
BA_ "SignalType" SG_ 2150825984 FPSIC_IO "BLN";
BA_ "PacketOrder" SG_ 2150825984 FPSIC_IO 1;
BA_ "SignalLongName" SG_ 2150825984 FPSIC_IO "Fasten Passenger Seatbelt Indication Control : Indication On";
BA_ "VNSigAllNodes" SG_ 2150825984 FPSIC_IO 1;
BA_ "GenSigDeltaValue" SG_ 2150825984 FPSIC_IndDtCyc 1;
BA_ "GenSigSendType" SG_ 2150825984 FPSIC_IndDtCyc 12;
BA_ "GenSigSendOnInit" SG_ 2150825984 FPSIC_IndDtCyc 1;
BA_ "GenSigStartValue" SG_ 2150825984 FPSIC_IndDtCyc 7;
BA_ "SignalType" SG_ 2150825984 FPSIC_IndDtCyc "UNM";
BA_ "PacketOrder" SG_ 2150825984 FPSIC_IndDtCyc 2;
BA_ "SignalLongName" SG_ 2150825984 FPSIC_IndDtCyc "Fasten Passenger Seatbelt Indication Control : Indication Duty Cycle";
BA_ "VNSigAllNodes" SG_ 2150825984 FPSIC_IndDtCyc 1;
BA_ "GenSigSendType" SG_ 2150825984 FDSIC_IndPer 10;
BA_ "GenSigSendOnInit" SG_ 2150825984 FDSIC_IndPer 1;
BA_ "GenSigStartValue" SG_ 2150825984 FDSIC_IndPer 3;
BA_ "SignalType" SG_ 2150825984 FDSIC_IndPer "ENM";
BA_ "PacketOrder" SG_ 2150825984 FDSIC_IndPer 3;
BA_ "SignalLongName" SG_ 2150825984 FDSIC_IndPer "Fasten Driver Seatbelt Indication Control : Indication Period";
BA_ "VNSigAllNodes" SG_ 2150825984 FDSIC_IndPer 1;
BA_ "GenSigSendType" SG_ 2150825984 FDSIC_IO 10;
BA_ "GenSigSendOnInit" SG_ 2150825984 FDSIC_IO 1;
BA_ "SignalType" SG_ 2150825984 FDSIC_IO "BLN";
BA_ "PacketOrder" SG_ 2150825984 FDSIC_IO 1;
BA_ "SignalLongName" SG_ 2150825984 FDSIC_IO "Fasten Driver Seatbelt Indication Control : Indication On";
BA_ "VNSigAllNodes" SG_ 2150825984 FDSIC_IO 1;
BA_ "GenSigDeltaValue" SG_ 2150825984 FDSIC_IndDC 1;
BA_ "GenSigSendType" SG_ 2150825984 FDSIC_IndDC 12;
BA_ "GenSigSendOnInit" SG_ 2150825984 FDSIC_IndDC 1;
BA_ "GenSigStartValue" SG_ 2150825984 FDSIC_IndDC 7;
BA_ "SignalType" SG_ 2150825984 FDSIC_IndDC "UNM";
BA_ "PacketOrder" SG_ 2150825984 FDSIC_IndDC 2;
BA_ "SignalLongName" SG_ 2150825984 FDSIC_IndDC "Fasten Driver Seatbelt Indication Control : Indication Duty Cycle";
BA_ "VNSigAllNodes" SG_ 2150825984 FDSIC_IndDC 1;
BA_ "GenSigSendType" SG_ 2150825984 AirbgFldIO 10;
BA_ "GenSigSendOnInit" SG_ 2150825984 AirbgFldIO 1;
BA_ "SignalType" SG_ 2150825984 AirbgFldIO "BLN";
BA_ "SignalLongName" SG_ 2150825984 AirbgFldIO "Airbag Failed Indication On";
BA_ "VNSigAllNodes" SG_ 2150825984 AirbgFldIO 1;
BA_ "GenSigSendType" SG_ 2150825984 SndRwStbltRdIndMd 10;
BA_ "SignalType" SG_ 2150825984 SndRwStbltRdIndMd "ENM";
BA_ "SignalLongName" SG_ 2150825984 SndRwStbltRdIndMd "Second Row Seatbelt Reminder Indication Mode";
BA_ "VNSigAllNodes" SG_ 2150825984 SndRwStbltRdIndMd 1;
BA_ "GenSigSendType" SG_ 2150825984 AirbgICIndPer 10;
BA_ "VNSigPrimaryTriggering" SG_ 2150825984 AirbgICIndPer 1;
BA_ "SignalType" SG_ 2150825984 AirbgICIndPer "ENM";
BA_ "PacketOrder" SG_ 2150825984 AirbgICIndPer 3;
BA_ "SignalLongName" SG_ 2150825984 AirbgICIndPer "Airbag Indication Control : Indication Period";
BA_ "VNSigAllNodes" SG_ 2150825984 AirbgICIndPer 1;
BA_ "GenSigDeltaValue" SG_ 2150825984 AirbgICDutCyc 1;
BA_ "GenSigSendType" SG_ 2150825984 AirbgICDutCyc 12;
BA_ "VNSigPrimaryTriggering" SG_ 2150825984 AirbgICDutCyc 1;
BA_ "SignalType" SG_ 2150825984 AirbgICDutCyc "UNM";
BA_ "PacketOrder" SG_ 2150825984 AirbgICDutCyc 2;
BA_ "SignalLongName" SG_ 2150825984 AirbgICDutCyc "Airbag Indication Control : Indication Duty Cycle";
BA_ "VNSigAllNodes" SG_ 2150825984 AirbgICDutCyc 1;
BA_ "GenSigSendType" SG_ 2150825984 AirbgICIO 10;
BA_ "VNSigPrimaryTriggering" SG_ 2150825984 AirbgICIO 1;
BA_ "SignalType" SG_ 2150825984 AirbgICIO "BLN";
BA_ "PacketOrder" SG_ 2150825984 AirbgICIO 1;
BA_ "SignalLongName" SG_ 2150825984 AirbgICIO "Airbag Indication Control : Indication On";
BA_ "VNSigAllNodes" SG_ 2150825984 AirbgICIO 1;
BA_ "GenSigSendType" SG_ 2150825984 FstnSndRwRtPsStbtInR 10;
BA_ "SignalType" SG_ 2150825984 FstnSndRwRtPsStbtInR "ENM";
BA_ "SignalLongName" SG_ 2150825984 FstnSndRwRtPsStbtInR "Fasten Second Row Right Passenger Seatbelt Indication Request";
BA_ "VNSigAllNodes" SG_ 2150825984 FstnSndRwRtPsStbtInR 1;
BA_ "GenSigSendType" SG_ 2150825984 FstnSndRwLtPsStbtInR 10;
BA_ "SignalType" SG_ 2150825984 FstnSndRwLtPsStbtInR "ENM";
BA_ "SignalLongName" SG_ 2150825984 FstnSndRwLtPsStbtInR "Fasten Second Row Left Passenger Seatbelt Indication Request";
BA_ "VNSigAllNodes" SG_ 2150825984 FstnSndRwLtPsStbtInR 1;
BA_ "GenSigSendType" SG_ 2150825984 FstnSndRwCtPsStbtInR 10;
BA_ "SignalType" SG_ 2150825984 FstnSndRwCtPsStbtInR "ENM";
BA_ "SignalLongName" SG_ 2150825984 FstnSndRwCtPsStbtInR "Fasten Second Row Center Passenger Seatbelt Indication Request";
BA_ "VNSigAllNodes" SG_ 2150825984 FstnSndRwCtPsStbtInR 1;
BA_ "GenSigSendType" SG_ 2150825984 FsnDrStbAuxIR 10;
BA_ "GenSigSendOnInit" SG_ 2150825984 FsnDrStbAuxIR 1;
BA_ "SignalType" SG_ 2150825984 FsnDrStbAuxIR "ENM";
BA_ "SignalLongName" SG_ 2150825984 FsnDrStbAuxIR "Fasten Driver Seatbelt Auxiliary Indication Request";
BA_ "VNSigAllNodes" SG_ 2150825984 FsnDrStbAuxIR 1;
BA_ "GenSigSendType" SG_ 2150825984 FsnPsStbAuxIR 10;
BA_ "GenSigSendOnInit" SG_ 2150825984 FsnPsStbAuxIR 1;
BA_ "SignalType" SG_ 2150825984 FsnPsStbAuxIR "ENM";
BA_ "SignalLongName" SG_ 2150825984 FsnPsStbAuxIR "Fasten Passenger Seatbelt Auxiliary Indication Request";
BA_ "VNSigAllNodes" SG_ 2150825984 FsnPsStbAuxIR 1;
BA_ "GenSigSendType" SG_ 2151759872 RrClsRelRq 10;
BA_ "SignalType" SG_ 2151759872 RrClsRelRq "ENM";
BA_ "SignalLongName" SG_ 2151759872 RrClsRelRq "Rear Closure Release Request";
BA_ "VNSigAllNodes" SG_ 2151759872 RrClsRelRq 1;
BA_ "GenSigSendType" SG_ 2151759872 CLRAF_UnandRsv3 10;
BA_ "SignalType" SG_ 2151759872 CLRAF_UnandRsv3 "BLN";
BA_ "PacketOrder" SG_ 2151759872 CLRAF_UnandRsv3 11;
BA_ "SignalLongName" SG_ 2151759872 CLRAF_UnandRsv3 "Central Locking Request with Extended Activating Functions : Unused and Reserved 3";
BA_ "VNSigAllNodes" SG_ 2151759872 CLRAF_UnandRsv3 1;
BA_ "GenSigSendType" SG_ 2151759872 CLRAF_UnandRsv2 10;
BA_ "SignalType" SG_ 2151759872 CLRAF_UnandRsv2 "BLN";
BA_ "PacketOrder" SG_ 2151759872 CLRAF_UnandRsv2 10;
BA_ "SignalLongName" SG_ 2151759872 CLRAF_UnandRsv2 "Central Locking Request with Extended Activating Functions : Unused and Reserved 2";
BA_ "VNSigAllNodes" SG_ 2151759872 CLRAF_UnandRsv2 1;
BA_ "GenSigSendType" SG_ 2151759872 CLRAF_UnandRsv1 10;
BA_ "SignalType" SG_ 2151759872 CLRAF_UnandRsv1 "BLN";
BA_ "PacketOrder" SG_ 2151759872 CLRAF_UnandRsv1 9;
BA_ "SignalLongName" SG_ 2151759872 CLRAF_UnandRsv1 "Central Locking Request with Extended Activating Functions : Unused and Reserved 1";
BA_ "VNSigAllNodes" SG_ 2151759872 CLRAF_UnandRsv1 1;
BA_ "GenSigSendType" SG_ 2151759872 CLRAF_Unl_Lk 10;
BA_ "SignalType" SG_ 2151759872 CLRAF_Unl_Lk "ENM";
BA_ "PacketOrder" SG_ 2151759872 CLRAF_Unl_Lk 1;
BA_ "SignalLongName" SG_ 2151759872 CLRAF_Unl_Lk "Central Locking Request with Extended Activating Functions : Unlock/Lock";
BA_ "VNSigAllNodes" SG_ 2151759872 CLRAF_Unl_Lk 1;
BA_ "GenSigSendType" SG_ 2151759872 CLRAF_RRD 10;
BA_ "SignalType" SG_ 2151759872 CLRAF_RRD "BLN";
BA_ "PacketOrder" SG_ 2151759872 CLRAF_RRD 4;
BA_ "SignalLongName" SG_ 2151759872 CLRAF_RRD "Central Locking Request with Extended Activating Functions : Rear Right Door";
BA_ "VNSigAllNodes" SG_ 2151759872 CLRAF_RRD 1;
BA_ "GenSigSendType" SG_ 2151759872 CLRAF_RLD 10;
BA_ "SignalType" SG_ 2151759872 CLRAF_RLD "BLN";
BA_ "PacketOrder" SG_ 2151759872 CLRAF_RLD 5;
BA_ "SignalLongName" SG_ 2151759872 CLRAF_RLD "Central Locking Request with Extended Activating Functions : Rear Left Door";
BA_ "VNSigAllNodes" SG_ 2151759872 CLRAF_RLD 1;
BA_ "GenSigSendType" SG_ 2151759872 CLRAF_RrCls 10;
BA_ "SignalType" SG_ 2151759872 CLRAF_RrCls "BLN";
BA_ "PacketOrder" SG_ 2151759872 CLRAF_RrCls 7;
BA_ "SignalLongName" SG_ 2151759872 CLRAF_RrCls "Central Locking Request with Extended Activating Functions : Rear Closure";
BA_ "VNSigAllNodes" SG_ 2151759872 CLRAF_RrCls 1;
BA_ "GenSigSendType" SG_ 2151759872 CLRAF_PD 10;
BA_ "SignalType" SG_ 2151759872 CLRAF_PD "BLN";
BA_ "PacketOrder" SG_ 2151759872 CLRAF_PD 3;
BA_ "SignalLongName" SG_ 2151759872 CLRAF_PD "Central Locking Request with Extended Activating Functions : Passenger Door";
BA_ "VNSigAllNodes" SG_ 2151759872 CLRAF_PD 1;
BA_ "GenSigSendType" SG_ 2151759872 CLRAF_Hd 10;
BA_ "SignalType" SG_ 2151759872 CLRAF_Hd "BLN";
BA_ "PacketOrder" SG_ 2151759872 CLRAF_Hd 6;
BA_ "SignalLongName" SG_ 2151759872 CLRAF_Hd "Central Locking Request with Extended Activating Functions : Hood";
BA_ "VNSigAllNodes" SG_ 2151759872 CLRAF_Hd 1;
BA_ "GenSigSendType" SG_ 2151759872 CLRAF_FuelD 10;
BA_ "SignalType" SG_ 2151759872 CLRAF_FuelD "BLN";
BA_ "PacketOrder" SG_ 2151759872 CLRAF_FuelD 8;
BA_ "SignalLongName" SG_ 2151759872 CLRAF_FuelD "Central Locking Request with Extended Activating Functions : Fuel Door";
BA_ "VNSigAllNodes" SG_ 2151759872 CLRAF_FuelD 1;
BA_ "GenSigSendType" SG_ 2151759872 CLRAF_DD 10;
BA_ "SignalType" SG_ 2151759872 CLRAF_DD "BLN";
BA_ "PacketOrder" SG_ 2151759872 CLRAF_DD 2;
BA_ "SignalLongName" SG_ 2151759872 CLRAF_DD "Central Locking Request with Extended Activating Functions : Driver Door";
BA_ "VNSigAllNodes" SG_ 2151759872 CLRAF_DD 1;
BA_ "GenSigSendType" SG_ 2151759872 CLRAF_ActFunc 10;
BA_ "SignalType" SG_ 2151759872 CLRAF_ActFunc "ENM";
BA_ "PacketOrder" SG_ 2151759872 CLRAF_ActFunc 12;
BA_ "SignalLongName" SG_ 2151759872 CLRAF_ActFunc "Central Locking Request with Extended Activating Functions : Activating Function";
BA_ "VNSigAllNodes" SG_ 2151759872 CLRAF_ActFunc 1;
BA_ "GenSigSendType" SG_ 2149974016 IntrSnsDisbld 10;
BA_ "SignalType" SG_ 2149974016 IntrSnsDisbld "BLN";
BA_ "SignalLongName" SG_ 2149974016 IntrSnsDisbld "Intrusion Sensing Disabled";
BA_ "VNSigAllNodes" SG_ 2149974016 IntrSnsDisbld 1;
BA_ "GenSigSendType" SG_ 2149974016 AlrmStat 10;
BA_ "GenSigSendOnInit" SG_ 2149974016 AlrmStat 2;
BA_ "SignalType" SG_ 2149974016 AlrmStat "ENM";
BA_ "SignalLongName" SG_ 2149974016 AlrmStat "Alarm Status";
BA_ "VNSigAllNodes" SG_ 2149974016 AlrmStat 1;
BA_ "GenSigSendType" SG_ 2149974016 AlrmTrggrdBattRcnctd 10;
BA_ "SignalType" SG_ 2149974016 AlrmTrggrdBattRcnctd "BLN";
BA_ "SignalLongName" SG_ 2149974016 AlrmTrggrdBattRcnctd "Alarm Triggered Battery Reconnected";
BA_ "VNSigAllNodes" SG_ 2149974016 AlrmTrggrdBattRcnctd 1;
BA_ "GenSigSendType" SG_ 2149974016 AlrmTrgDrvDr 10;
BA_ "SignalType" SG_ 2149974016 AlrmTrgDrvDr "BLN";
BA_ "SignalLongName" SG_ 2149974016 AlrmTrgDrvDr "Alarm Triggered Driver Door Ajar";
BA_ "VNSigAllNodes" SG_ 2149974016 AlrmTrgDrvDr 1;
BA_ "GenSigSendType" SG_ 2149974016 AlrmTrgGlsBrkSns 10;
BA_ "SignalType" SG_ 2149974016 AlrmTrgGlsBrkSns "BLN";
BA_ "SignalLongName" SG_ 2149974016 AlrmTrgGlsBrkSns "Alarm Triggered Glass Breakage Sensor";
BA_ "VNSigAllNodes" SG_ 2149974016 AlrmTrgGlsBrkSns 1;
BA_ "GenSigSendType" SG_ 2149974016 AlrmTrgHd 10;
BA_ "SignalType" SG_ 2149974016 AlrmTrgHd "BLN";
BA_ "SignalLongName" SG_ 2149974016 AlrmTrgHd "Alarm Triggered Hood Ajar";
BA_ "VNSigAllNodes" SG_ 2149974016 AlrmTrgHd 1;
BA_ "GenSigSendType" SG_ 2149974016 AlrmTrgdIO 10;
BA_ "SignalType" SG_ 2149974016 AlrmTrgdIO "BLN";
BA_ "SignalLongName" SG_ 2149974016 AlrmTrgdIO "Alarm Triggered Indication On";
BA_ "VNSigAllNodes" SG_ 2149974016 AlrmTrgdIO 1;
BA_ "GenSigSendType" SG_ 2149974016 AlrmTrgIntMvmntSns 10;
BA_ "SignalType" SG_ 2149974016 AlrmTrgIntMvmntSns "BLN";
BA_ "SignalLongName" SG_ 2149974016 AlrmTrgIntMvmntSns "Alarm Triggered Interior Movement Sensor";
BA_ "VNSigAllNodes" SG_ 2149974016 AlrmTrgIntMvmntSns 1;
BA_ "GenSigSendType" SG_ 2149974016 AlrmTrgNonOffPM 10;
BA_ "SignalType" SG_ 2149974016 AlrmTrgNonOffPM "BLN";
BA_ "SignalLongName" SG_ 2149974016 AlrmTrgNonOffPM "Alarm Triggered Non-Off Power Mode";
BA_ "VNSigAllNodes" SG_ 2149974016 AlrmTrgNonOffPM 1;
BA_ "GenSigSendType" SG_ 2149974016 AlrmTrgPsngDr 10;
BA_ "SignalType" SG_ 2149974016 AlrmTrgPsngDr "BLN";
BA_ "SignalLongName" SG_ 2149974016 AlrmTrgPsngDr "Alarm Triggered Passenger Door Ajar";
BA_ "VNSigAllNodes" SG_ 2149974016 AlrmTrgPsngDr 1;
BA_ "GenSigSendType" SG_ 2149974016 AlrmTrgRrLftDr 10;
BA_ "SignalType" SG_ 2149974016 AlrmTrgRrLftDr "BLN";
BA_ "SignalLongName" SG_ 2149974016 AlrmTrgRrLftDr "Alarm Triggered Rear Left Door Ajar";
BA_ "VNSigAllNodes" SG_ 2149974016 AlrmTrgRrLftDr 1;
BA_ "GenSigSendType" SG_ 2149974016 AlrmTrgRrRtDr 10;
BA_ "SignalType" SG_ 2149974016 AlrmTrgRrRtDr "BLN";
BA_ "SignalLongName" SG_ 2149974016 AlrmTrgRrRtDr "Alarm Triggered Rear Right Door Ajar";
BA_ "VNSigAllNodes" SG_ 2149974016 AlrmTrgRrRtDr 1;
BA_ "GenSigSendType" SG_ 2149974016 AlrmTrgTltSns 10;
BA_ "SignalType" SG_ 2149974016 AlrmTrgTltSns "BLN";
BA_ "SignalLongName" SG_ 2149974016 AlrmTrgTltSns "Alarm Triggered Tilt Sensor";
BA_ "VNSigAllNodes" SG_ 2149974016 AlrmTrgTltSns 1;
BA_ "GenSigSendType" SG_ 2149974016 AlrmTrgTrnk 10;
BA_ "SignalType" SG_ 2149974016 AlrmTrgTrnk "BLN";
BA_ "SignalLongName" SG_ 2149974016 AlrmTrgTrnk "Alarm Triggered Trunk Ajar";
BA_ "VNSigAllNodes" SG_ 2149974016 AlrmTrgTrnk 1;
BA_ "GenSigSendType" SG_ 2149974016 SrvAlrmSysIO 10;
BA_ "SignalType" SG_ 2149974016 SrvAlrmSysIO "BLN";
BA_ "SignalLongName" SG_ 2149974016 SrvAlrmSysIO "Service Alarm System Indication On";
BA_ "VNSigAllNodes" SG_ 2149974016 SrvAlrmSysIO 1;
BA_ "GenSigSendType" SG_ 2149974016 AlrmTrigMidClsr 10;
BA_ "SignalType" SG_ 2149974016 AlrmTrigMidClsr "BLN";
BA_ "SignalLongName" SG_ 2149974016 AlrmTrigMidClsr "Alarm Triggered Mid Closure";
BA_ "VNSigAllNodes" SG_ 2149974016 AlrmTrigMidClsr 1;
BA_ "GenSigSendType" SG_ 2149974016 AlrmTrigTonn 10;
BA_ "SignalType" SG_ 2149974016 AlrmTrigTonn "BLN";
BA_ "SignalLongName" SG_ 2149974016 AlrmTrigTonn "Alarm Triggered Tonneau";
BA_ "VNSigAllNodes" SG_ 2149974016 AlrmTrigTonn 1;
BA_ "GenSigSendType" SG_ 2151907328 StrgWhlUnit1SwStat 10;
BA_ "VNSigInfotainment" SG_ 2151907328 StrgWhlUnit1SwStat 1;
BA_ "SignalType" SG_ 2151907328 StrgWhlUnit1SwStat "ENM";
BA_ "SignalLongName" SG_ 2151907328 StrgWhlUnit1SwStat "Steering Wheel Unit #1 Switch Status";
BA_ "VNSigAllNodes" SG_ 2151907328 StrgWhlUnit1SwStat 1;
BA_ "GenSigSendType" SG_ 2151907328 StrgWhlUnit2SwStat 10;
BA_ "VNSigInfotainment" SG_ 2151907328 StrgWhlUnit2SwStat 1;
BA_ "SignalType" SG_ 2151907328 StrgWhlUnit2SwStat "ENM";
BA_ "SignalLongName" SG_ 2151907328 StrgWhlUnit2SwStat "Steering Wheel Unit #2 Switch Status";
BA_ "VNSigAllNodes" SG_ 2151907328 StrgWhlUnit2SwStat 1;
BA_ "VNSigPrimaryTriggering" SG_ 1579 VectraSpcNWMgtD 1;
BA_ "VNSigRemoteDiagnostics" SG_ 1579 VectraSpcNWMgtD 1;
BA_ "VNSigInfotainment" SG_ 1579 VectraSpcNWMgtD 1;
BA_ "VNSigParkedVehicle" SG_ 1579 VectraSpcNWMgtD 1;
BA_ "VNSigIntermediate" SG_ 1579 VectraSpcNWMgtD 1;
BA_ "VNSigUnused_4" SG_ 1579 VectraSpcNWMgtD 1;
BA_ "SignalType" SG_ 1579 VectraSpcNWMgtD "UNM";
BA_ "SignalLongName" SG_ 1579 VectraSpcNWMgtD "Vectra Specific Network Management Data";
BA_ "VNSigDiagnostic" SG_ 1579 VectraSpcNWMgtD 1;
BA_ "VNSigAllNodes" SG_ 1579 VectraSpcNWMgtD 1;
BA_ "VNSigPrimaryTriggering" SG_ 1599 VectraSpcNWMgtD 1;
BA_ "VNSigRemoteDiagnostics" SG_ 1599 VectraSpcNWMgtD 1;
BA_ "VNSigInfotainment" SG_ 1599 VectraSpcNWMgtD 1;
BA_ "VNSigParkedVehicle" SG_ 1599 VectraSpcNWMgtD 1;
BA_ "VNSigIntermediate" SG_ 1599 VectraSpcNWMgtD 1;
BA_ "VNSigUnused_4" SG_ 1599 VectraSpcNWMgtD 1;
BA_ "SignalType" SG_ 1599 VectraSpcNWMgtD "UNM";
BA_ "SignalLongName" SG_ 1599 VectraSpcNWMgtD "Vectra Specific Network Management Data";
BA_ "VNSigDiagnostic" SG_ 1599 VectraSpcNWMgtD 1;
BA_ "VNSigAllNodes" SG_ 1599 VectraSpcNWMgtD 1;
BA_ "VNSigPrimaryTriggering" SG_ 1583 VectraSpcNWMgtD 1;
BA_ "VNSigRemoteDiagnostics" SG_ 1583 VectraSpcNWMgtD 1;
BA_ "VNSigInfotainment" SG_ 1583 VectraSpcNWMgtD 1;
BA_ "VNSigParkedVehicle" SG_ 1583 VectraSpcNWMgtD 1;
BA_ "VNSigIntermediate" SG_ 1583 VectraSpcNWMgtD 1;
BA_ "VNSigUnused_4" SG_ 1583 VectraSpcNWMgtD 1;
BA_ "SignalType" SG_ 1583 VectraSpcNWMgtD "UNM";
BA_ "SignalLongName" SG_ 1583 VectraSpcNWMgtD "Vectra Specific Network Management Data";
BA_ "VNSigDiagnostic" SG_ 1583 VectraSpcNWMgtD 1;
BA_ "VNSigAllNodes" SG_ 1583 VectraSpcNWMgtD 1;
BA_ "VNSigPrimaryTriggering" SG_ 1585 VectraSpcNWMgtD 1;
BA_ "VNSigRemoteDiagnostics" SG_ 1585 VectraSpcNWMgtD 1;
BA_ "VNSigInfotainment" SG_ 1585 VectraSpcNWMgtD 1;
BA_ "VNSigParkedVehicle" SG_ 1585 VectraSpcNWMgtD 1;
BA_ "VNSigIntermediate" SG_ 1585 VectraSpcNWMgtD 1;
BA_ "VNSigUnused_4" SG_ 1585 VectraSpcNWMgtD 1;
BA_ "SignalType" SG_ 1585 VectraSpcNWMgtD "UNM";
BA_ "SignalLongName" SG_ 1585 VectraSpcNWMgtD "Vectra Specific Network Management Data";
BA_ "VNSigDiagnostic" SG_ 1585 VectraSpcNWMgtD 1;
BA_ "VNSigAllNodes" SG_ 1585 VectraSpcNWMgtD 1;
BA_ "VNSigPrimaryTriggering" SG_ 1586 VectraSpcNWMgtD 1;
BA_ "VNSigRemoteDiagnostics" SG_ 1586 VectraSpcNWMgtD 1;
BA_ "VNSigInfotainment" SG_ 1586 VectraSpcNWMgtD 1;
BA_ "VNSigParkedVehicle" SG_ 1586 VectraSpcNWMgtD 1;
BA_ "VNSigIntermediate" SG_ 1586 VectraSpcNWMgtD 1;
BA_ "VNSigUnused_4" SG_ 1586 VectraSpcNWMgtD 1;
BA_ "SignalType" SG_ 1586 VectraSpcNWMgtD "UNM";
BA_ "SignalLongName" SG_ 1586 VectraSpcNWMgtD "Vectra Specific Network Management Data";
BA_ "VNSigDiagnostic" SG_ 1586 VectraSpcNWMgtD 1;
BA_ "VNSigAllNodes" SG_ 1586 VectraSpcNWMgtD 1;
BA_ "VNSigPrimaryTriggering" SG_ 1591 VectraSpcNWMgtD 1;
BA_ "VNSigRemoteDiagnostics" SG_ 1591 VectraSpcNWMgtD 1;
BA_ "VNSigInfotainment" SG_ 1591 VectraSpcNWMgtD 1;
BA_ "VNSigParkedVehicle" SG_ 1591 VectraSpcNWMgtD 1;
BA_ "VNSigIntermediate" SG_ 1591 VectraSpcNWMgtD 1;
BA_ "VNSigUnused_4" SG_ 1591 VectraSpcNWMgtD 1;
BA_ "SignalType" SG_ 1591 VectraSpcNWMgtD "UNM";
BA_ "SignalLongName" SG_ 1591 VectraSpcNWMgtD "Vectra Specific Network Management Data";
BA_ "VNSigDiagnostic" SG_ 1591 VectraSpcNWMgtD 1;
BA_ "VNSigAllNodes" SG_ 1591 VectraSpcNWMgtD 1;
BA_ "VNSigPrimaryTriggering" SG_ 1572 VectraSpcNWMgtD 1;
BA_ "VNSigRemoteDiagnostics" SG_ 1572 VectraSpcNWMgtD 1;
BA_ "VNSigInfotainment" SG_ 1572 VectraSpcNWMgtD 1;
BA_ "VNSigParkedVehicle" SG_ 1572 VectraSpcNWMgtD 1;
BA_ "VNSigIntermediate" SG_ 1572 VectraSpcNWMgtD 1;
BA_ "VNSigUnused_4" SG_ 1572 VectraSpcNWMgtD 1;
BA_ "SignalType" SG_ 1572 VectraSpcNWMgtD "UNM";
BA_ "SignalLongName" SG_ 1572 VectraSpcNWMgtD "Vectra Specific Network Management Data";
BA_ "VNSigDiagnostic" SG_ 1572 VectraSpcNWMgtD 1;
BA_ "VNSigAllNodes" SG_ 1572 VectraSpcNWMgtD 1;
BA_ "VNSigPrimaryTriggering" SG_ 1578 VectraSpcNWMgtD 1;
BA_ "VNSigRemoteDiagnostics" SG_ 1578 VectraSpcNWMgtD 1;
BA_ "VNSigInfotainment" SG_ 1578 VectraSpcNWMgtD 1;
BA_ "VNSigParkedVehicle" SG_ 1578 VectraSpcNWMgtD 1;
BA_ "VNSigIntermediate" SG_ 1578 VectraSpcNWMgtD 1;
BA_ "VNSigUnused_4" SG_ 1578 VectraSpcNWMgtD 1;
BA_ "SignalType" SG_ 1578 VectraSpcNWMgtD "UNM";
BA_ "SignalLongName" SG_ 1578 VectraSpcNWMgtD "Vectra Specific Network Management Data";
BA_ "VNSigDiagnostic" SG_ 1578 VectraSpcNWMgtD 1;
BA_ "VNSigAllNodes" SG_ 1578 VectraSpcNWMgtD 1;
BA_ "VNSigPrimaryTriggering" SG_ 1597 VectraSpcNWMgtD 1;
BA_ "VNSigRemoteDiagnostics" SG_ 1597 VectraSpcNWMgtD 1;
BA_ "VNSigInfotainment" SG_ 1597 VectraSpcNWMgtD 1;
BA_ "VNSigParkedVehicle" SG_ 1597 VectraSpcNWMgtD 1;
BA_ "VNSigIntermediate" SG_ 1597 VectraSpcNWMgtD 1;
BA_ "VNSigUnused_4" SG_ 1597 VectraSpcNWMgtD 1;
BA_ "SignalType" SG_ 1597 VectraSpcNWMgtD "UNM";
BA_ "SignalLongName" SG_ 1597 VectraSpcNWMgtD "Vectra Specific Network Management Data";
BA_ "VNSigDiagnostic" SG_ 1597 VectraSpcNWMgtD 1;
BA_ "VNSigAllNodes" SG_ 1597 VectraSpcNWMgtD 1;
BA_ "VNSigPrimaryTriggering" SG_ 1598 VectraSpcNWMgtD 1;
BA_ "VNSigRemoteDiagnostics" SG_ 1598 VectraSpcNWMgtD 1;
BA_ "VNSigInfotainment" SG_ 1598 VectraSpcNWMgtD 1;
BA_ "VNSigParkedVehicle" SG_ 1598 VectraSpcNWMgtD 1;
BA_ "VNSigIntermediate" SG_ 1598 VectraSpcNWMgtD 1;
BA_ "VNSigUnused_4" SG_ 1598 VectraSpcNWMgtD 1;
BA_ "SignalType" SG_ 1598 VectraSpcNWMgtD "UNM";
BA_ "SignalLongName" SG_ 1598 VectraSpcNWMgtD "Vectra Specific Network Management Data";
BA_ "VNSigDiagnostic" SG_ 1598 VectraSpcNWMgtD 1;
BA_ "VNSigAllNodes" SG_ 1598 VectraSpcNWMgtD 1;
BA_ "VNSigPrimaryTriggering" SG_ 1576 VectraSpcNWMgtD 1;
BA_ "VNSigRemoteDiagnostics" SG_ 1576 VectraSpcNWMgtD 1;
BA_ "VNSigInfotainment" SG_ 1576 VectraSpcNWMgtD 1;
BA_ "VNSigParkedVehicle" SG_ 1576 VectraSpcNWMgtD 1;
BA_ "VNSigIntermediate" SG_ 1576 VectraSpcNWMgtD 1;
BA_ "VNSigUnused_4" SG_ 1576 VectraSpcNWMgtD 1;
BA_ "SignalType" SG_ 1576 VectraSpcNWMgtD "UNM";
BA_ "SignalLongName" SG_ 1576 VectraSpcNWMgtD "Vectra Specific Network Management Data";
BA_ "VNSigDiagnostic" SG_ 1576 VectraSpcNWMgtD 1;
BA_ "VNSigAllNodes" SG_ 1576 VectraSpcNWMgtD 1;
BA_ "VNSigPrimaryTriggering" SG_ 1582 VectraSpcNWMgtD 1;
BA_ "VNSigRemoteDiagnostics" SG_ 1582 VectraSpcNWMgtD 1;
BA_ "VNSigInfotainment" SG_ 1582 VectraSpcNWMgtD 1;
BA_ "VNSigParkedVehicle" SG_ 1582 VectraSpcNWMgtD 1;
BA_ "VNSigIntermediate" SG_ 1582 VectraSpcNWMgtD 1;
BA_ "VNSigUnused_4" SG_ 1582 VectraSpcNWMgtD 1;
BA_ "SignalType" SG_ 1582 VectraSpcNWMgtD "UNM";
BA_ "SignalLongName" SG_ 1582 VectraSpcNWMgtD "Vectra Specific Network Management Data";
BA_ "VNSigDiagnostic" SG_ 1582 VectraSpcNWMgtD 1;
BA_ "VNSigAllNodes" SG_ 1582 VectraSpcNWMgtD 1;
BA_ "VNSigPrimaryTriggering" SG_ 1590 VectraSpcNWMgtD 1;
BA_ "VNSigRemoteDiagnostics" SG_ 1590 VectraSpcNWMgtD 1;
BA_ "VNSigInfotainment" SG_ 1590 VectraSpcNWMgtD 1;
BA_ "VNSigParkedVehicle" SG_ 1590 VectraSpcNWMgtD 1;
BA_ "VNSigIntermediate" SG_ 1590 VectraSpcNWMgtD 1;
BA_ "VNSigUnused_4" SG_ 1590 VectraSpcNWMgtD 1;
BA_ "SignalType" SG_ 1590 VectraSpcNWMgtD "UNM";
BA_ "SignalLongName" SG_ 1590 VectraSpcNWMgtD "Vectra Specific Network Management Data";
BA_ "VNSigDiagnostic" SG_ 1590 VectraSpcNWMgtD 1;
BA_ "VNSigAllNodes" SG_ 1590 VectraSpcNWMgtD 1;
BA_ "VNSigPrimaryTriggering" SG_ 1592 VectraSpcNWMgtD 1;
BA_ "VNSigRemoteDiagnostics" SG_ 1592 VectraSpcNWMgtD 1;
BA_ "VNSigInfotainment" SG_ 1592 VectraSpcNWMgtD 1;
BA_ "VNSigParkedVehicle" SG_ 1592 VectraSpcNWMgtD 1;
BA_ "VNSigIntermediate" SG_ 1592 VectraSpcNWMgtD 1;
BA_ "VNSigUnused_4" SG_ 1592 VectraSpcNWMgtD 1;
BA_ "SignalType" SG_ 1592 VectraSpcNWMgtD "UNM";
BA_ "SignalLongName" SG_ 1592 VectraSpcNWMgtD "Vectra Specific Network Management Data";
BA_ "VNSigDiagnostic" SG_ 1592 VectraSpcNWMgtD 1;
BA_ "VNSigAllNodes" SG_ 1592 VectraSpcNWMgtD 1;
BA_ "VNSigPrimaryTriggering" SG_ 1594 VectraSpcNWMgtD 1;
BA_ "VNSigRemoteDiagnostics" SG_ 1594 VectraSpcNWMgtD 1;
BA_ "VNSigInfotainment" SG_ 1594 VectraSpcNWMgtD 1;
BA_ "VNSigParkedVehicle" SG_ 1594 VectraSpcNWMgtD 1;
BA_ "VNSigIntermediate" SG_ 1594 VectraSpcNWMgtD 1;
BA_ "VNSigUnused_4" SG_ 1594 VectraSpcNWMgtD 1;
BA_ "SignalType" SG_ 1594 VectraSpcNWMgtD "UNM";
BA_ "SignalLongName" SG_ 1594 VectraSpcNWMgtD "Vectra Specific Network Management Data";
BA_ "VNSigDiagnostic" SG_ 1594 VectraSpcNWMgtD 1;
BA_ "VNSigAllNodes" SG_ 1594 VectraSpcNWMgtD 1;
BA_ "VNSigPrimaryTriggering" SG_ 1595 VectraSpcNWMgtD 1;
BA_ "VNSigRemoteDiagnostics" SG_ 1595 VectraSpcNWMgtD 1;
BA_ "VNSigInfotainment" SG_ 1595 VectraSpcNWMgtD 1;
BA_ "VNSigParkedVehicle" SG_ 1595 VectraSpcNWMgtD 1;
BA_ "VNSigIntermediate" SG_ 1595 VectraSpcNWMgtD 1;
BA_ "VNSigUnused_4" SG_ 1595 VectraSpcNWMgtD 1;
BA_ "SignalType" SG_ 1595 VectraSpcNWMgtD "UNM";
BA_ "SignalLongName" SG_ 1595 VectraSpcNWMgtD "Vectra Specific Network Management Data";
BA_ "VNSigDiagnostic" SG_ 1595 VectraSpcNWMgtD 1;
BA_ "VNSigAllNodes" SG_ 1595 VectraSpcNWMgtD 1;
BA_ "VNSigPrimaryTriggering" SG_ 1593 VectraSpcNWMgtD 1;
BA_ "VNSigRemoteDiagnostics" SG_ 1593 VectraSpcNWMgtD 1;
BA_ "VNSigInfotainment" SG_ 1593 VectraSpcNWMgtD 1;
BA_ "VNSigParkedVehicle" SG_ 1593 VectraSpcNWMgtD 1;
BA_ "VNSigIntermediate" SG_ 1593 VectraSpcNWMgtD 1;
BA_ "VNSigUnused_4" SG_ 1593 VectraSpcNWMgtD 1;
BA_ "SignalType" SG_ 1593 VectraSpcNWMgtD "UNM";
BA_ "SignalLongName" SG_ 1593 VectraSpcNWMgtD "Vectra Specific Network Management Data";
BA_ "VNSigDiagnostic" SG_ 1593 VectraSpcNWMgtD 1;
BA_ "VNSigAllNodes" SG_ 1593 VectraSpcNWMgtD 1;
BA_ "VNSigPrimaryTriggering" SG_ 1589 VectraSpcNWMgtD 1;
BA_ "VNSigRemoteDiagnostics" SG_ 1589 VectraSpcNWMgtD 1;
BA_ "VNSigInfotainment" SG_ 1589 VectraSpcNWMgtD 1;
BA_ "VNSigParkedVehicle" SG_ 1589 VectraSpcNWMgtD 1;
BA_ "VNSigIntermediate" SG_ 1589 VectraSpcNWMgtD 1;
BA_ "VNSigUnused_4" SG_ 1589 VectraSpcNWMgtD 1;
BA_ "SignalType" SG_ 1589 VectraSpcNWMgtD "UNM";
BA_ "SignalLongName" SG_ 1589 VectraSpcNWMgtD "Vectra Specific Network Management Data";
BA_ "VNSigDiagnostic" SG_ 1589 VectraSpcNWMgtD 1;
BA_ "VNSigAllNodes" SG_ 1589 VectraSpcNWMgtD 1;
BA_ "GenSigSendType" SG_ 2150219776 PhnSpRcgnRq 10;
BA_ "VNSigInfotainment" SG_ 2150219776 PhnSpRcgnRq 1;
BA_ "SignalType" SG_ 2150219776 PhnSpRcgnRq "ENM";
BA_ "SignalLongName" SG_ 2150219776 PhnSpRcgnRq "Phone Speech Recognition Request";
BA_ "VNSigAllNodes" SG_ 2150219776 PhnSpRcgnRq 1;
BA_ "GenSigSendType" SG_ 2150219776 VcRecVcFdbckSt 10;
BA_ "GenSigSendOnInit" SG_ 2150219776 VcRecVcFdbckSt 1;
BA_ "VNSigInfotainment" SG_ 2150219776 VcRecVcFdbckSt 1;
BA_ "SignalType" SG_ 2150219776 VcRecVcFdbckSt "ENM";
BA_ "SignalLongName" SG_ 2150219776 VcRecVcFdbckSt "Voice Recognition Voice Feedback Status";
BA_ "VNSigAllNodes" SG_ 2150219776 VcRecVcFdbckSt 1;
BA_ "SignalType" SG_ 589 DgnInf "UNM";
BA_ "SignalLongName" SG_ 589 DgnInf "Diagnostic Information";
BA_ "VNSigDiagnostic" SG_ 589 DgnInf 1;
BA_ "VNSigAllNodes" SG_ 589 DgnInf 1;
BA_ "GenSigDeltaValue" SG_ 2152685568 RadConInfID 1;
BA_ "GenSigSendType" SG_ 2152685568 RadConInfID 12;
BA_ "GenSigSendOnInit" SG_ 2152685568 RadConInfID 1;
BA_ "VNSigInfotainment" SG_ 2152685568 RadConInfID 1;
BA_ "SignalType" SG_ 2152685568 RadConInfID "UNM";
BA_ "SignalLongName" SG_ 2152685568 RadConInfID "Radio Content Information Identifier";
BA_ "VNSigAllNodes" SG_ 2152685568 RadConInfID 1;
BA_ "GenSigSendType" SG_ 2152685568 RadConInfReqSrc 10;
BA_ "GenSigSendOnInit" SG_ 2152685568 RadConInfReqSrc 1;
BA_ "VNSigInfotainment" SG_ 2152685568 RadConInfReqSrc 1;
BA_ "SignalType" SG_ 2152685568 RadConInfReqSrc "ENM";
BA_ "SignalLongName" SG_ 2152685568 RadConInfReqSrc "Radio Content Information Requesting Source";
BA_ "VNSigAllNodes" SG_ 2152685568 RadConInfReqSrc 1;
BA_ "GenSigSendType" SG_ 2152685568 RadBrdcstSrc 10;
BA_ "GenSigSendOnInit" SG_ 2152685568 RadBrdcstSrc 1;
BA_ "VNSigInfotainment" SG_ 2152685568 RadBrdcstSrc 1;
BA_ "SignalType" SG_ 2152685568 RadBrdcstSrc "ENM";
BA_ "SignalLongName" SG_ 2152685568 RadBrdcstSrc "Radio Broadcast Source";
BA_ "VNSigAllNodes" SG_ 2152685568 RadBrdcstSrc 1;
BA_ "GenSigSendType" SG_ 2152685568 RadConInfCmd 10;
BA_ "GenSigSendOnInit" SG_ 2152685568 RadConInfCmd 1;
BA_ "VNSigInfotainment" SG_ 2152685568 RadConInfCmd 1;
BA_ "SignalType" SG_ 2152685568 RadConInfCmd "ENM";
BA_ "SignalLongName" SG_ 2152685568 RadConInfCmd "Radio Content Information Command";
BA_ "VNSigAllNodes" SG_ 2152685568 RadConInfCmd 1;
BA_ "GenSigSendType" SG_ 2151874560 RstVTDTmprDtctd 10;
BA_ "SignalType" SG_ 2151874560 RstVTDTmprDtctd "ENM";
BA_ "SignalLongName" SG_ 2151874560 RstVTDTmprDtctd "Reset Vehicle Theft Deterrent Tamper Detected";
BA_ "VNSigAllNodes" SG_ 2151874560 RstVTDTmprDtctd 1;
BA_ "GenSigSendType" SG_ 2151874560 RstIllDrIdDevDtctd 10;
BA_ "SignalType" SG_ 2151874560 RstIllDrIdDevDtctd "ENM";
BA_ "SignalLongName" SG_ 2151874560 RstIllDrIdDevDtctd "Reset Illegitimate Driver Identification Device Detected";
BA_ "VNSigAllNodes" SG_ 2151874560 RstIllDrIdDevDtctd 1;
BA_ "GenSigSendType" SG_ 2151874560 RstDrIdDevLrnd 10;
BA_ "SignalType" SG_ 2151874560 RstDrIdDevLrnd "ENM";
BA_ "SignalLongName" SG_ 2151874560 RstDrIdDevLrnd "Reset Driver Identification Device Learned";
BA_ "VNSigAllNodes" SG_ 2151874560 RstDrIdDevLrnd 1;
BA_ "GenSigSendType" SG_ 2151874560 ESEIC_EngImRqPsw 10;
BA_ "SignalType" SG_ 2151874560 ESEIC_EngImRqPsw "ASC";
BA_ "PacketOrder" SG_ 2151874560 ESEIC_EngImRqPsw 2;
BA_ "SignalLongName" SG_ 2151874560 ESEIC_EngImRqPsw "Enhanced Services Engine Immobilization Command : Enhanced Services Engine Immobilization Request Password";
BA_ "VNSigAllNodes" SG_ 2151874560 ESEIC_EngImRqPsw 1;
BA_ "GenSigSendType" SG_ 2151874560 ESEIC_EngImmbRq 10;
BA_ "SignalType" SG_ 2151874560 ESEIC_EngImmbRq "ENM";
BA_ "PacketOrder" SG_ 2151874560 ESEIC_EngImmbRq 1;
BA_ "SignalLongName" SG_ 2151874560 ESEIC_EngImmbRq "Enhanced Services Engine Immobilization Command : Enhanced Services Engine Immobilization Request";
BA_ "VNSigAllNodes" SG_ 2151874560 ESEIC_EngImmbRq 1;
BA_ "SignalType" SG_ 1357 DgnInf_LS54D "UNM";
BA_ "SignalLongName" SG_ 1357 DgnInf_LS54D "Diagnostic Information LS54D";
BA_ "VNSigDiagnostic" SG_ 1357 DgnInf_LS54D 1;
BA_ "VNSigAllNodes" SG_ 1357 DgnInf_LS54D 1;
BA_ "SignalType" SG_ 1613 DgnInf "UNM";
BA_ "SignalLongName" SG_ 1613 DgnInf "Diagnostic Information";
BA_ "VNSigDiagnostic" SG_ 1613 DgnInf 1;
BA_ "VNSigAllNodes" SG_ 1613 DgnInf 1;
BA_ "GenSigSendType" SG_ 2150268928 EmrgncyRspSysTyp 10;
BA_ "SignalType" SG_ 2150268928 EmrgncyRspSysTyp "ENM";
BA_ "SignalLongName" SG_ 2150268928 EmrgncyRspSysTyp "Emergency Response System Type";
BA_ "VNSigAllNodes" SG_ 2150268928 EmrgncyRspSysTyp 1;
BA_ "GenSigSendType" SG_ 2150268928 EmrgncyRspSysSrvIndOn 10;
BA_ "GenSigSendOnInit" SG_ 2150268928 EmrgncyRspSysSrvIndOn 1;
BA_ "SignalType" SG_ 2150268928 EmrgncyRspSysSrvIndOn "BLN";
BA_ "SignalLongName" SG_ 2150268928 EmrgncyRspSysSrvIndOn "Emergency Response System Service Indication On";
BA_ "VNSigAllNodes" SG_ 2150268928 EmrgncyRspSysSrvIndOn 1;
BA_ "GenSigDeltaValue" SG_ 2150268928 CldrYr_154 1;
BA_ "GenSigSendType" SG_ 2150268928 CldrYr_154 12;
BA_ "GenSigSendOnInit" SG_ 2150268928 CldrYr_154 1;
BA_ "VNSigInfotainment" SG_ 2150268928 CldrYr_154 1;
BA_ "SignalType" SG_ 2150268928 CldrYr_154 "UNM";
BA_ "SignalLongName" SG_ 2150268928 CldrYr_154 "Calendar Year";
BA_ "VNSigAllNodes" SG_ 2150268928 CldrYr_154 1;
BA_ "GenSigSendType" SG_ 2150268928 CldrMth_154 10;
BA_ "GenSigSendOnInit" SG_ 2150268928 CldrMth_154 1;
BA_ "VNSigInfotainment" SG_ 2150268928 CldrMth_154 1;
BA_ "SignalType" SG_ 2150268928 CldrMth_154 "ENM";
BA_ "SignalLongName" SG_ 2150268928 CldrMth_154 "Calendar Month";
BA_ "VNSigAllNodes" SG_ 2150268928 CldrMth_154 1;
BA_ "GenSigDeltaValue" SG_ 2150268928 CldrDay_154 1;
BA_ "GenSigSendType" SG_ 2150268928 CldrDay_154 12;
BA_ "GenSigSendOnInit" SG_ 2150268928 CldrDay_154 1;
BA_ "VNSigInfotainment" SG_ 2150268928 CldrDay_154 1;
BA_ "SignalType" SG_ 2150268928 CldrDay_154 "UNM";
BA_ "SignalLongName" SG_ 2150268928 CldrDay_154 "Calendar Day";
BA_ "VNSigAllNodes" SG_ 2150268928 CldrDay_154 1;
BA_ "GenSigSendType" SG_ 2150268928 SecV 10;
BA_ "GenSigSendOnInit" SG_ 2150268928 SecV 1;
BA_ "VNSigInfotainment" SG_ 2150268928 SecV 1;
BA_ "SignalType" SG_ 2150268928 SecV "ENM";
BA_ "SignalLongName" SG_ 2150268928 SecV "Seconds Validity";
BA_ "VNSigAllNodes" SG_ 2150268928 SecV 1;
BA_ "GenSigDeltaValue" SG_ 2150268928 Sec 1;
BA_ "GenSigSendType" SG_ 2150268928 Sec 12;
BA_ "GenSigSendOnInit" SG_ 2150268928 Sec 1;
BA_ "VNSigInfotainment" SG_ 2150268928 Sec 1;
BA_ "SignalType" SG_ 2150268928 Sec "UNM";
BA_ "SignalLongName" SG_ 2150268928 Sec "Seconds";
BA_ "VNSigAllNodes" SG_ 2150268928 Sec 1;
BA_ "GenSigSendType" SG_ 2150268928 MinsV 10;
BA_ "GenSigSendOnInit" SG_ 2150268928 MinsV 1;
BA_ "VNSigInfotainment" SG_ 2150268928 MinsV 1;
BA_ "SignalType" SG_ 2150268928 MinsV "ENM";
BA_ "SignalLongName" SG_ 2150268928 MinsV "Minutes Validity";
BA_ "VNSigAllNodes" SG_ 2150268928 MinsV 1;
BA_ "GenSigDeltaValue" SG_ 2150268928 Mins 1;
BA_ "GenSigSendType" SG_ 2150268928 Mins 12;
BA_ "GenSigSendOnInit" SG_ 2150268928 Mins 1;
BA_ "VNSigInfotainment" SG_ 2150268928 Mins 1;
BA_ "SignalType" SG_ 2150268928 Mins "UNM";
BA_ "SignalLongName" SG_ 2150268928 Mins "Minutes";
BA_ "VNSigAllNodes" SG_ 2150268928 Mins 1;
BA_ "GenSigSendType" SG_ 2150268928 HrsV 10;
BA_ "GenSigSendOnInit" SG_ 2150268928 HrsV 1;
BA_ "VNSigInfotainment" SG_ 2150268928 HrsV 1;
BA_ "SignalType" SG_ 2150268928 HrsV "ENM";
BA_ "SignalLongName" SG_ 2150268928 HrsV "Hours Validity";
BA_ "VNSigAllNodes" SG_ 2150268928 HrsV 1;
BA_ "GenSigDeltaValue" SG_ 2150268928 Hrs 1;
BA_ "GenSigSendType" SG_ 2150268928 Hrs 12;
BA_ "GenSigSendOnInit" SG_ 2150268928 Hrs 1;
BA_ "VNSigInfotainment" SG_ 2150268928 Hrs 1;
BA_ "SignalType" SG_ 2150268928 Hrs "UNM";
BA_ "SignalLongName" SG_ 2150268928 Hrs "Hours";
BA_ "VNSigAllNodes" SG_ 2150268928 Hrs 1;
BA_ "SignalType" SG_ 606 DgnInf "UNM";
BA_ "SignalLongName" SG_ 606 DgnInf "Diagnostic Information";
BA_ "VNSigDiagnostic" SG_ 606 DgnInf 1;
BA_ "VNSigAllNodes" SG_ 606 DgnInf 1;
BA_ "SignalType" SG_ 257 DgnInf "UNM";
BA_ "SignalLongName" SG_ 257 DgnInf "Diagnostic Information";
BA_ "VNSigDiagnostic" SG_ 257 DgnInf 1;
BA_ "VNSigAllNodes" SG_ 257 DgnInf 1;
BA_ "VNSigPrimaryTriggering" SG_ 1587 VectraSpcNWMgtD 1;
BA_ "VNSigRemoteDiagnostics" SG_ 1587 VectraSpcNWMgtD 1;
BA_ "VNSigInfotainment" SG_ 1587 VectraSpcNWMgtD 1;
BA_ "VNSigParkedVehicle" SG_ 1587 VectraSpcNWMgtD 1;
BA_ "VNSigIntermediate" SG_ 1587 VectraSpcNWMgtD 1;
BA_ "VNSigUnused_4" SG_ 1587 VectraSpcNWMgtD 1;
BA_ "SignalType" SG_ 1587 VectraSpcNWMgtD "UNM";
BA_ "SignalLongName" SG_ 1587 VectraSpcNWMgtD "Vectra Specific Network Management Data";
BA_ "VNSigDiagnostic" SG_ 1587 VectraSpcNWMgtD 1;
BA_ "VNSigAllNodes" SG_ 1587 VectraSpcNWMgtD 1;
BA_ "GenSigDeltaValue" SG_ 2041 PCUInfo_7F9 1;
BA_ "GenSigSendType" SG_ 2041 PCUInfo_7F9 12;
BA_ "SignalType" SG_ 2041 PCUInfo_7F9 "UNM";
BA_ "SignalLongName" SG_ 2041 PCUInfo_7F9 "Pyrotechnical Control Unit Information 7F9";
BA_ "VNSigAllNodes" SG_ 2041 PCUInfo_7F9 1;
BA_ "SignalType" SG_ 1608 DgnInf "UNM";
BA_ "SignalLongName" SG_ 1608 DgnInf "Diagnostic Information";
BA_ "VNSigDiagnostic" SG_ 1608 DgnInf 1;
BA_ "VNSigAllNodes" SG_ 1608 DgnInf 1;
BA_ "SignalType" SG_ 584 DgnInf "UNM";
BA_ "SignalLongName" SG_ 584 DgnInf "Diagnostic Information";
BA_ "VNSigDiagnostic" SG_ 584 DgnInf 1;
BA_ "VNSigAllNodes" SG_ 584 DgnInf 1;
BA_ "SignalType" SG_ 1352 DgnInf_LS548 "UNM";
BA_ "SignalLongName" SG_ 1352 DgnInf_LS548 "Diagnostic Information LS548";
BA_ "VNSigDiagnostic" SG_ 1352 DgnInf_LS548 1;
BA_ "VNSigAllNodes" SG_ 1352 DgnInf_LS548 1;
BA_ "SignalType" SG_ 1620 DgnInf "UNM";
BA_ "SignalLongName" SG_ 1620 DgnInf "Diagnostic Information";
BA_ "VNSigDiagnostic" SG_ 1620 DgnInf 1;
BA_ "VNSigAllNodes" SG_ 1620 DgnInf 1;
BA_ "SignalType" SG_ 1364 DgnInf_LS554 "UNM";
BA_ "SignalLongName" SG_ 1364 DgnInf_LS554 "Diagnostic Information LS554";
BA_ "VNSigDiagnostic" SG_ 1364 DgnInf_LS554 1;
BA_ "VNSigAllNodes" SG_ 1364 DgnInf_LS554 1;
BA_ "SignalType" SG_ 1351 DgnInf_LS547 "UNM";
BA_ "SignalLongName" SG_ 1351 DgnInf_LS547 "Diagnostic Information LS547";
BA_ "VNSigDiagnostic" SG_ 1351 DgnInf_LS547 1;
BA_ "VNSigAllNodes" SG_ 1351 DgnInf_LS547 1;
BA_ "SignalType" SG_ 1607 DgnInf "UNM";
BA_ "SignalLongName" SG_ 1607 DgnInf "Diagnostic Information";
BA_ "VNSigDiagnostic" SG_ 1607 DgnInf 1;
BA_ "VNSigAllNodes" SG_ 1607 DgnInf 1;
BA_ "SignalType" SG_ 583 DgnInf "UNM";
BA_ "SignalLongName" SG_ 583 DgnInf "Diagnostic Information";
BA_ "VNSigDiagnostic" SG_ 583 DgnInf 1;
BA_ "VNSigAllNodes" SG_ 583 DgnInf 1;
BA_ "SignalType" SG_ 1371 DgnInf_LS55B "UNM";
BA_ "SignalLongName" SG_ 1371 DgnInf_LS55B "Diagnostic Information LS55B";
BA_ "VNSigDiagnostic" SG_ 1371 DgnInf_LS55B 1;
BA_ "VNSigAllNodes" SG_ 1371 DgnInf_LS55B 1;
BA_ "SignalType" SG_ 1627 DgnInf "UNM";
BA_ "SignalLongName" SG_ 1627 DgnInf "Diagnostic Information";
BA_ "VNSigDiagnostic" SG_ 1627 DgnInf 1;
BA_ "VNSigAllNodes" SG_ 1627 DgnInf 1;
BA_ "SignalType" SG_ 603 DgnInf "UNM";
BA_ "SignalLongName" SG_ 603 DgnInf "Diagnostic Information";
BA_ "VNSigDiagnostic" SG_ 603 DgnInf 1;
BA_ "VNSigAllNodes" SG_ 603 DgnInf 1;
BA_ "SignalType" SG_ 1370 DgnInf_LS55A "UNM";
BA_ "SignalLongName" SG_ 1370 DgnInf_LS55A "Diagnostic Information LS55A";
BA_ "VNSigDiagnostic" SG_ 1370 DgnInf_LS55A 1;
BA_ "VNSigAllNodes" SG_ 1370 DgnInf_LS55A 1;
BA_ "SignalType" SG_ 1626 DgnInf "UNM";
BA_ "SignalLongName" SG_ 1626 DgnInf "Diagnostic Information";
BA_ "VNSigDiagnostic" SG_ 1626 DgnInf 1;
BA_ "VNSigAllNodes" SG_ 1626 DgnInf 1;
BA_ "SignalType" SG_ 602 DgnInf "UNM";
BA_ "SignalLongName" SG_ 602 DgnInf "Diagnostic Information";
BA_ "VNSigDiagnostic" SG_ 602 DgnInf 1;
BA_ "VNSigAllNodes" SG_ 602 DgnInf 1;
BA_ "SignalType" SG_ 598 DgnInf "UNM";
BA_ "SignalLongName" SG_ 598 DgnInf "Diagnostic Information";
BA_ "VNSigDiagnostic" SG_ 598 DgnInf 1;
BA_ "VNSigAllNodes" SG_ 598 DgnInf 1;
BA_ "SignalType" SG_ 1366 DgnInf_LS556 "UNM";
BA_ "SignalLongName" SG_ 1366 DgnInf_LS556 "Diagnostic Information LS556";
BA_ "VNSigDiagnostic" SG_ 1366 DgnInf_LS556 1;
BA_ "VNSigAllNodes" SG_ 1366 DgnInf_LS556 1;
BA_ "SignalType" SG_ 1622 DgnInf "UNM";
BA_ "SignalLongName" SG_ 1622 DgnInf "Diagnostic Information";
BA_ "VNSigDiagnostic" SG_ 1622 DgnInf 1;
BA_ "VNSigAllNodes" SG_ 1622 DgnInf 1;
BA_ "SignalType" SG_ 580 DgnInf "UNM";
BA_ "SignalLongName" SG_ 580 DgnInf "Diagnostic Information";
BA_ "VNSigDiagnostic" SG_ 580 DgnInf 1;
BA_ "VNSigAllNodes" SG_ 580 DgnInf 1;
BA_ "SignalType" SG_ 1604 DgnInf "UNM";
BA_ "SignalLongName" SG_ 1604 DgnInf "Diagnostic Information";
BA_ "VNSigDiagnostic" SG_ 1604 DgnInf 1;
BA_ "VNSigAllNodes" SG_ 1604 DgnInf 1;
BA_ "SignalType" SG_ 1348 DgnInf_LS544 "UNM";
BA_ "SignalLongName" SG_ 1348 DgnInf_LS544 "Diagnostic Information LS544";
BA_ "VNSigDiagnostic" SG_ 1348 DgnInf_LS544 1;
BA_ "VNSigAllNodes" SG_ 1348 DgnInf_LS544 1;
BA_ "SignalType" SG_ 1615 DgnInf "UNM";
BA_ "SignalLongName" SG_ 1615 DgnInf "Diagnostic Information";
BA_ "VNSigDiagnostic" SG_ 1615 DgnInf 1;
BA_ "VNSigAllNodes" SG_ 1615 DgnInf 1;
BA_ "SignalType" SG_ 1359 DgnInf_LS54F "UNM";
BA_ "SignalLongName" SG_ 1359 DgnInf_LS54F "Diagnostic Information LS54F";
BA_ "VNSigDiagnostic" SG_ 1359 DgnInf_LS54F 1;
BA_ "VNSigAllNodes" SG_ 1359 DgnInf_LS54F 1;
BA_ "SignalType" SG_ 591 DgnInf "UNM";
BA_ "SignalLongName" SG_ 591 DgnInf "Diagnostic Information";
BA_ "VNSigDiagnostic" SG_ 591 DgnInf 1;
BA_ "VNSigAllNodes" SG_ 591 DgnInf 1;
BA_ "SignalType" SG_ 1602 DgnInf "UNM";
BA_ "SignalLongName" SG_ 1602 DgnInf "Diagnostic Information";
BA_ "VNSigDiagnostic" SG_ 1602 DgnInf 1;
BA_ "VNSigAllNodes" SG_ 1602 DgnInf 1;
BA_ "SignalType" SG_ 1346 DgnInf_LS542 "UNM";
BA_ "SignalLongName" SG_ 1346 DgnInf_LS542 "Diagnostic Information LS542";
BA_ "VNSigDiagnostic" SG_ 1346 DgnInf_LS542 1;
BA_ "VNSigAllNodes" SG_ 1346 DgnInf_LS542 1;
BA_ "SignalType" SG_ 578 DgnInf "UNM";
BA_ "SignalLongName" SG_ 578 DgnInf "Diagnostic Information";
BA_ "VNSigDiagnostic" SG_ 578 DgnInf 1;
BA_ "VNSigAllNodes" SG_ 578 DgnInf 1;
BA_ "SignalType" SG_ 1614 DgnInf "UNM";
BA_ "SignalLongName" SG_ 1614 DgnInf "Diagnostic Information";
BA_ "VNSigDiagnostic" SG_ 1614 DgnInf 1;
BA_ "VNSigAllNodes" SG_ 1614 DgnInf 1;
BA_ "SignalType" SG_ 1358 DgnInf_LS54E "UNM";
BA_ "SignalLongName" SG_ 1358 DgnInf_LS54E "Diagnostic Information LS54E";
BA_ "VNSigDiagnostic" SG_ 1358 DgnInf_LS54E 1;
BA_ "VNSigAllNodes" SG_ 1358 DgnInf_LS54E 1;
BA_ "SignalType" SG_ 1356 DgnInf_LS54C "UNM";
BA_ "SignalLongName" SG_ 1356 DgnInf_LS54C "Diagnostic Information LS54C";
BA_ "VNSigDiagnostic" SG_ 1356 DgnInf_LS54C 1;
BA_ "VNSigAllNodes" SG_ 1356 DgnInf_LS54C 1;
BA_ "SignalType" SG_ 1612 DgnInf "UNM";
BA_ "SignalLongName" SG_ 1612 DgnInf "Diagnostic Information";
BA_ "VNSigDiagnostic" SG_ 1612 DgnInf 1;
BA_ "VNSigAllNodes" SG_ 1612 DgnInf 1;
BA_ "SignalType" SG_ 588 DgnInf "UNM";
BA_ "SignalLongName" SG_ 588 DgnInf "Diagnostic Information";
BA_ "VNSigDiagnostic" SG_ 588 DgnInf 1;
BA_ "VNSigAllNodes" SG_ 588 DgnInf 1;
BA_ "SignalType" SG_ 1360 DgnInf_LS550 "UNM";
BA_ "SignalLongName" SG_ 1360 DgnInf_LS550 "Diagnostic Information LS550";
BA_ "VNSigDiagnostic" SG_ 1360 DgnInf_LS550 1;
BA_ "VNSigAllNodes" SG_ 1360 DgnInf_LS550 1;
BA_ "SignalType" SG_ 1616 DgnInf "UNM";
BA_ "SignalLongName" SG_ 1616 DgnInf "Diagnostic Information";
BA_ "VNSigDiagnostic" SG_ 1616 DgnInf 1;
BA_ "VNSigAllNodes" SG_ 1616 DgnInf 1;
BA_ "SignalType" SG_ 592 DgnInf "UNM";
BA_ "SignalLongName" SG_ 592 DgnInf "Diagnostic Information";
BA_ "VNSigDiagnostic" SG_ 592 DgnInf 1;
BA_ "VNSigAllNodes" SG_ 592 DgnInf 1;
BA_ "SignalType" SG_ 1375 DgnInf_LS55F "UNM";
BA_ "SignalLongName" SG_ 1375 DgnInf_LS55F "Diagnostic Information LS55F";
BA_ "VNSigDiagnostic" SG_ 1375 DgnInf_LS55F 1;
BA_ "VNSigAllNodes" SG_ 1375 DgnInf_LS55F 1;
BA_ "SignalType" SG_ 1631 DgnInf "UNM";
BA_ "SignalLongName" SG_ 1631 DgnInf "Diagnostic Information";
BA_ "VNSigDiagnostic" SG_ 1631 DgnInf 1;
BA_ "VNSigAllNodes" SG_ 1631 DgnInf 1;
BA_ "SignalType" SG_ 607 DgnInf "UNM";
BA_ "SignalLongName" SG_ 607 DgnInf "Diagnostic Information";
BA_ "VNSigDiagnostic" SG_ 607 DgnInf 1;
BA_ "VNSigAllNodes" SG_ 607 DgnInf 1;
BA_ "SignalType" SG_ 1361 DgnInf_LS551 "UNM";
BA_ "SignalLongName" SG_ 1361 DgnInf_LS551 "Diagnostic Information LS551";
BA_ "VNSigDiagnostic" SG_ 1361 DgnInf_LS551 1;
BA_ "VNSigAllNodes" SG_ 1361 DgnInf_LS551 1;
BA_ "SignalType" SG_ 1617 DgnInf "UNM";
BA_ "SignalLongName" SG_ 1617 DgnInf "Diagnostic Information";
BA_ "VNSigDiagnostic" SG_ 1617 DgnInf 1;
BA_ "VNSigAllNodes" SG_ 1617 DgnInf 1;
BA_ "SignalType" SG_ 593 DgnInf "UNM";
BA_ "SignalLongName" SG_ 593 DgnInf "Diagnostic Information";
BA_ "VNSigDiagnostic" SG_ 593 DgnInf 1;
BA_ "VNSigAllNodes" SG_ 593 DgnInf 1;
BA_ "SignalType" SG_ 1362 DgnInf_LS552 "UNM";
BA_ "SignalLongName" SG_ 1362 DgnInf_LS552 "Diagnostic Information LS552";
BA_ "VNSigDiagnostic" SG_ 1362 DgnInf_LS552 1;
BA_ "VNSigAllNodes" SG_ 1362 DgnInf_LS552 1;
BA_ "SignalType" SG_ 1618 DgnInf "UNM";
BA_ "SignalLongName" SG_ 1618 DgnInf "Diagnostic Information";
BA_ "VNSigDiagnostic" SG_ 1618 DgnInf 1;
BA_ "VNSigAllNodes" SG_ 1618 DgnInf 1;
BA_ "SignalType" SG_ 594 DgnInf "UNM";
BA_ "SignalLongName" SG_ 594 DgnInf "Diagnostic Information";
BA_ "VNSigDiagnostic" SG_ 594 DgnInf 1;
BA_ "VNSigAllNodes" SG_ 594 DgnInf 1;
BA_ "SignalType" SG_ 1373 DgnInf_LS55D "UNM";
BA_ "SignalLongName" SG_ 1373 DgnInf_LS55D "Diagnostic Information LS55D";
BA_ "VNSigDiagnostic" SG_ 1373 DgnInf_LS55D 1;
BA_ "VNSigAllNodes" SG_ 1373 DgnInf_LS55D 1;
BA_ "SignalType" SG_ 1629 DgnInf "UNM";
BA_ "SignalLongName" SG_ 1629 DgnInf "Diagnostic Information";
BA_ "VNSigDiagnostic" SG_ 1629 DgnInf 1;
BA_ "VNSigAllNodes" SG_ 1629 DgnInf 1;
BA_ "SignalType" SG_ 605 DgnInf "UNM";
BA_ "SignalLongName" SG_ 605 DgnInf "Diagnostic Information";
BA_ "VNSigDiagnostic" SG_ 605 DgnInf 1;
BA_ "VNSigAllNodes" SG_ 605 DgnInf 1;
BA_ "SignalType" SG_ 1345 DgnInf_LS541 "UNM";
BA_ "SignalLongName" SG_ 1345 DgnInf_LS541 "Diagnostic Information LS541";
BA_ "VNSigDiagnostic" SG_ 1345 DgnInf_LS541 1;
BA_ "VNSigAllNodes" SG_ 1345 DgnInf_LS541 1;
BA_ "SignalType" SG_ 1601 DgnInf "UNM";
BA_ "SignalLongName" SG_ 1601 DgnInf "Diagnostic Information";
BA_ "VNSigDiagnostic" SG_ 1601 DgnInf 1;
BA_ "VNSigAllNodes" SG_ 1601 DgnInf 1;
BA_ "SignalType" SG_ 577 DgnInf "UNM";
BA_ "SignalLongName" SG_ 577 DgnInf "Diagnostic Information";
BA_ "VNSigDiagnostic" SG_ 577 DgnInf 1;
BA_ "VNSigAllNodes" SG_ 577 DgnInf 1;
BA_ "SignalType" SG_ 601 DgnInf "UNM";
BA_ "SignalLongName" SG_ 601 DgnInf "Diagnostic Information";
BA_ "VNSigDiagnostic" SG_ 601 DgnInf 1;
BA_ "VNSigAllNodes" SG_ 601 DgnInf 1;
BA_ "SignalType" SG_ 1369 DgnInf_LS559 "UNM";
BA_ "SignalLongName" SG_ 1369 DgnInf_LS559 "Diagnostic Information LS559";
BA_ "VNSigDiagnostic" SG_ 1369 DgnInf_LS559 1;
BA_ "VNSigAllNodes" SG_ 1369 DgnInf_LS559 1;
BA_ "SignalType" SG_ 595 DgnInf "UNM";
BA_ "SignalLongName" SG_ 595 DgnInf "Diagnostic Information";
BA_ "VNSigDiagnostic" SG_ 595 DgnInf 1;
BA_ "VNSigAllNodes" SG_ 595 DgnInf 1;
BA_ "VNSigPrimaryTriggering" SG_ 1575 VectraSpcNWMgtD 1;
BA_ "VNSigRemoteDiagnostics" SG_ 1575 VectraSpcNWMgtD 1;
BA_ "VNSigInfotainment" SG_ 1575 VectraSpcNWMgtD 1;
BA_ "VNSigParkedVehicle" SG_ 1575 VectraSpcNWMgtD 1;
BA_ "VNSigIntermediate" SG_ 1575 VectraSpcNWMgtD 1;
BA_ "VNSigUnused_4" SG_ 1575 VectraSpcNWMgtD 1;
BA_ "SignalType" SG_ 1575 VectraSpcNWMgtD "UNM";
BA_ "SignalLongName" SG_ 1575 VectraSpcNWMgtD "Vectra Specific Network Management Data";
BA_ "VNSigDiagnostic" SG_ 1575 VectraSpcNWMgtD 1;
BA_ "VNSigAllNodes" SG_ 1575 VectraSpcNWMgtD 1;
BA_ "VNSigPrimaryTriggering" SG_ 1581 VectraSpcNWMgtD 1;
BA_ "VNSigRemoteDiagnostics" SG_ 1581 VectraSpcNWMgtD 1;
BA_ "VNSigInfotainment" SG_ 1581 VectraSpcNWMgtD 1;
BA_ "VNSigParkedVehicle" SG_ 1581 VectraSpcNWMgtD 1;
BA_ "VNSigIntermediate" SG_ 1581 VectraSpcNWMgtD 1;
BA_ "VNSigUnused_4" SG_ 1581 VectraSpcNWMgtD 1;
BA_ "SignalType" SG_ 1581 VectraSpcNWMgtD "UNM";
BA_ "SignalLongName" SG_ 1581 VectraSpcNWMgtD "Vectra Specific Network Management Data";
BA_ "VNSigDiagnostic" SG_ 1581 VectraSpcNWMgtD 1;
BA_ "VNSigAllNodes" SG_ 1581 VectraSpcNWMgtD 1;
BA_ "VNSigPrimaryTriggering" SG_ 1580 VectraSpcNWMgtD 1;
BA_ "VNSigRemoteDiagnostics" SG_ 1580 VectraSpcNWMgtD 1;
BA_ "VNSigInfotainment" SG_ 1580 VectraSpcNWMgtD 1;
BA_ "VNSigParkedVehicle" SG_ 1580 VectraSpcNWMgtD 1;
BA_ "VNSigIntermediate" SG_ 1580 VectraSpcNWMgtD 1;
BA_ "VNSigUnused_4" SG_ 1580 VectraSpcNWMgtD 1;
BA_ "SignalType" SG_ 1580 VectraSpcNWMgtD "UNM";
BA_ "SignalLongName" SG_ 1580 VectraSpcNWMgtD "Vectra Specific Network Management Data";
BA_ "VNSigDiagnostic" SG_ 1580 VectraSpcNWMgtD 1;
BA_ "VNSigAllNodes" SG_ 1580 VectraSpcNWMgtD 1;
BA_ "VNSigPrimaryTriggering" SG_ 1584 VectraSpcNWMgtD 1;
BA_ "VNSigRemoteDiagnostics" SG_ 1584 VectraSpcNWMgtD 1;
BA_ "VNSigInfotainment" SG_ 1584 VectraSpcNWMgtD 1;
BA_ "VNSigParkedVehicle" SG_ 1584 VectraSpcNWMgtD 1;
BA_ "VNSigIntermediate" SG_ 1584 VectraSpcNWMgtD 1;
BA_ "VNSigUnused_4" SG_ 1584 VectraSpcNWMgtD 1;
BA_ "SignalType" SG_ 1584 VectraSpcNWMgtD "UNM";
BA_ "SignalLongName" SG_ 1584 VectraSpcNWMgtD "Vectra Specific Network Management Data";
BA_ "VNSigDiagnostic" SG_ 1584 VectraSpcNWMgtD 1;
BA_ "VNSigAllNodes" SG_ 1584 VectraSpcNWMgtD 1;
BA_ "VNSigPrimaryTriggering" SG_ 1569 VectraSpcNWMgtD 1;
BA_ "VNSigRemoteDiagnostics" SG_ 1569 VectraSpcNWMgtD 1;
BA_ "VNSigInfotainment" SG_ 1569 VectraSpcNWMgtD 1;
BA_ "VNSigParkedVehicle" SG_ 1569 VectraSpcNWMgtD 1;
BA_ "VNSigIntermediate" SG_ 1569 VectraSpcNWMgtD 1;
BA_ "VNSigUnused_4" SG_ 1569 VectraSpcNWMgtD 1;
BA_ "SignalType" SG_ 1569 VectraSpcNWMgtD "UNM";
BA_ "SignalLongName" SG_ 1569 VectraSpcNWMgtD "Vectra Specific Network Management Data";
BA_ "VNSigDiagnostic" SG_ 1569 VectraSpcNWMgtD 1;
BA_ "VNSigAllNodes" SG_ 1569 VectraSpcNWMgtD 1;
BA_ "VNSigPrimaryTriggering" SG_ 1573 VectraSpcNWMgtD 1;
BA_ "VNSigRemoteDiagnostics" SG_ 1573 VectraSpcNWMgtD 1;
BA_ "VNSigInfotainment" SG_ 1573 VectraSpcNWMgtD 1;
BA_ "VNSigParkedVehicle" SG_ 1573 VectraSpcNWMgtD 1;
BA_ "VNSigIntermediate" SG_ 1573 VectraSpcNWMgtD 1;
BA_ "VNSigUnused_4" SG_ 1573 VectraSpcNWMgtD 1;
BA_ "SignalType" SG_ 1573 VectraSpcNWMgtD "UNM";
BA_ "SignalLongName" SG_ 1573 VectraSpcNWMgtD "Vectra Specific Network Management Data";
BA_ "VNSigDiagnostic" SG_ 1573 VectraSpcNWMgtD 1;
BA_ "VNSigAllNodes" SG_ 1573 VectraSpcNWMgtD 1;
BA_ "VNSigPrimaryTriggering" SG_ 1588 VectraSpcNWMgtD 1;
BA_ "VNSigRemoteDiagnostics" SG_ 1588 VectraSpcNWMgtD 1;
BA_ "VNSigInfotainment" SG_ 1588 VectraSpcNWMgtD 1;
BA_ "VNSigParkedVehicle" SG_ 1588 VectraSpcNWMgtD 1;
BA_ "VNSigIntermediate" SG_ 1588 VectraSpcNWMgtD 1;
BA_ "VNSigUnused_4" SG_ 1588 VectraSpcNWMgtD 1;
BA_ "SignalType" SG_ 1588 VectraSpcNWMgtD "UNM";
BA_ "SignalLongName" SG_ 1588 VectraSpcNWMgtD "Vectra Specific Network Management Data";
BA_ "VNSigDiagnostic" SG_ 1588 VectraSpcNWMgtD 1;
BA_ "VNSigAllNodes" SG_ 1588 VectraSpcNWMgtD 1;
BA_ "GenSigSendType" SG_ 2150137856 LMTTCPrsnOffStat 10;
BA_ "SignalType" SG_ 2150137856 LMTTCPrsnOffStat "BLN";
BA_ "SignalLongName" SG_ 2150137856 LMTTCPrsnOffStat "Lead Me To The Car Personalization Off Status";
BA_ "VNSigAllNodes" SG_ 2150137856 LMTTCPrsnOffStat 1;
BA_ "GenSigSendType" SG_ 2150137856 FldTpMotReq 10;
BA_ "SignalType" SG_ 2150137856 FldTpMotReq "ENM";
BA_ "SignalLongName" SG_ 2150137856 FldTpMotReq "Folding Top Motion Request";
BA_ "VNSigAllNodes" SG_ 2150137856 FldTpMotReq 1;
BA_ "GenSigSendType" SG_ 2150137856 KeyInWrnIO 10;
BA_ "GenSigSendOnInit" SG_ 2150137856 KeyInWrnIO 2;
BA_ "SignalType" SG_ 2150137856 KeyInWrnIO "BLN";
BA_ "SignalLongName" SG_ 2150137856 KeyInWrnIO "Key In Warning Indication On";
BA_ "VNSigAllNodes" SG_ 2150137856 KeyInWrnIO 1;
BA_ "GenSigSendType" SG_ 2150137856 FobPrevLrndIndOn 10;
BA_ "SignalType" SG_ 2150137856 FobPrevLrndIndOn "BLN";
BA_ "SignalLongName" SG_ 2150137856 FobPrevLrndIndOn "Fob Previously Learned Indication On";
BA_ "VNSigAllNodes" SG_ 2150137856 FobPrevLrndIndOn 1;
BA_ "GenSigSendType" SG_ 2150137856 RemCtrlFobNumForProgER 10;
BA_ "SignalType" SG_ 2150137856 RemCtrlFobNumForProgER "ENM";
BA_ "SignalLongName" SG_ 2150137856 RemCtrlFobNumForProgER "Remote Control Fob Number For Programming Extended Range";
BA_ "VNSigAllNodes" SG_ 2150137856 RemCtrlFobNumForProgER 1;
BA_ "GenSigSendType" SG_ 2150137856 FbProgCustActRqd 10;
BA_ "SignalType" SG_ 2150137856 FbProgCustActRqd "BLN";
BA_ "SignalLongName" SG_ 2150137856 FbProgCustActRqd "Fob Programming Customer Action Required";
BA_ "VNSigAllNodes" SG_ 2150137856 FbProgCustActRqd 1;
BA_ "GenSigSendType" SG_ 2150137856 Ky_IdDevNotPrIO 10;
BA_ "GenSigSendOnInit" SG_ 2150137856 Ky_IdDevNotPrIO 2;
BA_ "SignalType" SG_ 2150137856 Ky_IdDevNotPrIO "BLN";
BA_ "SignalLongName" SG_ 2150137856 Ky_IdDevNotPrIO "Key/Identification Device Not Present Indication On";
BA_ "VNSigAllNodes" SG_ 2150137856 Ky_IdDevNotPrIO 1;
BA_ "GenSigDeltaValue" SG_ 2150137856 VehSecAtoLrnDlyTmr 1;
BA_ "GenSigSendType" SG_ 2150137856 VehSecAtoLrnDlyTmr 12;
BA_ "SignalType" SG_ 2150137856 VehSecAtoLrnDlyTmr "UNM";
BA_ "SignalLongName" SG_ 2150137856 VehSecAtoLrnDlyTmr "Vehicle Security Auto Learn Delay Timer";
BA_ "VNSigAllNodes" SG_ 2150137856 VehSecAtoLrnDlyTmr 1;
BA_ "GenSigSendType" SG_ 2150137856 VehSecAtoLrnAtv 10;
BA_ "SignalType" SG_ 2150137856 VehSecAtoLrnAtv "BLN";
BA_ "SignalLongName" SG_ 2150137856 VehSecAtoLrnAtv "Vehicle Security Auto Learn Active";
BA_ "VNSigAllNodes" SG_ 2150137856 VehSecAtoLrnAtv 1;
BA_ "GenSigSendType" SG_ 2150137856 Ky_IdDevPrgmAuthReq 10;
BA_ "SignalType" SG_ 2150137856 Ky_IdDevPrgmAuthReq "BLN";
BA_ "SignalLongName" SG_ 2150137856 Ky_IdDevPrgmAuthReq "Key / Identification Device Programming Authentication Requested";
BA_ "VNSigAllNodes" SG_ 2150137856 Ky_IdDevPrgmAuthReq 1;
BA_ "GenSigSendType" SG_ 2151677952 SndLocRtRr 10;
BA_ "VNSigInfotainment" SG_ 2151677952 SndLocRtRr 1;
BA_ "VNSigIntermediate" SG_ 2151677952 SndLocRtRr 1;
BA_ "SignalType" SG_ 2151677952 SndLocRtRr "BLN";
BA_ "PacketOrder" SG_ 2151677952 SndLocRtRr 4;
BA_ "SignalLongName" SG_ 2151677952 SndLocRtRr "Sound Location : Right Rear";
BA_ "VNSigAllNodes" SG_ 2151677952 SndLocRtRr 1;
BA_ "GenSigSendType" SG_ 2151677952 SndLocLftRr 10;
BA_ "VNSigInfotainment" SG_ 2151677952 SndLocLftRr 1;
BA_ "VNSigIntermediate" SG_ 2151677952 SndLocLftRr 1;
BA_ "SignalType" SG_ 2151677952 SndLocLftRr "BLN";
BA_ "PacketOrder" SG_ 2151677952 SndLocLftRr 3;
BA_ "SignalLongName" SG_ 2151677952 SndLocLftRr "Sound Location : Left Rear";
BA_ "VNSigAllNodes" SG_ 2151677952 SndLocLftRr 1;
BA_ "GenSigSendType" SG_ 2151677952 SndLocPasFr 10;
BA_ "VNSigInfotainment" SG_ 2151677952 SndLocPasFr 1;
BA_ "VNSigIntermediate" SG_ 2151677952 SndLocPasFr 1;
BA_ "SignalType" SG_ 2151677952 SndLocPasFr "BLN";
BA_ "PacketOrder" SG_ 2151677952 SndLocPasFr 2;
BA_ "SignalLongName" SG_ 2151677952 SndLocPasFr "Sound Location : Passenger Front";
BA_ "VNSigAllNodes" SG_ 2151677952 SndLocPasFr 1;
BA_ "GenSigSendType" SG_ 2151677952 SndLocDrFr 10;
BA_ "VNSigInfotainment" SG_ 2151677952 SndLocDrFr 1;
BA_ "VNSigIntermediate" SG_ 2151677952 SndLocDrFr 1;
BA_ "SignalType" SG_ 2151677952 SndLocDrFr "BLN";
BA_ "PacketOrder" SG_ 2151677952 SndLocDrFr 1;
BA_ "SignalLongName" SG_ 2151677952 SndLocDrFr "Sound Location : Driver Front";
BA_ "VNSigAllNodes" SG_ 2151677952 SndLocDrFr 1;
BA_ "GenSigDeltaValue" SG_ 2151677952 SC_SndDutCyc 1;
BA_ "GenSigSendType" SG_ 2151677952 SC_SndDutCyc 12;
BA_ "VNSigInfotainment" SG_ 2151677952 SC_SndDutCyc 1;
BA_ "VNSigIntermediate" SG_ 2151677952 SC_SndDutCyc 1;
BA_ "SignalType" SG_ 2151677952 SC_SndDutCyc "UNM";
BA_ "PacketOrder" SG_ 2151677952 SC_SndDutCyc 4;
BA_ "SignalLongName" SG_ 2151677952 SC_SndDutCyc "Sound Characteristics : Sound Duty Cycle";
BA_ "VNSigAllNodes" SG_ 2151677952 SC_SndDutCyc 1;
BA_ "GenSigDeltaValue" SG_ 2151677952 SC_NmofRp 1;
BA_ "GenSigSendType" SG_ 2151677952 SC_NmofRp 12;
BA_ "VNSigInfotainment" SG_ 2151677952 SC_NmofRp 1;
BA_ "VNSigIntermediate" SG_ 2151677952 SC_NmofRp 1;
BA_ "SignalType" SG_ 2151677952 SC_NmofRp "UNM";
BA_ "PacketOrder" SG_ 2151677952 SC_NmofRp 3;
BA_ "SignalLongName" SG_ 2151677952 SC_NmofRp "Sound Characteristics : Number of Repetitions";
BA_ "VNSigAllNodes" SG_ 2151677952 SC_NmofRp 1;
BA_ "GenSigDeltaValue" SG_ 2151677952 SC_SndCdnPrd 1;
BA_ "GenSigSendType" SG_ 2151677952 SC_SndCdnPrd 12;
BA_ "VNSigInfotainment" SG_ 2151677952 SC_SndCdnPrd 1;
BA_ "VNSigIntermediate" SG_ 2151677952 SC_SndCdnPrd 1;
BA_ "SignalType" SG_ 2151677952 SC_SndCdnPrd "UNM";
BA_ "PacketOrder" SG_ 2151677952 SC_SndCdnPrd 2;
BA_ "SignalLongName" SG_ 2151677952 SC_SndCdnPrd "Sound Characteristics : Sound Cadence Period";
BA_ "VNSigAllNodes" SG_ 2151677952 SC_SndCdnPrd 1;
BA_ "GenSigSendType" SG_ 2151677952 SC_SndTne 10;
BA_ "VNSigInfotainment" SG_ 2151677952 SC_SndTne 1;
BA_ "VNSigIntermediate" SG_ 2151677952 SC_SndTne 1;
BA_ "SignalType" SG_ 2151677952 SC_SndTne "ENM";
BA_ "PacketOrder" SG_ 2151677952 SC_SndTne 1;
BA_ "SignalLongName" SG_ 2151677952 SC_SndTne "Sound Characteristics : Sound Tone";
BA_ "VNSigAllNodes" SG_ 2151677952 SC_SndTne 1;
BA_ "GenSigDeltaValue" SG_ 2151677952 SndPriority 1;
BA_ "GenSigSendType" SG_ 2151677952 SndPriority 12;
BA_ "VNSigInfotainment" SG_ 2151677952 SndPriority 1;
BA_ "VNSigIntermediate" SG_ 2151677952 SndPriority 1;
BA_ "SignalType" SG_ 2151677952 SndPriority "UNM";
BA_ "SignalLongName" SG_ 2151677952 SndPriority "Sound Priority";
BA_ "VNSigAllNodes" SG_ 2151677952 SndPriority 1;
BA_ "GenSigSendType" SG_ 2150776832 HybImpSnsDsbld 10;
BA_ "SignalType" SG_ 2150776832 HybImpSnsDsbld "BLN";
BA_ "SignalLongName" SG_ 2150776832 HybImpSnsDsbld "Hybrid Impact Sensing Disabled";
BA_ "VNSigAllNodes" SG_ 2150776832 HybImpSnsDsbld 1;
BA_ "GenSigSendType" SG_ 2150776832 SftyMuteRd 10;
BA_ "GenSigSendOnInit" SG_ 2150776832 SftyMuteRd 1;
BA_ "SignalType" SG_ 2150776832 SftyMuteRd "BLN";
BA_ "SignalLongName" SG_ 2150776832 SftyMuteRd "Safety Mute Requested";
BA_ "VNSigAllNodes" SG_ 2150776832 SftyMuteRd 1;
BA_ "GenSigSendType" SG_ 2150776832 HybVehHiVltInvDisRqd 10;
BA_ "SignalType" SG_ 2150776832 HybVehHiVltInvDisRqd "BLN";
BA_ "SignalLongName" SG_ 2150776832 HybVehHiVltInvDisRqd "Hybrid Vehicle High Voltage Inverter Disable Requested";
BA_ "VNSigAllNodes" SG_ 2150776832 HybVehHiVltInvDisRqd 1;
BA_ "GenSigSendType" SG_ 2150776832 EvntEnbld 10;
BA_ "SignalType" SG_ 2150776832 EvntEnbld "BLN";
BA_ "SignalLongName" SG_ 2150776832 EvntEnbld "Event Enabled";
BA_ "VNSigAllNodes" SG_ 2150776832 EvntEnbld 1;
BA_ "GenSigSendType" SG_ 2150776832 ShfUlkBrToShftIndCtrl 10;
BA_ "SignalType" SG_ 2150776832 ShfUlkBrToShftIndCtrl "BLN";
BA_ "SignalLongName" SG_ 2150776832 ShfUlkBrToShftIndCtrl "Shifter Unlocked Brake To Shift Indication Control";
BA_ "VNSigAllNodes" SG_ 2150776832 ShfUlkBrToShftIndCtrl 1;
BA_ "GenSigSendType" SG_ 2150776832 ShftLkdBuStbltIndCtrl 10;
BA_ "SignalType" SG_ 2150776832 ShftLkdBuStbltIndCtrl "BLN";
BA_ "SignalLongName" SG_ 2150776832 ShftLkdBuStbltIndCtrl "Shifter Locked Buckle Seatbelts Indication Control";
BA_ "VNSigAllNodes" SG_ 2150776832 ShftLkdBuStbltIndCtrl 1;
BA_ "GenSigSendType" SG_ 2150776832 SbItlkTrnsShftLvLkRd 10;
BA_ "SignalType" SG_ 2150776832 SbItlkTrnsShftLvLkRd "BLN";
BA_ "SignalLongName" SG_ 2150776832 SbItlkTrnsShftLvLkRd "Seatbelt Interlock Transmission Shift Lever Lock Requested";
BA_ "VNSigAllNodes" SG_ 2150776832 SbItlkTrnsShftLvLkRd 1;
BA_ "GenSigSendType" SG_ 2150776832 FrPsngrStOccSnsngPriDat 10;
BA_ "SignalType" SG_ 2150776832 FrPsngrStOccSnsngPriDat "BCD";
BA_ "SignalLongName" SG_ 2150776832 FrPsngrStOccSnsngPriDat "Front Passenger Seat Occupancy Sensing Primary Data";
BA_ "VNSigAllNodes" SG_ 2150776832 FrPsngrStOccSnsngPriDat 1;
BA_ "GenSigSendType" SG_ 2150776832 MmryRclImpctDisRq 10;
BA_ "GenSigSendOnInit" SG_ 2150776832 MmryRclImpctDisRq 1;
BA_ "VNSigPrimaryTriggering" SG_ 2150776832 MmryRclImpctDisRq 1;
BA_ "SignalType" SG_ 2150776832 MmryRclImpctDisRq "ENM";
BA_ "SignalLongName" SG_ 2150776832 MmryRclImpctDisRq "Memory Recall Impact Disable Request";
BA_ "VNSigAllNodes" SG_ 2150776832 MmryRclImpctDisRq 1;
BA_ "GenSigDeltaValue" SG_ 2150776832 SIREvntSychCntr 1;
BA_ "GenSigSendType" SG_ 2150776832 SIREvntSychCntr 12;
BA_ "GenSigSendOnInit" SG_ 2150776832 SIREvntSychCntr 1;
BA_ "SignalType" SG_ 2150776832 SIREvntSychCntr "UNM";
BA_ "SignalLongName" SG_ 2150776832 SIREvntSychCntr "Supplemental Inflatable Restraint Event Synchronization Counter";
BA_ "VNSigAllNodes" SG_ 2150776832 SIREvntSychCntr 1;
BA_ "GenSigSendType" SG_ 2150760448 NotSndRwRtSeatStat 10;
BA_ "SignalType" SG_ 2150760448 NotSndRwRtSeatStat "ENM";
BA_ "SignalLongName" SG_ 2150760448 NotSndRwRtSeatStat "Notification Second Row Right Seatbelt Status";
BA_ "VNSigAllNodes" SG_ 2150760448 NotSndRwRtSeatStat 1;
BA_ "GenSigSendType" SG_ 2150760448 NotSndRwMdlSeatStat 10;
BA_ "SignalType" SG_ 2150760448 NotSndRwMdlSeatStat "ENM";
BA_ "SignalLongName" SG_ 2150760448 NotSndRwMdlSeatStat "Notification Second Row Middle Seatbelt Status";
BA_ "VNSigAllNodes" SG_ 2150760448 NotSndRwMdlSeatStat 1;
BA_ "GenSigSendType" SG_ 2150760448 NotSndRwLtSeatStat 10;
BA_ "SignalType" SG_ 2150760448 NotSndRwLtSeatStat "ENM";
BA_ "SignalLongName" SG_ 2150760448 NotSndRwLtSeatStat "Notification Second Row Left Seatbelt Status";
BA_ "VNSigAllNodes" SG_ 2150760448 NotSndRwLtSeatStat 1;
BA_ "GenSigSendType" SG_ 2150760448 NotPsSeatStat 10;
BA_ "SignalType" SG_ 2150760448 NotPsSeatStat "ENM";
BA_ "SignalLongName" SG_ 2150760448 NotPsSeatStat "Notification Passenger Seatbelt Status";
BA_ "VNSigAllNodes" SG_ 2150760448 NotPsSeatStat 1;
BA_ "GenSigSendType" SG_ 2150760448 NotDrvSeatStat 10;
BA_ "SignalType" SG_ 2150760448 NotDrvSeatStat "ENM";
BA_ "SignalLongName" SG_ 2150760448 NotDrvSeatStat "Notification Driver Seatbelt Status";
BA_ "VNSigAllNodes" SG_ 2150760448 NotDrvSeatStat 1;
BA_ "GenSigSendType" SG_ 2150760448 NotSecRowRtSeaOccStat 10;
BA_ "VNSigPrimaryTriggering" SG_ 2150760448 NotSecRowRtSeaOccStat 1;
BA_ "SignalType" SG_ 2150760448 NotSecRowRtSeaOccStat "ENM";
BA_ "SignalLongName" SG_ 2150760448 NotSecRowRtSeaOccStat "Notification Second Row Right Seat Occupancy Status";
BA_ "VNSigAllNodes" SG_ 2150760448 NotSecRowRtSeaOccStat 1;
BA_ "GenSigSendType" SG_ 2150760448 NotSecRowLeSeaOccStat 10;
BA_ "VNSigPrimaryTriggering" SG_ 2150760448 NotSecRowLeSeaOccStat 1;
BA_ "SignalType" SG_ 2150760448 NotSecRowLeSeaOccStat "ENM";
BA_ "SignalLongName" SG_ 2150760448 NotSecRowLeSeaOccStat "Notification Second Row Left Seat Occupancy Status";
BA_ "VNSigAllNodes" SG_ 2150760448 NotSecRowLeSeaOccStat 1;
BA_ "GenSigSendType" SG_ 2150760448 NotSecRowCtSeaOccStat 10;
BA_ "VNSigPrimaryTriggering" SG_ 2150760448 NotSecRowCtSeaOccStat 1;
BA_ "SignalType" SG_ 2150760448 NotSecRowCtSeaOccStat "ENM";
BA_ "SignalLongName" SG_ 2150760448 NotSecRowCtSeaOccStat "Notification Second Row Center Seat Occupancy Status";
BA_ "VNSigAllNodes" SG_ 2150760448 NotSecRowCtSeaOccStat 1;
BA_ "GenSigSendType" SG_ 2150760448 NotiFrntPasSeatOccSta 10;
BA_ "VNSigPrimaryTriggering" SG_ 2150760448 NotiFrntPasSeatOccSta 1;
BA_ "SignalType" SG_ 2150760448 NotiFrntPasSeatOccSta "ENM";
BA_ "SignalLongName" SG_ 2150760448 NotiFrntPasSeatOccSta "Notification Front Passenger Seat Occupancy Status";
BA_ "VNSigAllNodes" SG_ 2150760448 NotiFrntPasSeatOccSta 1;
BA_ "GenSigSendType" SG_ 2150760448 NotEventStat 10;
BA_ "VNSigPrimaryTriggering" SG_ 2150760448 NotEventStat 1;
BA_ "SignalType" SG_ 2150760448 NotEventStat "ENM";
BA_ "SignalLongName" SG_ 2150760448 NotEventStat "Notification Event Status";
BA_ "VNSigAllNodes" SG_ 2150760448 NotEventStat 1;
BA_ "GenSigDeltaValue" SG_ 2150760448 NotiEventCount 1;
BA_ "GenSigSendType" SG_ 2150760448 NotiEventCount 12;
BA_ "VNSigPrimaryTriggering" SG_ 2150760448 NotiEventCount 1;
BA_ "SignalType" SG_ 2150760448 NotiEventCount "UNM";
BA_ "SignalLongName" SG_ 2150760448 NotiEventCount "Notification Event Counter";
BA_ "VNSigAllNodes" SG_ 2150760448 NotiEventCount 1;
BA_ "GenSigSendType" SG_ 2150760448 NESSRoSevSt 10;
BA_ "VNSigPrimaryTriggering" SG_ 2150760448 NESSRoSevSt 1;
BA_ "SignalType" SG_ 2150760448 NESSRoSevSt "BLN";
BA_ "PacketOrder" SG_ 2150760448 NESSRoSevSt 7;
BA_ "SignalLongName" SG_ 2150760448 NESSRoSevSt "Notification Event Severity Status : Rollover Severity Achieved";
BA_ "VNSigAllNodes" SG_ 2150760448 NESSRoSevSt 1;
BA_ "GenSigSendType" SG_ 2150760448 NESSRiSiSevSt 10;
BA_ "VNSigPrimaryTriggering" SG_ 2150760448 NESSRiSiSevSt 1;
BA_ "SignalType" SG_ 2150760448 NESSRiSiSevSt "BLN";
BA_ "PacketOrder" SG_ 2150760448 NESSRiSiSevSt 6;
BA_ "SignalLongName" SG_ 2150760448 NESSRiSiSevSt "Notification Event Severity Status : Right Side Severity Achieved";
BA_ "VNSigAllNodes" SG_ 2150760448 NESSRiSiSevSt 1;
BA_ "GenSigSendType" SG_ 2150760448 NESSReImpSevSt 10;
BA_ "VNSigPrimaryTriggering" SG_ 2150760448 NESSReImpSevSt 1;
BA_ "SignalType" SG_ 2150760448 NESSReImpSevSt "BLN";
BA_ "PacketOrder" SG_ 2150760448 NESSReImpSevSt 5;
BA_ "SignalLongName" SG_ 2150760448 NESSReImpSevSt "Notification Event Severity Status : Rear Impact Severity Achieved";
BA_ "VNSigAllNodes" SG_ 2150760448 NESSReImpSevSt 1;
BA_ "GenSigSendType" SG_ 2150760448 NESSLeSiSevSt 10;
BA_ "VNSigPrimaryTriggering" SG_ 2150760448 NESSLeSiSevSt 1;
BA_ "SignalType" SG_ 2150760448 NESSLeSiSevSt "BLN";
BA_ "PacketOrder" SG_ 2150760448 NESSLeSiSevSt 4;
BA_ "SignalLongName" SG_ 2150760448 NESSLeSiSevSt "Notification Event Severity Status : Left Side Severity Achieved";
BA_ "VNSigAllNodes" SG_ 2150760448 NESSLeSiSevSt 1;
BA_ "GenSigSendType" SG_ 2150760448 NESSFrImpSt2SevSt 10;
BA_ "VNSigPrimaryTriggering" SG_ 2150760448 NESSFrImpSt2SevSt 1;
BA_ "SignalType" SG_ 2150760448 NESSFrImpSt2SevSt "BLN";
BA_ "PacketOrder" SG_ 2150760448 NESSFrImpSt2SevSt 3;
BA_ "SignalLongName" SG_ 2150760448 NESSFrImpSt2SevSt "Notification Event Severity Status : Frontal Impact Stage 2 Severity Achieved";
BA_ "VNSigAllNodes" SG_ 2150760448 NESSFrImpSt2SevSt 1;
BA_ "GenSigSendType" SG_ 2150760448 NESSFrImpSt1SevSt 10;
BA_ "VNSigPrimaryTriggering" SG_ 2150760448 NESSFrImpSt1SevSt 1;
BA_ "SignalType" SG_ 2150760448 NESSFrImpSt1SevSt "BLN";
BA_ "PacketOrder" SG_ 2150760448 NESSFrImpSt1SevSt 2;
BA_ "SignalLongName" SG_ 2150760448 NESSFrImpSt1SevSt "Notification Event Severity Status : Frontal Impact Stage 1 Severity Achieved";
BA_ "VNSigAllNodes" SG_ 2150760448 NESSFrImpSt1SevSt 1;
BA_ "GenSigSendType" SG_ 2150760448 NESSFrImpPreSevSt 10;
BA_ "VNSigPrimaryTriggering" SG_ 2150760448 NESSFrImpPreSevSt 1;
BA_ "SignalType" SG_ 2150760448 NESSFrImpPreSevSt "BLN";
BA_ "PacketOrder" SG_ 2150760448 NESSFrImpPreSevSt 1;
BA_ "SignalLongName" SG_ 2150760448 NESSFrImpPreSevSt "Notification Event Severity Status : Frontal Impact Pretensioner Severity Achieved";
BA_ "VNSigAllNodes" SG_ 2150760448 NESSFrImpPreSevSt 1;
BA_ "GenSigSendType" SG_ 2150760448 NEDLSRtSdArbgDld 10;
BA_ "VNSigPrimaryTriggering" SG_ 2150760448 NEDLSRtSdArbgDld 1;
BA_ "SignalType" SG_ 2150760448 NEDLSRtSdArbgDld "BLN";
BA_ "PacketOrder" SG_ 2150760448 NEDLSRtSdArbgDld 6;
BA_ "SignalLongName" SG_ 2150760448 NEDLSRtSdArbgDld "Notification Event Deployed Loop Status : Right Side Airbag Deployed";
BA_ "VNSigAllNodes" SG_ 2150760448 NEDLSRtSdArbgDld 1;
BA_ "GenSigSendType" SG_ 2150760448 NEDLSLtSdArbgDld 10;
BA_ "VNSigPrimaryTriggering" SG_ 2150760448 NEDLSLtSdArbgDld 1;
BA_ "SignalType" SG_ 2150760448 NEDLSLtSdArbgDld "BLN";
BA_ "PacketOrder" SG_ 2150760448 NEDLSLtSdArbgDld 5;
BA_ "SignalLongName" SG_ 2150760448 NEDLSLtSdArbgDld "Notification Event Deployed Loop Status : Left Side Airbag Deployed";
BA_ "VNSigAllNodes" SG_ 2150760448 NEDLSLtSdArbgDld 1;
BA_ "GenSigSendType" SG_ 2150760448 NEDLSSdCrtnArbgDpld 10;
BA_ "VNSigPrimaryTriggering" SG_ 2150760448 NEDLSSdCrtnArbgDpld 1;
BA_ "SignalType" SG_ 2150760448 NEDLSSdCrtnArbgDpld "BLN";
BA_ "PacketOrder" SG_ 2150760448 NEDLSSdCrtnArbgDpld 7;
BA_ "SignalLongName" SG_ 2150760448 NEDLSSdCrtnArbgDpld "Notification Event Deployed Loop Status : Side Curtain Airbag Deployed";
BA_ "VNSigAllNodes" SG_ 2150760448 NEDLSSdCrtnArbgDpld 1;
BA_ "GenSigSendType" SG_ 2150760448 NEDLSPaFrSt2De 10;
BA_ "VNSigPrimaryTriggering" SG_ 2150760448 NEDLSPaFrSt2De 1;
BA_ "SignalType" SG_ 2150760448 NEDLSPaFrSt2De "BLN";
BA_ "PacketOrder" SG_ 2150760448 NEDLSPaFrSt2De 4;
BA_ "SignalLongName" SG_ 2150760448 NEDLSPaFrSt2De "Notification Event Deployed Loop Status : Passenger Front Stage 2 Deployed";
BA_ "VNSigAllNodes" SG_ 2150760448 NEDLSPaFrSt2De 1;
BA_ "GenSigSendType" SG_ 2150760448 NEDLSPaFrSt1De 10;
BA_ "VNSigPrimaryTriggering" SG_ 2150760448 NEDLSPaFrSt1De 1;
BA_ "SignalType" SG_ 2150760448 NEDLSPaFrSt1De "BLN";
BA_ "PacketOrder" SG_ 2150760448 NEDLSPaFrSt1De 3;
BA_ "SignalLongName" SG_ 2150760448 NEDLSPaFrSt1De "Notification Event Deployed Loop Status : Passenger Front Stage 1 Deployed";
BA_ "VNSigAllNodes" SG_ 2150760448 NEDLSPaFrSt1De 1;
BA_ "GenSigSendType" SG_ 2150760448 NEDLSDrFrSt2De 10;
BA_ "VNSigPrimaryTriggering" SG_ 2150760448 NEDLSDrFrSt2De 1;
BA_ "SignalType" SG_ 2150760448 NEDLSDrFrSt2De "BLN";
BA_ "PacketOrder" SG_ 2150760448 NEDLSDrFrSt2De 2;
BA_ "SignalLongName" SG_ 2150760448 NEDLSDrFrSt2De "Notification Event Deployed Loop Status : Driver Front Stage 2 Deployed";
BA_ "VNSigAllNodes" SG_ 2150760448 NEDLSDrFrSt2De 1;
BA_ "GenSigSendType" SG_ 2150760448 NEDLSDrFrSt1De 10;
BA_ "VNSigPrimaryTriggering" SG_ 2150760448 NEDLSDrFrSt1De 1;
BA_ "SignalType" SG_ 2150760448 NEDLSDrFrSt1De "BLN";
BA_ "PacketOrder" SG_ 2150760448 NEDLSDrFrSt1De 1;
BA_ "SignalLongName" SG_ 2150760448 NEDLSDrFrSt1De "Notification Event Deployed Loop Status : Driver Front Stage 1 Deployed";
BA_ "VNSigAllNodes" SG_ 2150760448 NEDLSDrFrSt1De 1;
BA_ "GenSigSendType" SG_ 2150760448 SIRDpl 10;
BA_ "GenSigSendOnInit" SG_ 2150760448 SIRDpl 2;
BA_ "VNSigPrimaryTriggering" SG_ 2150760448 SIRDpl 1;
BA_ "SignalType" SG_ 2150760448 SIRDpl "BLN";
BA_ "SignalLongName" SG_ 2150760448 SIRDpl "Airbag Deployed";
BA_ "VNSigAllNodes" SG_ 2150760448 SIRDpl 1;
BA_ "SignalType" SG_ 2155872256 DrvStyPerfMdCsCrStVal "ENM";
BA_ "SignalLongName" SG_ 2155872256 DrvStyPerfMdCsCrStVal "Driving Style Performance Mode Customization Current Setting Value";
BA_ "VNSigAllNodes" SG_ 2155872256 DrvStyPerfMdCsCrStVal 1;
BA_ "SignalType" SG_ 2155872256 DrvStyPerfMdCsStAvl "BLN";
BA_ "SignalLongName" SG_ 2155872256 DrvStyPerfMdCsStAvl "Driving Style Performance Mode Customization Setting Available";
BA_ "VNSigAllNodes" SG_ 2155872256 DrvStyPerfMdCsStAvl 1;
BA_ "SignalType" SG_ 2155872256 VehPitchAngleV "ENM";
BA_ "SignalLongName" SG_ 2155872256 VehPitchAngleV "Vehicle Pitch Angle Validity";
BA_ "VNSigAllNodes" SG_ 2155872256 VehPitchAngleV 1;
BA_ "SignalType" SG_ 2155872256 VehPitchAngle "UNM";
BA_ "SignalLongName" SG_ 2155872256 VehPitchAngle "Vehicle Pitch Angle";
BA_ "VNSigAllNodes" SG_ 2155872256 VehPitchAngle 1;
BA_ "SignalType" SG_ 2155872256 RdWhlAngV "ENM";
BA_ "SignalLongName" SG_ 2155872256 RdWhlAngV "Road Wheel Angle Validity";
BA_ "VNSigAllNodes" SG_ 2155872256 RdWhlAngV 1;
BA_ "SignalType" SG_ 2155872256 RdWhlAng "UNM";
BA_ "SignalLongName" SG_ 2155872256 RdWhlAng "Road Wheel Angle";
BA_ "VNSigAllNodes" SG_ 2155872256 RdWhlAng 1;
BA_ "SignalType" SG_ 2155872256 FuelFltChgNwIO "BLN";
BA_ "SignalLongName" SG_ 2155872256 FuelFltChgNwIO "Fuel Filter Change Now Indication On";
BA_ "VNSigAllNodes" SG_ 2155872256 FuelFltChgNwIO 1;
BA_ "GenSigSendOnInit" SG_ 2155872256 FlLvlPctV 1;
BA_ "SignalType" SG_ 2155872256 FlLvlPctV "ENM";
BA_ "SignalLongName" SG_ 2155872256 FlLvlPctV "Fuel Level Percent Validity";
BA_ "VNSigAllNodes" SG_ 2155872256 FlLvlPctV 1;
BA_ "GenSigDeltaValue" SG_ 2155872256 FlLvlPct 2;
BA_ "GenSigSendOnInit" SG_ 2155872256 FlLvlPct 1;
BA_ "SignalType" SG_ 2155872256 FlLvlPct "UNM";
BA_ "SignalLongName" SG_ 2155872256 FlLvlPct "Fuel Level Percent";
BA_ "VNSigAllNodes" SG_ 2155872256 FlLvlPct 1;
BA_ "SignalType" SG_ 2155872256 FlInjRlCtRstOcc "BLN";
BA_ "SignalLongName" SG_ 2155872256 FlInjRlCtRstOcc "Fuel Injected Rolling Count Reset Occurred";
BA_ "VNSigAllNodes" SG_ 2155872256 FlInjRlCtRstOcc 1;
BA_ "SignalType" SG_ 2155872256 FlInjRlCt "UNM";
BA_ "SignalLongName" SG_ 2155872256 FlInjRlCt "Fuel Injected Rolling Count";
BA_ "VNSigAllNodes" SG_ 2155872256 FlInjRlCt 1;
BA_ "GenSigSendType" SG_ 2156175360 NtVsnSysEnbld 10;
BA_ "SignalType" SG_ 2156175360 NtVsnSysEnbld "BLN";
BA_ "SignalLongName" SG_ 2156175360 NtVsnSysEnbld "Night Vision System Enabled";
BA_ "VNSigAllNodes" SG_ 2156175360 NtVsnSysEnbld 1;
BA_ "GenSigSendType" SG_ 2156175360 DispMeasSysExt 10;
BA_ "GenSigSendOnInit" SG_ 2156175360 DispMeasSysExt 1;
BA_ "VNSigInfotainment" SG_ 2156175360 DispMeasSysExt 1;
BA_ "SignalType" SG_ 2156175360 DispMeasSysExt "ENM";
BA_ "SignalLongName" SG_ 2156175360 DispMeasSysExt "Display Measurement System Extended";
BA_ "VNSigAllNodes" SG_ 2156175360 DispMeasSysExt 1;
BA_ "GenSigSendType" SG_ 2156175360 DispMeasSys 10;
BA_ "GenSigSendOnInit" SG_ 2156175360 DispMeasSys 1;
BA_ "SignalType" SG_ 2156175360 DispMeasSys "ENM";
BA_ "SignalLongName" SG_ 2156175360 DispMeasSys "Display Measurement System";
BA_ "VNSigAllNodes" SG_ 2156175360 DispMeasSys 1;
BA_REL_ "GenSigSuprvResp" BU_SG_REL_ PEPS_LS SG_ 2151235584 NmofPrgKFbExtd 1;
BA_REL_ "GenSigSuprvResp" BU_SG_REL_ IPC_LS SG_ 2151235584 VhSecNImmoIndRq 1;
BA_REL_ "GenSigSuprvResp" BU_SG_REL_ ECC_LS SG_ 2151202816 AuxHtrAlwd 1;
BA_REL_ "GenSigSuprvResp" BU_SG_REL_ ECC_LS SG_ 2151202816 IPSnsrTpCvrTempFltd 1;
BA_REL_ "GenSigSuprvResp" BU_SG_REL_ ECC_LS SG_ 2151202816 IPSnsrTpCvrTemp 1;
BA_REL_ "GenSigSuprvResp" BU_SG_REL_ ECC_LS SG_ 2151202816 IPSnsrSolrElvtnAngl 1;
BA_REL_ "GenSigSuprvResp" BU_SG_REL_ ECC_LS SG_ 2151202816 IPSnsrSolrAzmthAngl 1;
BA_REL_ "GenSigSuprvResp" BU_SG_REL_ ECC_LS SG_ 2151202816 IPSnsrSolrAnglFltd 1;
BA_REL_ "GenSigSuprvResp" BU_SG_REL_ ECC_LS SG_ 2151202816 IPSnsrRwSolrIntFltd 1;
BA_REL_ "GenSigSuprvResp" BU_SG_REL_ ECC_LS SG_ 2151202816 IPSnsrRwSolrInt 1;
BA_REL_ "GenSigSuprvResp" BU_SG_REL_ ECC_LS SG_ 2151202816 ILSSCommErr 1;
BA_REL_ "GenSigSuprvResp" BU_SG_REL_ IPC_LS SG_ 2150825984 PdstIntdProtSysDplyd 1;
BA_REL_ "GenSigSuprvResp" BU_SG_REL_ IPC_LS SG_ 2150825984 PdstIntdProtSysDsbld 1;
BA_REL_ "GenSigSuprvResp" BU_SG_REL_ IPC_LS SG_ 2150825984 SrvIntdPdstProtSysIO 1;
BA_REL_ "GenSigSuprvResp" BU_SG_REL_ V2V_LS SG_ 2150825984 FstnThrdRwCtPsStbtInR 1;
BA_REL_ "GenSigSuprvResp" BU_SG_REL_ V2V_LS SG_ 2150825984 FPSIC_IndPer 1;
BA_REL_ "GenSigSuprvResp" BU_SG_REL_ V2V_LS SG_ 2150825984 FPSIC_IO 1;
BA_REL_ "GenSigSuprvResp" BU_SG_REL_ V2V_LS SG_ 2150825984 FPSIC_IndDtCyc 1;
BA_REL_ "GenSigSuprvResp" BU_SG_REL_ V2V_LS SG_ 2150825984 FDSIC_IndPer 1;
BA_REL_ "GenSigSuprvResp" BU_SG_REL_ V2V_LS SG_ 2150825984 FDSIC_IO 1;
BA_REL_ "GenSigSuprvResp" BU_SG_REL_ V2V_LS SG_ 2150825984 FDSIC_IndDC 1;
BA_REL_ "GenSigSuprvResp" BU_SG_REL_ V2V_LS SG_ 2150825984 AirbgFldIO 1;
BA_REL_ "GenSigSuprvResp" BU_SG_REL_ IPC_LS SG_ 2150825984 AirbgFldIO 1;
BA_REL_ "GenSigSuprvResp" BU_SG_REL_ V2V_LS SG_ 2150825984 SndRwStbltRdIndMd 1;
BA_REL_ "GenSigSuprvResp" BU_SG_REL_ IPC_LS SG_ 2150825984 AirbgICIndPer 1;
BA_REL_ "GenSigSuprvResp" BU_SG_REL_ IPC_LS SG_ 2150825984 AirbgICDutCyc 1;
BA_REL_ "GenSigSuprvResp" BU_SG_REL_ IPC_LS SG_ 2150825984 AirbgICIO 1;
BA_REL_ "GenSigSuprvResp" BU_SG_REL_ V2V_LS SG_ 2150825984 FstnSndRwRtPsStbtInR 1;
BA_REL_ "GenSigSuprvResp" BU_SG_REL_ V2V_LS SG_ 2150825984 FstnSndRwLtPsStbtInR 1;
BA_REL_ "GenSigSuprvResp" BU_SG_REL_ PEPS_LS SG_ 2151759872 RrClsRelRq 1;
BA_REL_ "GenSigSuprvResp" BU_SG_REL_ ARB_LS SG_ 2151759872 CLRAF_UnandRsv3 1;
BA_REL_ "GenSigSuprvResp" BU_SG_REL_ ARB_LS SG_ 2151759872 CLRAF_UnandRsv2 1;
BA_REL_ "GenSigSuprvResp" BU_SG_REL_ ARB_LS SG_ 2151759872 CLRAF_UnandRsv1 1;
BA_REL_ "GenSigSuprvResp" BU_SG_REL_ ARB_LS SG_ 2151759872 CLRAF_Unl_Lk 1;
BA_REL_ "GenSigSuprvResp" BU_SG_REL_ ARB_LS SG_ 2151759872 CLRAF_RRD 1;
BA_REL_ "GenSigSuprvResp" BU_SG_REL_ ARB_LS SG_ 2151759872 CLRAF_RLD 1;
BA_REL_ "GenSigSuprvResp" BU_SG_REL_ ARB_LS SG_ 2151759872 CLRAF_RrCls 1;
BA_REL_ "GenSigSuprvResp" BU_SG_REL_ ARB_LS SG_ 2151759872 CLRAF_PD 1;
BA_REL_ "GenSigSuprvResp" BU_SG_REL_ ARB_LS SG_ 2151759872 CLRAF_Hd 1;
BA_REL_ "GenSigSuprvResp" BU_SG_REL_ ARB_LS SG_ 2151759872 CLRAF_FuelD 1;
BA_REL_ "GenSigSuprvResp" BU_SG_REL_ ARB_LS SG_ 2151759872 CLRAF_DD 1;
BA_REL_ "GenSigSuprvResp" BU_SG_REL_ ARB_LS SG_ 2151759872 CLRAF_ActFunc 1;
BA_REL_ "GenSigSuprvResp" BU_SG_REL_ VPM_LS SG_ 2149974016 AlrmStat 1;
BA_REL_ "GenSigSuprvResp" BU_SG_REL_ IPC_LS SG_ 2150268928 EmrgncyRspSysSrvIndOn 1;
BA_REL_ "GenSigSuprvResp" BU_SG_REL_ V2V_LS SG_ 2150268928 CldrYr_154 1;
BA_REL_ "GenSigSuprvResp" BU_SG_REL_ VPM_LS SG_ 2150268928 CldrYr_154 1;
BA_REL_ "GenSigSuprvResp" BU_SG_REL_ VIS2_LS SG_ 2150268928 CldrYr_154 1;
BA_REL_ "GenSigSuprvResp" BU_SG_REL_ FCM_LS SG_ 2150268928 CldrYr_154 1;
BA_REL_ "GenSigSuprvResp" BU_SG_REL_ BCM_LS SG_ 2150268928 CldrYr_154 1;
BA_REL_ "GenSigSuprvResp" BU_SG_REL_ EOCM_F_LS SG_ 2150268928 CldrYr_154 1;
BA_REL_ "GenSigSuprvResp" BU_SG_REL_ V2V_LS SG_ 2150268928 CldrMth_154 1;
BA_REL_ "GenSigSuprvResp" BU_SG_REL_ VPM_LS SG_ 2150268928 CldrMth_154 1;
BA_REL_ "GenSigSuprvResp" BU_SG_REL_ VIS2_LS SG_ 2150268928 CldrMth_154 1;
BA_REL_ "GenSigSuprvResp" BU_SG_REL_ FCM_LS SG_ 2150268928 CldrMth_154 1;
BA_REL_ "GenSigSuprvResp" BU_SG_REL_ BCM_LS SG_ 2150268928 CldrMth_154 1;
BA_REL_ "GenSigSuprvResp" BU_SG_REL_ EOCM_F_LS SG_ 2150268928 CldrMth_154 1;
BA_REL_ "GenSigSuprvResp" BU_SG_REL_ V2V_LS SG_ 2150268928 CldrDay_154 1;
BA_REL_ "GenSigSuprvResp" BU_SG_REL_ VPM_LS SG_ 2150268928 CldrDay_154 1;
BA_REL_ "GenSigSuprvResp" BU_SG_REL_ VIS2_LS SG_ 2150268928 CldrDay_154 1;
BA_REL_ "GenSigSuprvResp" BU_SG_REL_ FCM_LS SG_ 2150268928 CldrDay_154 1;
BA_REL_ "GenSigSuprvResp" BU_SG_REL_ BCM_LS SG_ 2150268928 CldrDay_154 1;
BA_REL_ "GenSigSuprvResp" BU_SG_REL_ EOCM_F_LS SG_ 2150268928 CldrDay_154 1;
BA_REL_ "GenSigSuprvResp" BU_SG_REL_ V2V_LS SG_ 2150268928 Sec 1;
BA_REL_ "GenSigSuprvResp" BU_SG_REL_ VPM_LS SG_ 2150268928 Sec 1;
BA_REL_ "GenSigSuprvResp" BU_SG_REL_ BCM_LS SG_ 2150268928 Sec 1;
BA_REL_ "GenSigSuprvResp" BU_SG_REL_ EOCM_F_LS SG_ 2150268928 Sec 1;
BA_REL_ "GenSigSuprvResp" BU_SG_REL_ V2V_LS SG_ 2150268928 Mins 1;
BA_REL_ "GenSigSuprvResp" BU_SG_REL_ VPM_LS SG_ 2150268928 Mins 1;
BA_REL_ "GenSigSuprvResp" BU_SG_REL_ BCM_LS SG_ 2150268928 Mins 1;
BA_REL_ "GenSigSuprvResp" BU_SG_REL_ EOCM_F_LS SG_ 2150268928 Mins 1;
BA_REL_ "GenSigSuprvResp" BU_SG_REL_ V2V_LS SG_ 2150268928 Hrs 1;
BA_REL_ "GenSigSuprvResp" BU_SG_REL_ VPM_LS SG_ 2150268928 Hrs 1;
BA_REL_ "GenSigSuprvResp" BU_SG_REL_ BCM_LS SG_ 2150268928 Hrs 1;
BA_REL_ "GenSigSuprvResp" BU_SG_REL_ EOCM_F_LS SG_ 2150268928 Hrs 1;
BA_REL_ "GenSigSuprvResp" BU_SG_REL_ PEPS_LS SG_ 2150137856 LMTTCPrsnOffStat 1;
BA_REL_ "GenSigSuprvResp" BU_SG_REL_ PEPS_LS SG_ 2150137856 FldTpMotReq 1;
BA_REL_ "GenSigSuprvResp" BU_SG_REL_ EOCM2A_K2_LS SG_ 2150776832 HybImpSnsDsbld 1;
BA_REL_ "GenSigSuprvResp" BU_SG_REL_ EOCM2B_K2_LS SG_ 2150776832 HybImpSnsDsbld 1;
BA_REL_ "GenSigSuprvResp" BU_SG_REL_ BCM_LS SG_ 2150776832 HybImpSnsDsbld 1;
BA_REL_ "GenSigSuprvResp" BU_SG_REL_ CGM_LS SG_ 2150776832 HybImpSnsDsbld 1;
BA_REL_ "GenSigSuprvResp" BU_SG_REL_ BSM_LS SG_ 2150776832 HybImpSnsDsbld 1;
BA_REL_ "GenSigTimeoutMsg" BU_SG_REL_ BSM_LS SG_ 2150776832 HybImpSnsDsbld -2144190464;
BA_REL_ "GenSigTimeoutTime" BU_SG_REL_ BSM_LS SG_ 2150776832 HybImpSnsDsbld 5000;
BA_REL_ "GenSigSuprvResp" BU_SG_REL_ VICM_LS SG_ 2150776832 HybImpSnsDsbld 1;
BA_REL_ "GenSigTimeoutMsg" BU_SG_REL_ VICM_LS SG_ 2150776832 HybImpSnsDsbld -2144190464;
BA_REL_ "GenSigTimeoutTime" BU_SG_REL_ VICM_LS SG_ 2150776832 HybImpSnsDsbld 5000;
BA_REL_ "GenSigSuprvResp" BU_SG_REL_ EOCM2A_K2_LS SG_ 2150776832 SftyMuteRd 1;
BA_REL_ "GenSigSuprvResp" BU_SG_REL_ EOCM2B_K2_LS SG_ 2150776832 SftyMuteRd 1;
BA_REL_ "GenSigSuprvResp" BU_SG_REL_ EOCM2A_K2_LS SG_ 2150776832 HybVehHiVltInvDisRqd 1;
BA_REL_ "GenSigSuprvResp" BU_SG_REL_ EOCM2B_K2_LS SG_ 2150776832 HybVehHiVltInvDisRqd 1;
BA_REL_ "GenSigSuprvResp" BU_SG_REL_ EOCM2A_K2_LS SG_ 2150776832 EvntEnbld 1;
BA_REL_ "GenSigSuprvResp" BU_SG_REL_ EOCM2B_K2_LS SG_ 2150776832 EvntEnbld 1;
BA_REL_ "GenSigSuprvResp" BU_SG_REL_ EOCM2A_K2_LS SG_ 2150776832 ShfUlkBrToShftIndCtrl 1;
BA_REL_ "GenSigSuprvResp" BU_SG_REL_ EOCM2B_K2_LS SG_ 2150776832 ShfUlkBrToShftIndCtrl 1;
BA_REL_ "GenSigSuprvResp" BU_SG_REL_ EOCM2A_K2_LS SG_ 2150776832 ShftLkdBuStbltIndCtrl 1;
BA_REL_ "GenSigSuprvResp" BU_SG_REL_ EOCM2B_K2_LS SG_ 2150776832 ShftLkdBuStbltIndCtrl 1;
BA_REL_ "GenSigSuprvResp" BU_SG_REL_ EOCM2A_K2_LS SG_ 2150776832 SbItlkTrnsShftLvLkRd 1;
BA_REL_ "GenSigSuprvResp" BU_SG_REL_ EOCM2B_K2_LS SG_ 2150776832 SbItlkTrnsShftLvLkRd 1;
BA_REL_ "GenSigSuprvResp" BU_SG_REL_ EOCM2A_K2_LS SG_ 2150776832 FrPsngrStOccSnsngPriDat 1;
BA_REL_ "GenSigSuprvResp" BU_SG_REL_ EOCM2B_K2_LS SG_ 2150776832 FrPsngrStOccSnsngPriDat 1;
BA_REL_ "GenSigSuprvResp" BU_SG_REL_ EOCM2A_K2_LS SG_ 2150776832 MmryRclImpctDisRq 1;
BA_REL_ "GenSigSuprvResp" BU_SG_REL_ EOCM2B_K2_LS SG_ 2150776832 MmryRclImpctDisRq 1;
BA_REL_ "GenSigSuprvResp" BU_SG_REL_ MSM_RR_LS SG_ 2150776832 MmryRclImpctDisRq 1;
BA_REL_ "GenSigSuprvResp" BU_SG_REL_ MSM_LR_LS SG_ 2150776832 MmryRclImpctDisRq 1;
BA_REL_ "GenSigSuprvResp" BU_SG_REL_ MSM_P_LS SG_ 2150776832 MmryRclImpctDisRq 1;
BA_REL_ "GenSigSuprvResp" BU_SG_REL_ MSM_LS SG_ 2150776832 MmryRclImpctDisRq 1;
BA_REL_ "GenSigSuprvResp" BU_SG_REL_ EOCM2A_K2_LS SG_ 2150776832 SIREvntSychCntr 1;
BA_REL_ "GenSigSuprvResp" BU_SG_REL_ TCP_LS SG_ 2150776832 SIREvntSychCntr 1;
BA_REL_ "GenSigSuprvResp" BU_SG_REL_ EOCM2B_K2_LS SG_ 2150776832 SIREvntSychCntr 1;
BA_REL_ "GenSigSuprvResp" BU_SG_REL_ ONSTAR_LS SG_ 2150776832 SIREvntSychCntr 1;
BA_REL_ "GenSigSuprvResp" BU_SG_REL_ EOCM_F_LS SG_ 2150776832 SIREvntSychCntr 1;
BA_REL_ "GenSigSuprvResp" BU_SG_REL_ EOCM2B_K2_LS SG_ 2150760448 NotSndRwRtSeatStat 1;
BA_REL_ "GenSigSuprvResp" BU_SG_REL_ EOCM2A_K2_LS SG_ 2150760448 NotSndRwRtSeatStat 1;
BA_REL_ "GenSigSuprvResp" BU_SG_REL_ EOCM2B_K2_LS SG_ 2150760448 NotSndRwMdlSeatStat 1;
BA_REL_ "GenSigSuprvResp" BU_SG_REL_ EOCM2A_K2_LS SG_ 2150760448 NotSndRwMdlSeatStat 1;
BA_REL_ "GenSigSuprvResp" BU_SG_REL_ EOCM2B_K2_LS SG_ 2150760448 NotSndRwLtSeatStat 1;
BA_REL_ "GenSigSuprvResp" BU_SG_REL_ EOCM2A_K2_LS SG_ 2150760448 NotSndRwLtSeatStat 1;
BA_REL_ "GenSigSuprvResp" BU_SG_REL_ EOCM2B_K2_LS SG_ 2150760448 NotPsSeatStat 1;
BA_REL_ "GenSigSuprvResp" BU_SG_REL_ EOCM2A_K2_LS SG_ 2150760448 NotPsSeatStat 1;
BA_REL_ "GenSigSuprvResp" BU_SG_REL_ EOCM2B_K2_LS SG_ 2150760448 NotDrvSeatStat 1;
BA_REL_ "GenSigSuprvResp" BU_SG_REL_ EOCM2A_K2_LS SG_ 2150760448 NotDrvSeatStat 1;
BA_REL_ "GenSigSuprvResp" BU_SG_REL_ EOCM2B_K2_LS SG_ 2150760448 NotSecRowRtSeaOccStat 1;
BA_REL_ "GenSigSuprvResp" BU_SG_REL_ EOCM2A_K2_LS SG_ 2150760448 NotSecRowRtSeaOccStat 1;
BA_REL_ "GenSigSuprvResp" BU_SG_REL_ EOCM2B_K2_LS SG_ 2150760448 NotSecRowLeSeaOccStat 1;
BA_REL_ "GenSigSuprvResp" BU_SG_REL_ EOCM2A_K2_LS SG_ 2150760448 NotSecRowLeSeaOccStat 1;
BA_REL_ "GenSigSuprvResp" BU_SG_REL_ EOCM2B_K2_LS SG_ 2150760448 NotSecRowCtSeaOccStat 1;
BA_REL_ "GenSigSuprvResp" BU_SG_REL_ EOCM2A_K2_LS SG_ 2150760448 NotSecRowCtSeaOccStat 1;
BA_REL_ "GenSigSuprvResp" BU_SG_REL_ EOCM2B_K2_LS SG_ 2150760448 NotiFrntPasSeatOccSta 1;
BA_REL_ "GenSigSuprvResp" BU_SG_REL_ EOCM2A_K2_LS SG_ 2150760448 NotiFrntPasSeatOccSta 1;
BA_REL_ "GenSigSuprvResp" BU_SG_REL_ VPM_LS SG_ 2150760448 NotEventStat 1;
BA_REL_ "GenSigSuprvResp" BU_SG_REL_ EOCM2B_K2_LS SG_ 2150760448 NotEventStat 1;
BA_REL_ "GenSigSuprvResp" BU_SG_REL_ EOCM2A_K2_LS SG_ 2150760448 NotEventStat 1;
BA_REL_ "GenSigSuprvResp" BU_SG_REL_ FCM_LS SG_ 2150760448 NotEventStat 1;
BA_REL_ "GenSigSuprvResp" BU_SG_REL_ EOCM_F_LS SG_ 2150760448 NotEventStat 1;
BA_REL_ "GenSigSuprvResp" BU_SG_REL_ EOCM2B_K2_LS SG_ 2150760448 NotiEventCount 1;
BA_REL_ "GenSigSuprvResp" BU_SG_REL_ EOCM2A_K2_LS SG_ 2150760448 NotiEventCount 1;
BA_REL_ "GenSigSuprvResp" BU_SG_REL_ FCM_LS SG_ 2150760448 NotiEventCount 1;
BA_REL_ "GenSigSuprvResp" BU_SG_REL_ EOCM_F_LS SG_ 2150760448 NotiEventCount 1;
BA_REL_ "GenSigSuprvResp" BU_SG_REL_ EOCM2B_K2_LS SG_ 2150760448 NESSRoSevSt 1;
BA_REL_ "GenSigSuprvResp" BU_SG_REL_ EOCM2A_K2_LS SG_ 2150760448 NESSRoSevSt 1;
BA_REL_ "GenSigSuprvResp" BU_SG_REL_ EOCM_F_LS SG_ 2150760448 NESSRoSevSt 1;
BA_REL_ "GenSigSuprvResp" BU_SG_REL_ EOCM2B_K2_LS SG_ 2150760448 NESSRiSiSevSt 1;
BA_REL_ "GenSigSuprvResp" BU_SG_REL_ EOCM2A_K2_LS SG_ 2150760448 NESSRiSiSevSt 1;
BA_REL_ "GenSigSuprvResp" BU_SG_REL_ EOCM_F_LS SG_ 2150760448 NESSRiSiSevSt 1;
BA_REL_ "GenSigSuprvResp" BU_SG_REL_ EOCM2B_K2_LS SG_ 2150760448 NESSReImpSevSt 1;
BA_REL_ "GenSigSuprvResp" BU_SG_REL_ EOCM2A_K2_LS SG_ 2150760448 NESSReImpSevSt 1;
BA_REL_ "GenSigSuprvResp" BU_SG_REL_ EOCM_F_LS SG_ 2150760448 NESSReImpSevSt 1;
BA_REL_ "GenSigSuprvResp" BU_SG_REL_ EOCM2B_K2_LS SG_ 2150760448 NESSLeSiSevSt 1;
BA_REL_ "GenSigSuprvResp" BU_SG_REL_ EOCM2A_K2_LS SG_ 2150760448 NESSLeSiSevSt 1;
BA_REL_ "GenSigSuprvResp" BU_SG_REL_ EOCM_F_LS SG_ 2150760448 NESSLeSiSevSt 1;
BA_REL_ "GenSigSuprvResp" BU_SG_REL_ EOCM2B_K2_LS SG_ 2150760448 NESSFrImpSt2SevSt 1;
BA_REL_ "GenSigSuprvResp" BU_SG_REL_ EOCM2A_K2_LS SG_ 2150760448 NESSFrImpSt2SevSt 1;
BA_REL_ "GenSigSuprvResp" BU_SG_REL_ EOCM_F_LS SG_ 2150760448 NESSFrImpSt2SevSt 1;
BA_REL_ "GenSigSuprvResp" BU_SG_REL_ EOCM2B_K2_LS SG_ 2150760448 NESSFrImpSt1SevSt 1;
BA_REL_ "GenSigSuprvResp" BU_SG_REL_ EOCM2A_K2_LS SG_ 2150760448 NESSFrImpSt1SevSt 1;
BA_REL_ "GenSigSuprvResp" BU_SG_REL_ EOCM_F_LS SG_ 2150760448 NESSFrImpSt1SevSt 1;
BA_REL_ "GenSigSuprvResp" BU_SG_REL_ EOCM2B_K2_LS SG_ 2150760448 NESSFrImpPreSevSt 1;
BA_REL_ "GenSigSuprvResp" BU_SG_REL_ EOCM2A_K2_LS SG_ 2150760448 NESSFrImpPreSevSt 1;
BA_REL_ "GenSigSuprvResp" BU_SG_REL_ EOCM_F_LS SG_ 2150760448 NESSFrImpPreSevSt 1;
BA_REL_ "GenSigSuprvResp" BU_SG_REL_ EOCM2B_K2_LS SG_ 2150760448 NEDLSRtSdArbgDld 1;
BA_REL_ "GenSigSuprvResp" BU_SG_REL_ EOCM2A_K2_LS SG_ 2150760448 NEDLSRtSdArbgDld 1;
BA_REL_ "GenSigSuprvResp" BU_SG_REL_ EOCM2B_K2_LS SG_ 2150760448 NEDLSLtSdArbgDld 1;
BA_REL_ "GenSigSuprvResp" BU_SG_REL_ EOCM2A_K2_LS SG_ 2150760448 NEDLSLtSdArbgDld 1;
BA_REL_ "GenSigSuprvResp" BU_SG_REL_ EOCM2B_K2_LS SG_ 2150760448 NEDLSSdCrtnArbgDpld 1;
BA_REL_ "GenSigSuprvResp" BU_SG_REL_ EOCM2A_K2_LS SG_ 2150760448 NEDLSSdCrtnArbgDpld 1;
BA_REL_ "GenSigSuprvResp" BU_SG_REL_ EOCM2B_K2_LS SG_ 2150760448 NEDLSPaFrSt2De 1;
BA_REL_ "GenSigSuprvResp" BU_SG_REL_ EOCM2A_K2_LS SG_ 2150760448 NEDLSPaFrSt2De 1;
BA_REL_ "GenSigSuprvResp" BU_SG_REL_ EOCM2B_K2_LS SG_ 2150760448 NEDLSPaFrSt1De 1;
BA_REL_ "GenSigSuprvResp" BU_SG_REL_ EOCM2A_K2_LS SG_ 2150760448 NEDLSPaFrSt1De 1;
BA_REL_ "GenSigSuprvResp" BU_SG_REL_ EOCM2B_K2_LS SG_ 2150760448 NEDLSDrFrSt2De 1;
BA_REL_ "GenSigSuprvResp" BU_SG_REL_ EOCM2A_K2_LS SG_ 2150760448 NEDLSDrFrSt2De 1;
BA_REL_ "GenSigSuprvResp" BU_SG_REL_ EOCM2B_K2_LS SG_ 2150760448 NEDLSDrFrSt1De 1;
BA_REL_ "GenSigSuprvResp" BU_SG_REL_ EOCM2A_K2_LS SG_ 2150760448 NEDLSDrFrSt1De 1;
BA_REL_ "GenSigSuprvResp" BU_SG_REL_ TCP_LS SG_ 2150760448 SIRDpl 1;
BA_REL_ "GenSigSuprvResp" BU_SG_REL_ EOCM2B_K2_LS SG_ 2150760448 SIRDpl 1;
BA_REL_ "GenSigSuprvResp" BU_SG_REL_ EOCM2A_K2_LS SG_ 2150760448 SIRDpl 1;
BA_REL_ "GenSigSuprvResp" BU_SG_REL_ V2V_LS SG_ 2150760448 SIRDpl 1;
BA_REL_ "GenSigSuprvResp" BU_SG_REL_ ICS_LS SG_ 2150760448 SIRDpl 1;
BA_REL_ "GenSigSuprvResp" BU_SG_REL_ EOCM_F_LS SG_ 2150760448 SIRDpl 1;
BA_REL_ "GenSigSuprvResp" BU_SG_REL_ OTIM_LS SG_ 2150760448 SIRDpl 1;
BA_REL_ "GenSigSuprvResp" BU_SG_REL_ ONSTAR_LS SG_ 2150760448 SIRDpl 1;
BA_REL_ "GenSigSuprvResp" BU_SG_REL_ RadioHead_LS SG_ 2150760448 SIRDpl 1;
BA_REL_ "GenSigSuprvResp" BU_SG_REL_ LCM_LS SG_ 2150760448 SIRDpl 1;
BA_REL_ "GenSigSuprvResp" BU_SG_REL_ PTM_LS SG_ 2150760448 SIRDpl 1;
BA_REL_ "GenSigSuprvResp" BU_SG_REL_ PEPS_LS SG_ 2150760448 SIRDpl 1;
BA_REL_ "GenSigSuprvResp" BU_SG_REL_ BCM_LS SG_ 2150760448 SIRDpl 1;
BA_REL_ "GenSigSuprvResp" BU_SG_REL_ BCM_LS SG_ 2150760448 SIRDpl 1;
BA_REL_ "GenSigSuprvResp" BU_SG_REL_ BCM_LS SG_ 2150760448 SIRDpl 1;
BA_REL_ "GenSigSuprvResp" BU_SG_REL_ BCM_LS SG_ 2150760448 SIRDpl 1;
BA_REL_ "GenSigSuprvResp" BU_SG_REL_ BCM_LS SG_ 2150760448 SIRDpl 1;
BA_REL_ "GenSigSuprvResp" BU_SG_REL_ BCM_LS SG_ 2150760448 SIRDpl 1;
BA_REL_ "GenSigSuprvResp" BU_SG_REL_ ECC_LS SG_ 2150760448 SIRDpl 1;
BA_REL_ "GenSigSuprvResp" BU_SG_REL_ ECC_LS SG_ 2150760448 SIRDpl 1;
BA_REL_ "GenSigSuprvResp" BU_SG_REL_ RadioHead_LS SG_ 2155872256 DrvStyPerfMdCsCrStVal 1;
BA_REL_ "GenSigSuprvResp" BU_SG_REL_ RadioHead_LS SG_ 2155872256 DrvStyPerfMdCsStAvl 1;
BA_REL_ "GenSigVBitResp" BU_SG_REL_ VPM_LS SG_ 2155872256 RdWhlAng 1;
BA_REL_ "GenSigVBitRespComment" BU_SG_REL_ VPM_LS SG_ 2155872256 RdWhlAng "RdWhlAngV";
BA_REL_ "GenSigSuprvResp" BU_SG_REL_ VPM_LS SG_ 2155872256 RdWhlAng 1;
BA_REL_ "GenSigSuprvResp" BU_SG_REL_ RadioHead_LS SG_ 2155872256 FlLvlPct 1;
BA_REL_ "GenSigSuprvResp" BU_SG_REL_ RadioHead_LS SG_ 2155872256 FlLvlPct 1;
BA_REL_ "GenSigVBitResp" BU_SG_REL_ IPC_LS SG_ 2155872256 FlLvlPct 1;
BA_REL_ "GenSigSuprvResp" BU_SG_REL_ EOCM2B_K1_LS SG_ 2156175360 NtVsnSysEnbld 1;
BA_REL_ "GenSigSuprvResp" BU_SG_REL_ EOCM2A_K1_LS SG_ 2156175360 NtVsnSysEnbld 1;
BA_REL_ "GenSigSuprvResp" BU_SG_REL_ EOCM2B_K1_LS SG_ 2156175360 DispMeasSysExt 1;
BA_REL_ "GenSigSuprvResp" BU_SG_REL_ EOCM2A_K1_LS SG_ 2156175360 DispMeasSysExt 1;
BA_REL_ "GenSigSuprvResp" BU_SG_REL_ V2V_LS SG_ 2156175360 DispMeasSysExt 1;
BA_REL_ "GenSigSuprvResp" BU_SG_REL_ EOCM2B_K1_LS SG_ 2156175360 DispMeasSys 1;
BA_REL_ "GenSigSuprvResp" BU_SG_REL_ EOCM2A_K1_LS SG_ 2156175360 DispMeasSys 1;
BA_REL_ "GenSigSuprvResp" BU_SG_REL_ FCM_LS SG_ 2156175360 DispMeasSys 1;
BA_REL_ "GenSigSuprvResp" BU_SG_REL_ V2V_LS SG_ 2156175360 DispMeasSys 1;
BA_REL_ "GenSigSuprvResp" BU_SG_REL_ EOCM_F_LS SG_ 2156175360 DispMeasSys 1;
BA_REL_ "GenSigSuprvResp" BU_SG_REL_ BCM_LS SG_ 2156175360 DispMeasSys 1;
VAL_ 2151235584 EhnSrvImmbComRst 1 "true" 0 "false" ;
VAL_ 2151235584 AlcKyIIncmIndOn 1 "true" 0 "false" ;
VAL_ 2151235584 VehSecAuthnSesComp 1 "true" 0 "false" ;
VAL_ 2151235584 VTDTmprDetected 1 "true" 0 "false" ;
VAL_ 2151235584 VehSecSysFldIO 1 "true" 0 "false" ;
VAL_ 2151235584 VehSecStrgColLckPwdV 1 "Invalid" 0 "Valid" ;
VAL_ 2151235584 VhSecNImmoIndRq 2 "Flashing Indication" 1 "Continuous Indication" 0 "No Indication" ;
VAL_ 2151235584 StrgColLckCmd 3 "Failure Code Retrieval Required" 2 "Lock" 1 "Unlock" 0 "No Command" ;
VAL_ 2151235584 DrIdDevLrnd 1 "Learned" 0 "Not Learned" ;
VAL_ 2151235584 IllDrIdDevDtctd 1 "true" 0 "false" ;
VAL_ 2151235584 EhnSrvEngImmStat 1 "Immobilized" 0 "Not Immobilized" ;
VAL_ 2151235584 ClmSysBkupFlrIndOn 1 "true" 0 "false" ;
VAL_ 2151235584 VehStatStAtv 1 "true" 0 "false" ;
VAL_ 2151202816 AuxHtrAlwd 1 "true" 0 "false" ;
VAL_ 2151202816 IPSnsrTpCvrTempFltd 1 "true" 0 "false" ;
VAL_ 2151202816 IPSnsrSolrAnglFltd 1 "true" 0 "false" ;
VAL_ 2151202816 IPSnsrRwSolrIntFltd 1 "true" 0 "false" ;
VAL_ 2151202816 ILSSCommErr 1 "Comm Error Detected" 0 "No Comm Error" ;
VAL_ 2151202816 RrWndDfgSwAtv 1 "true" 0 "false" ;
VAL_ 2151202816 RrWndDfgInhRq 1 "Inhibit rear window defog" 0 "Allow rear window defog" ;
VAL_ 2150825984 PdstIntdProtSysDplyd 1 "true" 0 "false" ;
VAL_ 2150825984 PdstIntdProtSysDsbld 1 "true" 0 "false" ;
VAL_ 2150825984 SrvIntdPdstProtSysIO 1 "true" 0 "false" ;
VAL_ 2150825984 FstnThrdRwRtPsStbtInR 3 "Unbuckled information indication" 2 "Buckled Indication" 1 "Unbuckled Indication" 0 "No Indication" ;
VAL_ 2150825984 FstnThrdRwLtPsStbtInR 3 "Unbuckled information indication" 2 "Buckled Indication" 1 "Unbuckled Indication" 0 "No Indication" ;
VAL_ 2150825984 FstnThrdRwCtPsStbtInR 3 "Unbuckled information indication" 2 "Buckled Indication" 1 "Unbuckled Indication" 0 "No Indication" ;
VAL_ 2150825984 FPSIC_IndPer 15 "8.0 s" 14 "7.0 s" 13 "6.0 s" 12 "5.0 s" 11 "4.0 s" 10 "3.5 s" 9 "3.0 s" 8 "2.5 s" 7 "2.0 s" 6 "1.75 s" 5 "1.50 s" 4 "1.25 s" 3 "1.0 s" 2 "0.75 s" 1 "0.5 s" 0 "0.25 s" ;
VAL_ 2150825984 FPSIC_IO 1 "true" 0 "false" ;
VAL_ 2150825984 FDSIC_IndPer 15 "8.0 s" 14 "7.0 s" 13 "6.0 s" 12 "5.0 s" 11 "4.0 s" 10 "3.5 s" 9 "3.0 s" 8 "2.5 s" 7 "2.0 s" 6 "1.75 s" 5 "1.50 s" 4 "1.25 s" 3 "1.0 s" 2 "0.75 s" 1 "0.5 s" 0 "0.25 s" ;
VAL_ 2150825984 FDSIC_IO 1 "true" 0 "false" ;
VAL_ 2150825984 AirbgFldIO 1 "true" 0 "false" ;
VAL_ 2150825984 SndRwStbltRdIndMd 0 "No Indication" 1 "Information Indication" 2 "Warning Indication" ;
VAL_ 2150825984 AirbgICIndPer 15 "8.0 s" 14 "7.0 s" 13 "6.0 s" 12 "5.0 s" 11 "4.0 s" 10 "3.5 s" 9 "3.0 s" 8 "2.5 s" 7 "2.0 s" 6 "1.75" 5 "1.5 s" 4 "1.25 s" 3 "1.0 s" 2 ".75 s" 1 ".5 s" 0 "0.25 s" ;
VAL_ 2150825984 AirbgICIO 1 "true" 0 "false" ;
VAL_ 2150825984 FstnSndRwRtPsStbtInR 3 "Unbuckled information indication" 2 "Buckled Indication" 1 "Unbuckled Indication" 0 "No Indication" ;
VAL_ 2150825984 FstnSndRwLtPsStbtInR 3 "Unbuckled information indication" 2 "Buckled Indication" 1 "Unbuckled Indication" 0 "No Indication" ;
VAL_ 2150825984 FstnSndRwCtPsStbtInR 3 "Unbuckled information indication" 2 "Buckled Indication" 1 "Unbuckled Indication" 0 "No Indication" ;
VAL_ 2150825984 FsnDrStbAuxIR 2 "Warning Level 2" 1 "Warning Level 1" 0 "No Indication" ;
VAL_ 2150825984 FsnPsStbAuxIR 4 "Child Warning Level 2" 3 "Child Warning Level 1" 2 "Adult Warning Level 2" 1 "Adult Warning Level 1" 0 "No Indication" ;
VAL_ 2151759872 RrClsRelRq 0 "No Activation" 1 "Release" ;
VAL_ 2151759872 CLRAF_UnandRsv3 1 "true" 0 "false" ;
VAL_ 2151759872 CLRAF_UnandRsv2 1 "true" 0 "false" ;
VAL_ 2151759872 CLRAF_UnandRsv1 1 "true" 0 "false" ;
VAL_ 2151759872 CLRAF_Unl_Lk 4 "Un-double Lock" 3 "Double Lock" 2 "Lock" 1 "Unlock" 0 "No Command" ;
VAL_ 2151759872 CLRAF_RRD 1 "true" 0 "false" ;
VAL_ 2151759872 CLRAF_RLD 1 "true" 0 "false" ;
VAL_ 2151759872 CLRAF_RrCls 1 "true" 0 "false" ;
VAL_ 2151759872 CLRAF_PD 1 "true" 0 "false" ;
VAL_ 2151759872 CLRAF_Hd 1 "true" 0 "false" ;
VAL_ 2151759872 CLRAF_FuelD 1 "true" 0 "false" ;
VAL_ 2151759872 CLRAF_DD 1 "true" 0 "false" ;
VAL_ 2151759872 CLRAF_ActFunc 11 "Exterior Lock Switch" 10 "Lockout Prevention" 9 "Re-locking" 8 "Delayed Locking" 7 "Enhanced Services/Telematics" 6 "Passive Remote Keyfob" 5 "Active Remote Keyfob" 4 "Emergency" 3 "Rr Closure Key Cylinder/Release Sw" 2 "Driver Door Key Cylinder" 1 "Power Door Lock Switch" 0 "Auto Door Lock" ;
VAL_ 2149974016 IntrSnsDisbld 1 "true" 0 "false" ;
VAL_ 2149974016 AlrmStat 4 "Arming Delay" 3 "Alarm Active" 2 "Disarmed" 1 "Armed" 0 "Off" ;
VAL_ 2149974016 AlrmTrggrdBattRcnctd 1 "true" 0 "false" ;
VAL_ 2149974016 AlrmTrgDrvDr 1 "true" 0 "false" ;
VAL_ 2149974016 AlrmTrgGlsBrkSns 1 "true" 0 "false" ;
VAL_ 2149974016 AlrmTrgHd 1 "true" 0 "false" ;
VAL_ 2149974016 AlrmTrgdIO 1 "true" 0 "false" ;
VAL_ 2149974016 AlrmTrgIntMvmntSns 1 "true" 0 "false" ;
VAL_ 2149974016 AlrmTrgNonOffPM 1 "true" 0 "false" ;
VAL_ 2149974016 AlrmTrgPsngDr 1 "true" 0 "false" ;
VAL_ 2149974016 AlrmTrgRrLftDr 1 "true" 0 "false" ;
VAL_ 2149974016 AlrmTrgRrRtDr 1 "true" 0 "false" ;
VAL_ 2149974016 AlrmTrgTltSns 1 "true" 0 "false" ;
VAL_ 2149974016 AlrmTrgTrnk 1 "true" 0 "false" ;
VAL_ 2149974016 SrvAlrmSysIO 1 "true" 0 "false" ;
VAL_ 2149974016 AlrmTrigMidClsr 1 "true" 0 "false" ;
VAL_ 2149974016 AlrmTrigTonn 1 "true" 0 "false" ;
VAL_ 2151907328 StrgWhlUnit1SwStat 15 "Function #F" 14 "Function #E" 13 "Function #D" 12 "Function #C" 11 "Function #B" 10 "Function #A" 9 "Function #9" 8 "Function #8" 7 "Function #7" 6 "Function #6" 5 "Function #5" 4 "Function #4" 3 "Function #3" 2 "Function #2" 1 "Function #1" 0 "No Activation" ;
VAL_ 2151907328 StrgWhlUnit2SwStat 15 "Function #F" 14 "Function #E" 13 "Function #D" 12 "Function #C" 11 "Function #B" 10 "Function #A" 9 "Function #9" 8 "Function #8" 7 "Function #7" 6 "Function #6" 5 "Function #5" 4 "Function #4" 3 "Function #3" 2 "Function #2" 1 "Function #1" 0 "No Activation" ;
VAL_ 2150219776 PhnSpRcgnRq 3 "Stop" 2 "Move On / Skip" 1 "Start" 0 "No Action" ;
VAL_ 2150219776 VcRecVcFdbckSt 1 "Active" 0 "Inactive" ;
VAL_ 2152685568 RadConInfReqSrc 2 "Infotainment Head" 1 "Rear Seat Entertainment" 0 "Voice Recognition System" ;
VAL_ 2152685568 RadBrdcstSrc 2 "FM" 1 "AM" 0 "Satellite Digital Audio Receiver" ;
VAL_ 2152685568 RadConInfCmd 3 "Purchase" 2 "Store" 1 "Mark" 0 "No Action" ;
VAL_ 2151874560 RstVTDTmprDtctd 1 "Reset" 0 "No Action" ;
VAL_ 2151874560 RstIllDrIdDevDtctd 1 "Reset" 0 "No Action" ;
VAL_ 2151874560 RstDrIdDevLrnd 1 "Reset" 0 "No Action" ;
VAL_ 2151874560 ESEIC_EngImmbRq 1 "Immobilize" 0 "Do Not Immobilize" ;
VAL_ 2150268928 EmrgncyRspSysTyp 7 "Ununsed and Reserved 1" 6 "Generic" 5 "ERA" 4 "ChevyStar" 3 "eCall" 2 "Onstar" 1 "None" 0 "Unknown" ;
VAL_ 2150268928 EmrgncyRspSysSrvIndOn 1 "true" 0 "false" ;
VAL_ 2150268928 CldrMth_154 12 "December" 11 "November" 10 "October" 9 "September" 8 "August" 7 "July" 6 "June" 5 "May" 4 "April" 3 "March" 2 "February" 1 "January" 0 "Unknown" ;
VAL_ 2150268928 SecV 1 "Invalid" 0 "Valid" ;
VAL_ 2150268928 MinsV 1 "Invalid" 0 "Valid" ;
VAL_ 2150268928 HrsV 1 "Invalid" 0 "Valid" ;
VAL_ 2150137856 LMTTCPrsnOffStat 1 "true" 0 "false" ;
VAL_ 2150137856 FldTpMotReq 0 "No Request" 1 "Stop Motion" 2 "Start Motion" 3 "Authentication Failed" ;
VAL_ 2150137856 KeyInWrnIO 1 "true" 0 "false" ;
VAL_ 2150137856 FobPrevLrndIndOn 1 "true" 0 "false" ;
VAL_ 2150137856 RemCtrlFobNumForProgER 0 "No Fob" 1 "Remote Control Fob #1" 2 "Remote Control Fob #2" 3 "Remote Control Fob #3" 4 "Remote Control Fob #4" 5 "Remote Control Fob #5" 6 "Remote Control Fob #6" 7 "Remote Control Fob #7" 8 "Remote Control Fob #8" 9 "Unused" 10 "Unused" 11 "Unused" 12 "Unused" 13 "Unused" 14 "Unused" 15 "Unused" ;
VAL_ 2150137856 FbProgCustActRqd 1 "true" 0 "false" ;
VAL_ 2150137856 Ky_IdDevNotPrIO 1 "true" 0 "false" ;
VAL_ 2150137856 VehSecAtoLrnAtv 1 "true" 0 "false" ;
VAL_ 2150137856 Ky_IdDevPrgmAuthReq 1 "true" 0 "false" ;
VAL_ 2151677952 SndLocRtRr 1 "true" 0 "false" ;
VAL_ 2151677952 SndLocLftRr 1 "true" 0 "false" ;
VAL_ 2151677952 SndLocPasFr 1 "true" 0 "false" ;
VAL_ 2151677952 SndLocDrFr 1 "true" 0 "false" ;
VAL_ 2151677952 SC_SndTne 10 "Beep (750 Hz) Radio Source Muted" 9 "High Frequency Broadband" 8 "Harp" 7 "Gong (2000 Hz)" 6 "Gong (750 Hz)" 5 "Beep (2000 Hz)" 4 "Beep (750 Hz)" 3 "Click-Clack" 2 "Click" 1 "Clack" 0 "Clock" 14 "No Chime with Radio Source Muted" 13 "Gong (2000 Hz) Radio Source Muted" 12 "Gong (750 Hz) Radio Source Muted" 11 "Beep (2000 Hz) Radio Source Muted" ;
VAL_ 2150776832 HybImpSnsDsbld 1 "true" 0 "false" ;
VAL_ 2150776832 SftyMuteRd 1 "true" 0 "false" ;
VAL_ 2150776832 HybVehHiVltInvDisRqd 1 "true" 0 "false" ;
VAL_ 2150776832 EvntEnbld 1 "true" 0 "false" ;
VAL_ 2150776832 ShfUlkBrToShftIndCtrl 1 "true" 0 "false" ;
VAL_ 2150776832 ShftLkdBuStbltIndCtrl 1 "true" 0 "false" ;
VAL_ 2150776832 SbItlkTrnsShftLvLkRd 1 "true" 0 "false" ;
VAL_ 2150776832 MmryRclImpctDisRq 1 "Disable Recall" 0 "Enable Recall" ;
VAL_ 2150760448 NotSndRwRtSeatStat 0 "Unknown" 1 "Unfastened" 2 "Fastened" ;
VAL_ 2150760448 NotSndRwMdlSeatStat 0 "Unknown" 1 "Unfastened" 2 "Fastened" ;
VAL_ 2150760448 NotSndRwLtSeatStat 0 "Unknown" 1 "Unfastened" 2 "Fastened" ;
VAL_ 2150760448 NotPsSeatStat 0 "Unknown" 1 "Unfastened" 2 "Fastened" ;
VAL_ 2150760448 NotDrvSeatStat 0 "Unknown" 1 "Unfastened" 2 "Fastened" ;
VAL_ 2150760448 NotSecRowRtSeaOccStat 2 "Occupied" 1 "Empty" 0 "Unknown" ;
VAL_ 2150760448 NotSecRowLeSeaOccStat 2 "Occupied" 1 "Empty" 0 "Unknown" ;
VAL_ 2150760448 NotSecRowCtSeaOccStat 2 "Occupied" 1 "Empty" 0 "Unknown" ;
VAL_ 2150760448 NotiFrntPasSeatOccSta 5 "OccupiedLarge" 4 "OccupiedSmall" 3 "OccupiedChildseat" 2 "OccupiedUnknown" 1 "Empty" 0 "Unknown" ;
VAL_ 2150760448 NotEventStat 2 "Pretensioner Deployment Event" 1 "Near Deployment Event" 0 "No Event" 3 "Airbag Deployment Event" ;
VAL_ 2150760448 NESSRoSevSt 1 "true" 0 "false" ;
VAL_ 2150760448 NESSRiSiSevSt 1 "true" 0 "false" ;
VAL_ 2150760448 NESSReImpSevSt 1 "true" 0 "false" ;
VAL_ 2150760448 NESSLeSiSevSt 1 "true" 0 "false" ;
VAL_ 2150760448 NESSFrImpSt2SevSt 1 "true" 0 "false" ;
VAL_ 2150760448 NESSFrImpSt1SevSt 1 "true" 0 "false" ;
VAL_ 2150760448 NESSFrImpPreSevSt 1 "true" 0 "false" ;
VAL_ 2150760448 NEDLSRtSdArbgDld 1 "true" 0 "false" ;
VAL_ 2150760448 NEDLSLtSdArbgDld 1 "true" 0 "false" ;
VAL_ 2150760448 NEDLSSdCrtnArbgDpld 1 "true" 0 "false" ;
VAL_ 2150760448 NEDLSPaFrSt2De 1 "true" 0 "false" ;
VAL_ 2150760448 NEDLSPaFrSt1De 1 "true" 0 "false" ;
VAL_ 2150760448 NEDLSDrFrSt2De 1 "true" 0 "false" ;
VAL_ 2150760448 NEDLSDrFrSt1De 1 "true" 0 "false" ;
VAL_ 2150760448 SIRDpl 1 "true" 0 "false" ;
VAL_ 2155872256 DrvStyPerfMdCsCrStVal 7 "Performance Mode 7" 6 "Performance Mode 6" 5 "Performance Mode 5" 4 "Performance Mode 4" 3 "Performance Mode 3" 2 "Performance Mode 2" 1 "Performance Mode 1" 0 "No Action" ;
VAL_ 2155872256 DrvStyPerfMdCsStAvl 1 "true" 0 "false" ;
VAL_ 2155872256 VehPitchAngleV 1 "Invalid" 0 "Valid" ;
VAL_ 2155872256 RdWhlAngV 1 "Invalid" 0 "Valid" ;
VAL_ 2155872256 FuelFltChgNwIO 1 "true" 0 "false" ;
VAL_ 2155872256 FlLvlPctV 1 "Invalid" 0 "Valid" ;
VAL_ 2155872256 FlInjRlCtRstOcc 1 "true" 0 "false" ;
VAL_ 2156175360 NtVsnSysEnbld 1 "true" 0 "false" ;
VAL_ 2156175360 DispMeasSysExt 2 "Imperial" 1 "US" 0 "Metric" ;
VAL_ 2156175360 DispMeasSys 1 "English" 0 "Metric" ;
SIG_GROUP_ 2150809600 ImpDltVlcSamp12 1 : IDVS12_Axis2 IDVS12_Axis1;
SIG_GROUP_ 2150809600 ImpDltVlcSamp13 1 : IDVS13_Axis2 IDVS13_Axis1;
SIG_GROUP_ 2150809600 ImpDltVlcSamp14 1 : IDVS14_Axis2 IDVS14_Axis1;
SIG_GROUP_ 2150809600 ImpDltVlcSamp15 1 : IDVS15_Axis2 IDVS15_Axis1;
SIG_GROUP_ 2150793216 ImpDltVlcSamp4 1 : IDVS4_Axis2 IDVS4_Axis1;
SIG_GROUP_ 2150793216 ImpDltVlcSamp5 1 : IDVS5_Axis2 IDVS5_Axis1;
SIG_GROUP_ 2150793216 ImpDltVlcSamp6 1 : IDVS6_Axis2 IDVS6_Axis1;
SIG_GROUP_ 2150793216 ImpDltVlcSamp7 1 : IDVS7_Axis2 IDVS7_Axis1;
SIG_GROUP_ 2150801408 ImpDltVlcSamp10 1 : IDVS10_Axis2 IDVS10_Axis1;
SIG_GROUP_ 2150801408 ImpDltVlcSamp11 1 : IDVS11_Axis2 IDVS11_Axis1;
SIG_GROUP_ 2150801408 ImpDltVlcSamp8 1 : IDVS8_Axis2 IDVS8_Axis1;
SIG_GROUP_ 2150801408 ImpDltVlcSamp9 1 : IDVS9_Axis2 IDVS9_Axis1;
SIG_GROUP_ 2150785024 ImpDltVlcSamp1 1 : IDVS1_Axis2 IDVS1_Axis1;
SIG_GROUP_ 2150785024 ImpDltVlcSamp2 1 : IDVS2_Axis2 IDVS2_Axis1;
SIG_GROUP_ 2150785024 ImpDltVlcSamp3 1 : IDVS3_Axis2 IDVS3_Axis1;
SIG_GROUP_ 2150825984 FsnPsngStbltIC 1 : FPSIC_IndPer FPSIC_IO FPSIC_IndDtCyc;
SIG_GROUP_ 2150825984 FsnDrvStbltIC 1 : FDSIC_IndPer FDSIC_IO FDSIC_IndDC;
SIG_GROUP_ 2150825984 AirbgIC 1 : AirbgICIndPer AirbgICDutCyc AirbgICIO;
SIG_GROUP_ 2151759872 CntrlLckRqwExtActFun 1 : CLRAF_UnandRsv3 CLRAF_UnandRsv2 CLRAF_UnandRsv1 CLRAF_Unl_Lk CLRAF_RRD CLRAF_RLD CLRAF_RrCls CLRAF_PD CLRAF_Hd CLRAF_FuelD CLRAF_DD CLRAF_ActFunc;
SIG_GROUP_ 2151874560 EhnSrvEngImmbCom 1 : ESEIC_EngImRqPsw ESEIC_EngImmbRq;
SIG_GROUP_ 2151677952 SndLoc 1 : SndLocRtRr SndLocLftRr SndLocPasFr SndLocDrFr;
SIG_GROUP_ 2151677952 SndChrs 1 : SC_SndDutCyc SC_NmofRp SC_SndCdnPrd SC_SndTne;
SIG_GROUP_ 2150760448 NoEvSevSt 1 : NESSRoSevSt NESSRiSiSevSt NESSReImpSevSt NESSLeSiSevSt NESSFrImpSt2SevSt NESSFrImpSt1SevSt NESSFrImpPreSevSt;
SIG_GROUP_ 2150760448 NoEvDeLoSt 1 : NEDLSRtSdArbgDld NEDLSLtSdArbgDld NEDLSSdCrtnArbgDpld NEDLSPaFrSt2De NEDLSPaFrSt1De NEDLSDrFrSt2De NEDLSDrFrSt1De;
